VERSION ""

NS_ :

BS_:

BU_: Turbocharger OnBoardDataLogger OffBoardDiagnosticTool2 OffBoardDiagnosticTool1 FileServer ParkingBrakeController SeatController2 FanDriveController SteeringColumnUnit CommunicationUnitRadio CommunicationUnitSatellite CommunicationUnitCellular PropulsionBatteryCharger ChassisController2 ChassisController1 EngineValveControl AuxiliaryHeater2 AuxiliaryHeater1 ClutchUnit RampControl InformationSystem1 SuspensionSystemController2 OilSensor VehicleDynamicStability ExhaustEmissionController TransmissionDisplay2 TransmissionDisplay1 ClimateControl2 WaterPumpController RearAxleSteeringController LightingOperatorControl SeatController1 IgnitionController2 IgnitionController1 TirePressureController CabController2 CabController1 PneumaticSystemController SuspensionSystemController1 HydraulicPumpController EnduranceBrakingSystem RetarderExhaustEngine2 OnBoardDiagnosticUnit HeadwayController RetarderExhaustEngine1 CabDisplay1 ManagementComputer VirtualTerminal OffVehicleGateway PowerTakeOffFront HitchControl AuxiliaryValveControl BodyController TractorTrailerBridge1 StarterSystem ElectricalSystem VehicleSecurity VehicleNavigation AerodynamicControl ElectricalChargingSystem ClimateControl1 TripRecorder InstrumentCluster SuspensionDriveAxle2 SuspensionDriveAxle1 SuspensionSteerAxle SteeringController FuelSystem CruiseControl RetarderDriveline RetarderEngine BrakesDriveAxle2 BrakesDriveAxle1 BrakesSystemController BrakesSteerAxle AxleDrive2 AxleDrive1 AxleSteering PowerTakeOff ShiftConsoleSecondary ShiftConsolePrimary Transmission2 Transmission1 Engine2 Engine1

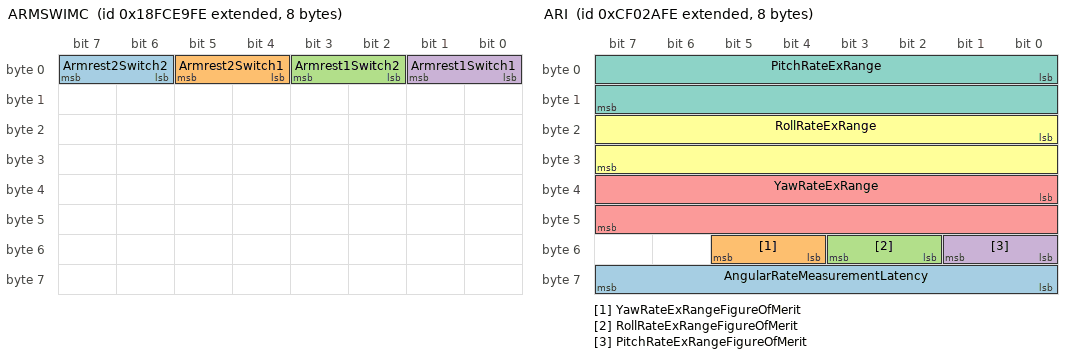
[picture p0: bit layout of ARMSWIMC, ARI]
BO_ 2566711806 ARMSWIMC: 8 Vector__XXX
 SG_ Armrest2Switch2 : 6|2@1+ (1,0) [0|3] "" Vector__XXX
 SG_ Armrest2Switch1 : 4|2@1+ (1,0) [0|3] "" Vector__XXX
 SG_ Armrest1Switch2 : 2|2@1+ (1,0) [0|3] "" Vector__XXX
 SG_ Armrest1Switch1 : 0|2@1+ (1,0) [0|3] "" Vector__XXX

BO_ 2364549886 ARI: 8 Vector__XXX
 SG_ AngularRateMeasurementLatency : 56|8@1+ (0.5,0) [0|125] "ms" Vector__XXX
 SG_ YawRateExRangeFigureOfMerit : 52|2@1+ (1,0) [0|3] "" Vector__XXX
 SG_ RollRateExRangeFigureOfMerit : 50|2@1+ (1,0) [0|3] "" Vector__XXX
 SG_ PitchRateExRangeFigureOfMerit : 48|2@1+ (1,0) [0|3] "" Vector__XXX
 SG_ YawRateExRange : 32|16@1+ (0.0078125,-250) [-250|250.992] "deg/sec" Vector__XXX
 SG_ RollRateExRange : 16|16@1+ (0.0078125,-250) [-250|250.992] "deg/sec" Vector__XXX
 SG_ PitchRateExRange : 0|16@1+ (0.0078125,-250) [-250|250.992] "deg/sec" Vector__XXX

BO_ 2566712318 AFT2NAI: 8 Vector__XXX
 SG_ Aftrtrtmnt2NOxAdsrbrDSOxRgnrtnSt : 2|2@1+ (1,0) [0|3] "" Vector__XXX
 SG_ Aftrtrtmnt2NOxAdsrbrDNOxRgnrtnSt : 0|2@1+ (1,0) [0|3] "" Vector__XXX

BO_ 2566712574 AFT1NAI: 8 Vector__XXX
 SG_ Aftrtrtmnt1NOxAdsrbrDSOxRgnrtnSt : 2|2@1+ (1,0) [0|3] "" Vector__XXX
 SG_ Aftrtrtmnt1NOxAdsrbrDNOxRgnrtnSt : 0|2@1+ (1,0) [0|3] "" Vector__XXX

BO_ 2164078590 A2SCRSI: 8 Vector__XXX
 SG_ Aftrtrtmnt2SCRCnvrsionEfficiency : 32|8@1+ (0.4,0) [0|100] "%" Vector__XXX
 SG_ Aftrtrtmnt2SCRCmmnddCtlystDslExh : 16|16@1+ (0.05,0) [0|3212.75] "L/h" Vector__XXX
 SG_ Aftrtrtmnt2DslExhstFldAvrgCnsmpt : 0|16@1+ (0.05,0) [0|3212.75] "L/h" Vector__XXX

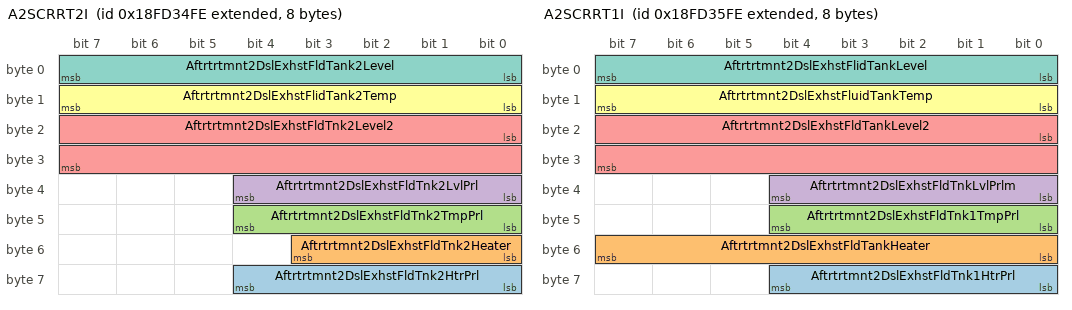
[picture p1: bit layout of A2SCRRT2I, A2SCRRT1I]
BO_ 2566731006 A2SCRRT2I: 8 Vector__XXX
 SG_ Aftrtrtmnt2DslExhstFldTnk2HtrPrl : 56|5@1+ (1,0) [0|31] "" Vector__XXX
 SG_ Aftrtrtmnt2DslExhstFldTnk2Heater : 48|4@1+ (1,0) [0|15] "" Vector__XXX
 SG_ Aftrtrtmnt2DslExhstFldTnk2TmpPrl : 40|5@1+ (1,0) [0|31] "" Vector__XXX
 SG_ Aftrtrtmnt2DslExhstFldTnk2LvlPrl : 32|5@1+ (1,0) [0|31] "" Vector__XXX
 SG_ Aftrtrtmnt2DslExhstFldTnk2Level2 : 16|16@1+ (0.1,0) [0|6425.5] "mm" Vector__XXX
 SG_ Aftrtrtmnt2DslExhstFlidTank2Temp : 8|8@1+ (1,-40) [-40|210] "deg C" Vector__XXX
 SG_ Aftrtrtmnt2DslExhstFldTank2Level : 0|8@1+ (0.4,0) [0|100] "%" Vector__XXX

BO_ 2566731262 A2SCRRT1I: 8 Vector__XXX
 SG_ Aftrtrtmnt2DslExhstFldTnk1HtrPrl : 56|5@1+ (1,0) [0|31] "" Vector__XXX
 SG_ Aftrtrtmnt2DslExhstFldTankHeater : 48|8@1+ (0.4,0) [0|100] "%" Vector__XXX
 SG_ Aftrtrtmnt2DslExhstFldTnk1TmpPrl : 40|5@1+ (1,0) [0|31] "" Vector__XXX
 SG_ Aftrtrtmnt2DslExhstFldTnkLvlPrlm : 32|5@1+ (1,0) [0|31] "" Vector__XXX
 SG_ Aftrtrtmnt2DslExhstFldTankLevel2 : 16|16@1+ (0.1,0) [0|6425.5] "mm" Vector__XXX
 SG_ Aftrtrtmnt2DslExhstFluidTankTemp : 8|8@1+ (1,-40) [-40|210] "deg C" Vector__XXX
 SG_ Aftrtrtmnt2DslExhstFlidTankLevel : 0|8@1+ (0.4,0) [0|100] "%" Vector__XXX

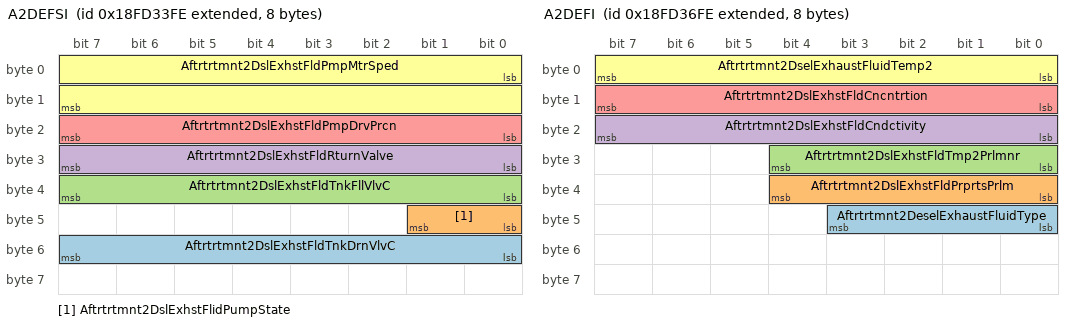
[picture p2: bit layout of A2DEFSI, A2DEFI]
BO_ 2566730750 A2DEFSI: 8 Vector__XXX
 SG_ Aftrtrtmnt2DslExhstFldTnkDrnVlvC : 48|8@1+ (0.4,0) [0|100] "%" Vector__XXX
 SG_ Aftrtrtmnt2DslExhstFlidPumpState : 40|2@1+ (1,0) [0|3] "" Vector__XXX
 SG_ Aftrtrtmnt2DslExhstFldTnkFllVlvC : 32|8@1+ (0.4,0) [0|100] "%" Vector__XXX
 SG_ Aftrtrtmnt2DslExhstFldRturnValve : 24|8@1+ (0.4,0) [0|100] "%" Vector__XXX
 SG_ Aftrtrtmnt2DslExhstFldPmpDrvPrcn : 16|8@1+ (0.4,0) [0|100] "%" Vector__XXX
 SG_ Aftrtrtmnt2DslExhstFldPmpMtrSped : 0|16@1+ (0.5,0) [0|32127.5] "rpm" Vector__XXX

BO_ 2566731518 A2DEFI: 8 Vector__XXX
 SG_ Aftrtrtmnt2DeselExhaustFluidType : 40|4@1+ (1,0) [0|15] "" Vector__XXX
 SG_ Aftrtrtmnt2DslExhstFldPrprtsPrlm : 32|5@1+ (1,0) [0|31] "" Vector__XXX
 SG_ Aftrtrtmnt2DslExhstFldTmp2Prlmnr : 24|5@1+ (1,0) [0|31] "" Vector__XXX
 SG_ Aftrtrtmnt2DslExhstFldCndctivity : 16|8@1+ (5,0) [0|1250] "microSiemens/mm" Vector__XXX
 SG_ Aftrtrtmnt2DslExhstFldCncntrtion : 8|8@1+ (0.25,0) [0|62.5] "%" Vector__XXX
 SG_ Aftrtrtmnt2DselExhaustFluidTemp2 : 0|8@1+ (1,-40) [-40|210] "deg C" Vector__XXX

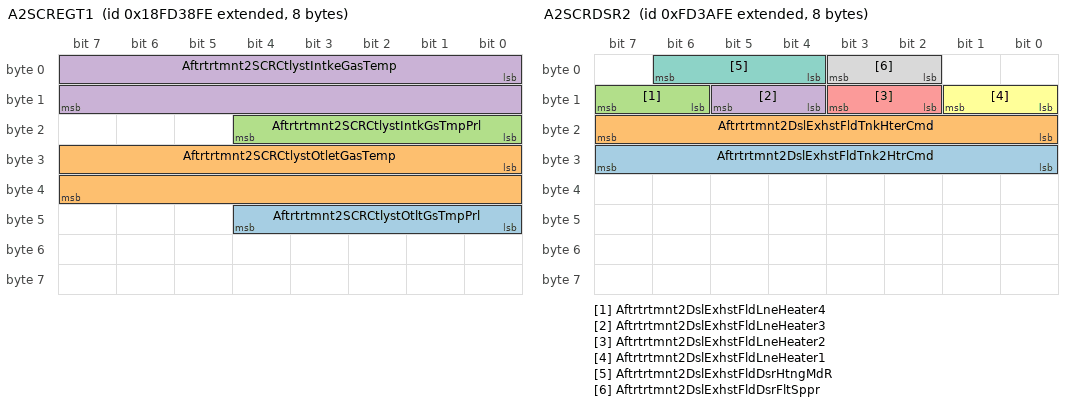
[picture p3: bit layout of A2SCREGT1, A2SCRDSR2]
BO_ 2566732030 A2SCREGT1: 8 Vector__XXX
 SG_ Aftrtrtmnt2SCRCtlystOtltGsTmpPrl : 40|5@1+ (1,0) [0|31] "" Vector__XXX
 SG_ Aftrtrtmnt2SCRCtlystOtletGasTemp : 24|16@1+ (0.03125,-273) [-273|1734.96875] "deg C" Vector__XXX
 SG_ Aftrtrtmnt2SCRCtlystIntkGsTmpPrl : 16|5@1+ (1,0) [0|31] "" Vector__XXX
 SG_ Aftrtrtmnt2SCRCtlystIntkeGasTemp : 0|16@1+ (0.03125,-273) [-273|1734.96875] "deg C" Vector__XXX

BO_ 2566732286 A2SCREGP: 8 Vector__XXX
 SG_ Aftrtrtmnt2SCRExhstGsDffPrssPrlm : 16|5@1+ (1,0) [0|31] "" Vector__XXX
 SG_ Aftrtrtmnt2SCRExhustGasDiffPress : 0|16@1+ (0.1,0) [0|6425.5] "kPa" Vector__XXX

BO_ 2164079358 A2SCRDSR2: 8 Vector__XXX
 SG_ Aftrtrtmnt2DslExhstFldTnk2HtrCmd : 24|8@1+ (0.4,0) [0|100] "%" Vector__XXX
 SG_ Aftrtrtmnt2DslExhstFldTnkHterCmd : 16|8@1+ (0.4,0) [0|100] "%" Vector__XXX
 SG_ Aftrtrtmnt2DslExhstFldLneHeater4 : 14|2@1+ (1,0) [0|3] "" Vector__XXX
 SG_ Aftrtrtmnt2DslExhstFldLneHeater3 : 12|2@1+ (1,0) [0|3] "" Vector__XXX
 SG_ Aftrtrtmnt2DslExhstFldLneHeater2 : 10|2@1+ (1,0) [0|3] "" Vector__XXX
 SG_ Aftrtrtmnt2DslExhstFldLneHeater1 : 8|2@1+ (1,0) [0|3] "" Vector__XXX
 SG_ Aftrtrtmnt2DslExhstFldDsrHtngMdR : 4|3@1+ (1,0) [0|7] "" Vector__XXX
 SG_ Aftrtrtmnt2DslExhstFldDsrFltSppr : 2|2@1+ (1,0) [0|3] "" Vector__XXX

BO_ 2364549118 A2SCRDSR1: 8 Vector__XXX
 SG_ Aftrtrtmnt2DslExhstFldRqstdQntty : 24|16@1+ (0.1,0) [0|6425.5] "g" Vector__XXX
 SG_ Aftrtrtmnt2SCRSystmRquestedState : 16|4@1+ (1,0) [0|15] "" Vector__XXX
 SG_ Aftrtrtmnt2DslExhstFldDsngRqstdQ : 0|16@1+ (0.3,0) [0|19276.5] "g/h" Vector__XXX

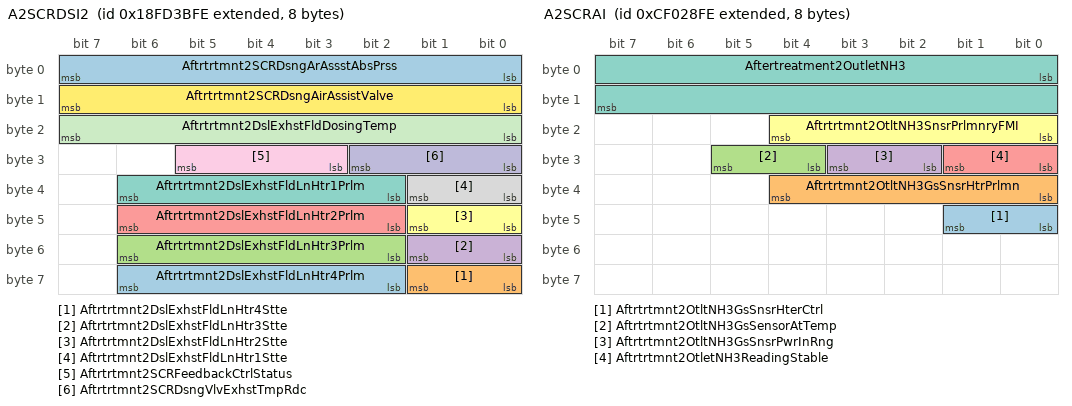
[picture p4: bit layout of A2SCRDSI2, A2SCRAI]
BO_ 2566732798 A2SCRDSI2: 8 Vector__XXX
 SG_ Aftrtrtmnt2DslExhstFldLnHtr4Prlm : 58|5@1+ (1,0) [0|31] "" Vector__XXX
 SG_ Aftrtrtmnt2DslExhstFldLnHtr4Stte : 56|2@1+ (1,0) [0|3] "" Vector__XXX
 SG_ Aftrtrtmnt2DslExhstFldLnHtr3Prlm : 50|5@1+ (1,0) [0|31] "" Vector__XXX
 SG_ Aftrtrtmnt2DslExhstFldLnHtr3Stte : 48|2@1+ (1,0) [0|3] "" Vector__XXX
 SG_ Aftrtrtmnt2DslExhstFldLnHtr2Prlm : 42|5@1+ (1,0) [0|31] "" Vector__XXX
 SG_ Aftrtrtmnt2DslExhstFldLnHtr2Stte : 40|2@1+ (1,0) [0|3] "" Vector__XXX
 SG_ Aftrtrtmnt2DslExhstFldLnHtr1Prlm : 34|5@1+ (1,0) [0|31] "" Vector__XXX
 SG_ Aftrtrtmnt2DslExhstFldLnHtr1Stte : 32|2@1+ (1,0) [0|3] "" Vector__XXX
 SG_ Aftrtrtmnt2SCRFeedbackCtrlStatus : 27|3@1+ (1,0) [0|7] "" Vector__XXX
 SG_ Aftrtrtmnt2SCRDsngVlvExhstTmpRdc : 24|3@1+ (1,0) [0|7] "" Vector__XXX
 SG_ Aftrtrtmnt2DslExhstFldDosingTemp : 16|8@1+ (1,-40) [-40|210] "deg C" Vector__XXX
 SG_ Aftrtrtmnt2SCRDsngAirAssistValve : 8|8@1+ (0.4,0) [0|100] "%" Vector__XXX
 SG_ Aftrtrtmnt2SCRDsngArAssstAbsPrss : 0|8@1+ (8,0) [0|2000] "kPa" Vector__XXX

BO_ 2364548862 A2SCRDSI1: 8 Vector__XXX
 SG_ Aftrtrtmnt2DslExhstFldDsngAbsPrs : 40|8@1+ (8,0) [0|2000] "kPa" Vector__XXX
 SG_ Aftrtrtmnt2DslExhstFldActlQnttyO : 24|16@1+ (0.1,0) [0|6425.5] "g" Vector__XXX
 SG_ Aftertreatment2SCRSystemState : 16|4@1+ (1,0) [0|15] "" Vector__XXX
 SG_ Aftrtrtmnt2DslExhstFldActlDsngQn : 0|16@1+ (0.3,0) [0|19276.5] "g/h" Vector__XXX

BO_ 2364549374 A2SCRAI: 8 Vector__XXX
 SG_ Aftrtrtmnt2OtltNH3GsSnsrHterCtrl : 40|2@1+ (1,0) [0|3] "" Vector__XXX
 SG_ Aftrtrtmnt2OtltNH3GsSnsrHtrPrlmn : 32|5@1+ (1,0) [0|31] "" Vector__XXX
 SG_ Aftrtrtmnt2OtltNH3GsSensorAtTemp : 28|2@1+ (1,0) [0|3] "" Vector__XXX
 SG_ Aftrtrtmnt2OtltNH3GsSnsrPwrInRng : 26|2@1+ (1,0) [0|3] "" Vector__XXX
 SG_ Aftrtrtmnt2OtletNH3ReadingStable : 24|2@1+ (1,0) [0|3] "" Vector__XXX
 SG_ Aftrtrtmnt2OtltNH3SnsrPrlmnryFMI : 16|5@1+ (1,0) [0|31] "" Vector__XXX
 SG_ Aftertreatment2OutletNH3 : 0|16@1+ (0.05,-200) [-200|3012.75] "ppm" Vector__XXX

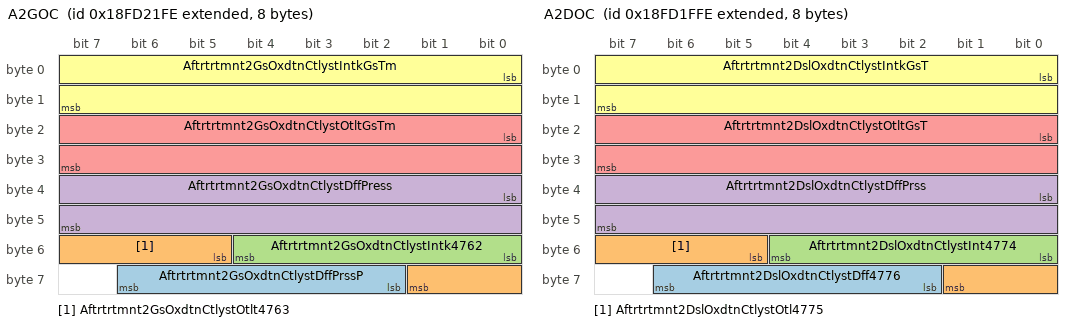
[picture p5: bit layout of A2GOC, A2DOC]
BO_ 2566726142 A2GOC: 8 Vector__XXX
 SG_ Aftrtrtmnt2GsOxdtnCtlystDffPrssP : 58|5@1+ (1,0) [0|31] "" Vector__XXX
 SG_ Aftrtrtmnt2GsOxdtnCtlystOtlt4763 : 53|5@1+ (1,0) [0|31] "" Vector__XXX
 SG_ Aftrtrtmnt2GsOxdtnCtlystIntk4762 : 48|5@1+ (1,0) [0|31] "" Vector__XXX
 SG_ Aftrtrtmnt2GsOxdtnCtlystDffPress : 32|16@1+ (0.1,0) [0|6425.5] "kPa" Vector__XXX
 SG_ Aftrtrtmnt2GsOxdtnCtlystOtltGsTm : 16|16@1+ (0.03125,-273) [-273|1734.96875] "deg C" Vector__XXX
 SG_ Aftrtrtmnt2GsOxdtnCtlystIntkGsTm : 0|16@1+ (0.03125,-273) [-273|1734.96875] "deg C" Vector__XXX

BO_ 2566725630 A2DOC: 8 Vector__XXX
 SG_ Aftrtrtmnt2DslOxdtnCtlystDff4776 : 58|5@1+ (1,0) [0|31] "" Vector__XXX
 SG_ Aftrtrtmnt2DslOxdtnCtlystOtl4775 : 53|5@1+ (1,0) [0|31] "" Vector__XXX
 SG_ Aftrtrtmnt2DslOxdtnCtlystInt4774 : 48|5@1+ (1,0) [0|31] "" Vector__XXX
 SG_ Aftrtrtmnt2DslOxdtnCtlystDffPrss : 32|16@1+ (0.5,0) [0|32127.5] "kPa" Vector__XXX
 SG_ Aftrtrtmnt2DslOxdtnCtlystOtltGsT : 16|16@1+ (0.03125,-273) [-273|1734.96875] "deg C" Vector__XXX
 SG_ Aftrtrtmnt2DslOxdtnCtlystIntkGsT : 0|16@1+ (0.03125,-273) [-273|1734.96875] "deg C" Vector__XXX

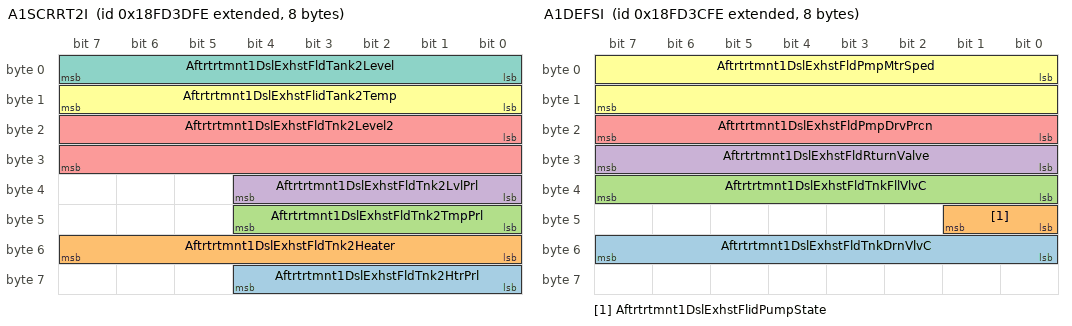
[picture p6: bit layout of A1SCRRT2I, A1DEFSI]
BO_ 2566733310 A1SCRRT2I: 8 Vector__XXX
 SG_ Aftrtrtmnt1DslExhstFldTnk2HtrPrl : 56|5@1+ (1,0) [0|31] "" Vector__XXX
 SG_ Aftrtrtmnt1DslExhstFldTnk2Heater : 48|8@1+ (0.4,0) [0|100] "%" Vector__XXX
 SG_ Aftrtrtmnt1DslExhstFldTnk2TmpPrl : 40|5@1+ (1,0) [0|31] "" Vector__XXX
 SG_ Aftrtrtmnt1DslExhstFldTnk2LvlPrl : 32|5@1+ (1,0) [0|31] "" Vector__XXX
 SG_ Aftrtrtmnt1DslExhstFldTnk2Level2 : 16|16@1+ (0.1,0) [0|6425.5] "mm" Vector__XXX
 SG_ Aftrtrtmnt1DslExhstFlidTank2Temp : 8|8@1+ (1,-40) [-40|210] "deg C" Vector__XXX
 SG_ Aftrtrtmnt1DslExhstFldTank2Level : 0|8@1+ (0.4,0) [0|100] "%" Vector__XXX

BO_ 2566733054 A1DEFSI: 8 Vector__XXX
 SG_ Aftrtrtmnt1DslExhstFldTnkDrnVlvC : 48|8@1+ (0.4,0) [0|100] "%" Vector__XXX
 SG_ Aftrtrtmnt1DslExhstFlidPumpState : 40|2@1+ (1,0) [0|3] "" Vector__XXX
 SG_ Aftrtrtmnt1DslExhstFldTnkFllVlvC : 32|8@1+ (0.4,0) [0|100] "%" Vector__XXX
 SG_ Aftrtrtmnt1DslExhstFldRturnValve : 24|8@1+ (0.4,0) [0|100] "%" Vector__XXX
 SG_ Aftrtrtmnt1DslExhstFldPmpDrvPrcn : 16|8@1+ (0.4,0) [0|100] "%" Vector__XXX
 SG_ Aftrtrtmnt1DslExhstFldPmpMtrSped : 0|16@1+ (0.5,0) [0|32127.5] "rpm" Vector__XXX

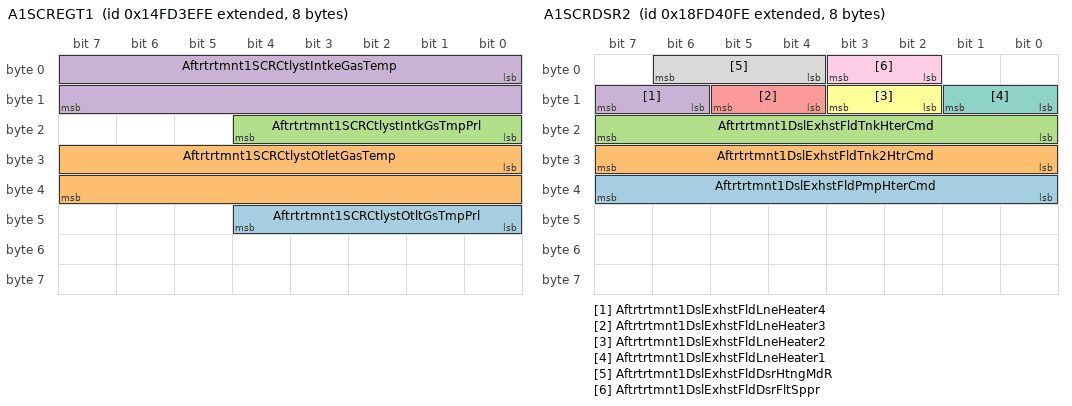
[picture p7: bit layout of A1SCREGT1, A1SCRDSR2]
BO_ 2499624702 A1SCREGT1: 8 Vector__XXX
 SG_ Aftrtrtmnt1SCRCtlystOtltGsTmpPrl : 40|5@1+ (1,0) [0|31] "" Vector__XXX
 SG_ Aftrtrtmnt1SCRCtlystOtletGasTemp : 24|16@1+ (0.03125,-273) [-273|1734.96875] "deg C" Vector__XXX
 SG_ Aftrtrtmnt1SCRCtlystIntkGsTmpPrl : 16|5@1+ (1,0) [0|31] "" Vector__XXX
 SG_ Aftrtrtmnt1SCRCtlystIntkeGasTemp : 0|16@1+ (0.03125,-273) [-273|1734.96875] "deg C" Vector__XXX

BO_ 2566733822 A1SCREGP: 8 Vector__XXX
 SG_ Aftrtrtmnt1SCRExhstGsDffPrssPrlm : 16|5@1+ (1,0) [0|31] "" Vector__XXX
 SG_ Aftrtrtmnt1SCRExhustGasDiffPress : 0|16@1+ (0.1,0) [0|6425.5] "kPa" Vector__XXX

BO_ 2566734078 A1SCRDSR2: 8 Vector__XXX
 SG_ Aftrtrtmnt1DslExhstFldPmpHterCmd : 32|8@1+ (0.4,0) [0|100] "%" Vector__XXX
 SG_ Aftrtrtmnt1DslExhstFldTnk2HtrCmd : 24|8@1+ (0.4,0) [0|100] "%" Vector__XXX
 SG_ Aftrtrtmnt1DslExhstFldTnkHterCmd : 16|8@1+ (0.4,0) [0|100] "%" Vector__XXX
 SG_ Aftrtrtmnt1DslExhstFldLneHeater4 : 14|2@1+ (1,0) [0|3] "" Vector__XXX
 SG_ Aftrtrtmnt1DslExhstFldLneHeater3 : 12|2@1+ (1,0) [0|3] "" Vector__XXX
 SG_ Aftrtrtmnt1DslExhstFldLneHeater2 : 10|2@1+ (1,0) [0|3] "" Vector__XXX
 SG_ Aftrtrtmnt1DslExhstFldLneHeater1 : 8|2@1+ (1,0) [0|3] "" Vector__XXX
 SG_ Aftrtrtmnt1DslExhstFldDsrHtngMdR : 4|3@1+ (1,0) [0|7] "" Vector__XXX
 SG_ Aftrtrtmnt1DslExhstFldDsrFltSppr : 2|2@1+ (1,0) [0|3] "" Vector__XXX

BO_ 2364548350 A1SCRDSR1: 8 Vector__XXX
 SG_ Aftrtrtmnt1DslExhstFldRqstdQntty : 24|16@1+ (0.1,0) [0|6425.5] "g" Vector__XXX
 SG_ Aftrtrtmnt1SCRSystmRquestedState : 16|4@1+ (1,0) [0|15] "" Vector__XXX
 SG_ Aftrtrtmnt1DslExhstFldDsngRqstdQ : 0|16@1+ (0.3,0) [0|19276.5] "g/h" Vector__XXX

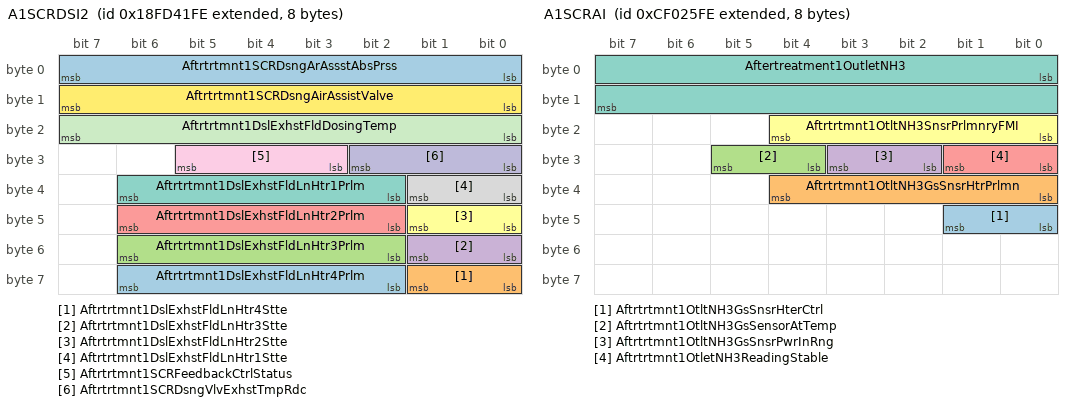
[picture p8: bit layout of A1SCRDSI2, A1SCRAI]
BO_ 2566734334 A1SCRDSI2: 8 Vector__XXX
 SG_ Aftrtrtmnt1DslExhstFldLnHtr4Prlm : 58|5@1+ (1,0) [0|31] "" Vector__XXX
 SG_ Aftrtrtmnt1DslExhstFldLnHtr4Stte : 56|2@1+ (1,0) [0|3] "" Vector__XXX
 SG_ Aftrtrtmnt1DslExhstFldLnHtr3Prlm : 50|5@1+ (1,0) [0|31] "" Vector__XXX
 SG_ Aftrtrtmnt1DslExhstFldLnHtr3Stte : 48|2@1+ (1,0) [0|3] "" Vector__XXX
 SG_ Aftrtrtmnt1DslExhstFldLnHtr2Prlm : 42|5@1+ (1,0) [0|31] "" Vector__XXX
 SG_ Aftrtrtmnt1DslExhstFldLnHtr2Stte : 40|2@1+ (1,0) [0|3] "" Vector__XXX
 SG_ Aftrtrtmnt1DslExhstFldLnHtr1Prlm : 34|5@1+ (1,0) [0|31] "" Vector__XXX
 SG_ Aftrtrtmnt1DslExhstFldLnHtr1Stte : 32|2@1+ (1,0) [0|3] "" Vector__XXX
 SG_ Aftrtrtmnt1SCRFeedbackCtrlStatus : 27|3@1+ (1,0) [0|7] "" Vector__XXX
 SG_ Aftrtrtmnt1SCRDsngVlvExhstTmpRdc : 24|3@1+ (1,0) [0|7] "" Vector__XXX
 SG_ Aftrtrtmnt1DslExhstFldDosingTemp : 16|8@1+ (1,-40) [-40|210] "deg C" Vector__XXX
 SG_ Aftrtrtmnt1SCRDsngAirAssistValve : 8|8@1+ (0.4,0) [0|100] "%" Vector__XXX
 SG_ Aftrtrtmnt1SCRDsngArAssstAbsPrss : 0|8@1+ (8,0) [0|2000] "kPa" Vector__XXX

BO_ 2364548094 A1SCRDSI1: 8 Vector__XXX
 SG_ Aftrtrtmnt1DslExhstFldDsrAbsPrss : 40|8@1+ (8,0) [0|2000] "kPa" Vector__XXX
 SG_ Aftrtrtmnt1DslExhstFldActlQnttyO : 24|16@1+ (0.1,0) [0|6425.5] "g" Vector__XXX
 SG_ Aftertreatment1SCRSystemState : 16|4@1+ (1,0) [0|15] "" Vector__XXX
 SG_ Aftrtrtmnt1DslExhstFldActlDsngQn : 0|16@1+ (0.3,0) [0|19276.5] "g/h" Vector__XXX

BO_ 2364548606 A1SCRAI: 8 Vector__XXX
 SG_ Aftrtrtmnt1OtltNH3GsSnsrHterCtrl : 40|2@1+ (1,0) [0|3] "" Vector__XXX
 SG_ Aftrtrtmnt1OtltNH3GsSnsrHtrPrlmn : 32|5@1+ (1,0) [0|31] "" Vector__XXX
 SG_ Aftrtrtmnt1OtltNH3GsSensorAtTemp : 28|2@1+ (1,0) [0|3] "" Vector__XXX
 SG_ Aftrtrtmnt1OtltNH3GsSnsrPwrInRng : 26|2@1+ (1,0) [0|3] "" Vector__XXX
 SG_ Aftrtrtmnt1OtletNH3ReadingStable : 24|2@1+ (1,0) [0|3] "" Vector__XXX
 SG_ Aftrtrtmnt1OtltNH3SnsrPrlmnryFMI : 16|5@1+ (1,0) [0|31] "" Vector__XXX
 SG_ Aftertreatment1OutletNH3 : 0|16@1+ (0.05,-200) [-200|3012.75] "ppm" Vector__XXX

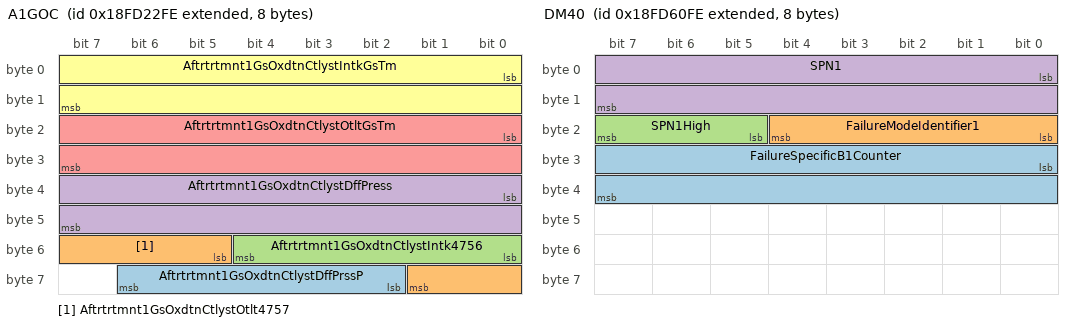
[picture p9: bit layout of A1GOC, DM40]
BO_ 2566726398 A1GOC: 8 Vector__XXX
 SG_ Aftrtrtmnt1GsOxdtnCtlystDffPrssP : 58|5@1+ (1,0) [0|31] "" Vector__XXX
 SG_ Aftrtrtmnt1GsOxdtnCtlystOtlt4757 : 53|5@1+ (1,0) [0|31] "" Vector__XXX
 SG_ Aftrtrtmnt1GsOxdtnCtlystIntk4756 : 48|5@1+ (1,0) [0|31] "" Vector__XXX
 SG_ Aftrtrtmnt1GsOxdtnCtlystDffPress : 32|16@1+ (0.1,0) [0|6425.5] "kPa" Vector__XXX
 SG_ Aftrtrtmnt1GsOxdtnCtlystOtltGsTm : 16|16@1+ (0.03125,-273) [-273|1734.96875] "deg C" Vector__XXX
 SG_ Aftrtrtmnt1GsOxdtnCtlystIntkGsTm : 0|16@1+ (0.03125,-273) [-273|1734.96875] "deg C" Vector__XXX

BO_ 2566742270 DM40: 8 Vector__XXX
 SG_ FailureSpecificB1Counter : 24|16@1+ (0.1,0) [0|6425.5] "hr" Vector__XXX
 SG_ FailureModeIdentifier1 : 16|5@1+ (1,0) [0|0] "" Vector__XXX
 SG_ SPN1High : 21|3@1+ (1,0) [0|7] "" Vector__XXX
 SG_ SPN1 : 0|16@1+ (1,0) [0|65536] "" Vector__XXX

BO_ 2566742526 DM39: 8 Vector__XXX
 SG_ SysGreatestB1Counter : 32|16@1+ (0.1,0) [0|6425.5] "hr" Vector__XXX
 SG_ SysCumulativeContinuousMITime : 0|32@1+ (0.05,0) [0|210554060.75] "hr" Vector__XXX

BO_ 2566742782 DM38: 8 Vector__XXX
 SG_ RegulationDescription : 0|8@1+ (1,0) [0|255] "" Vector__XXX

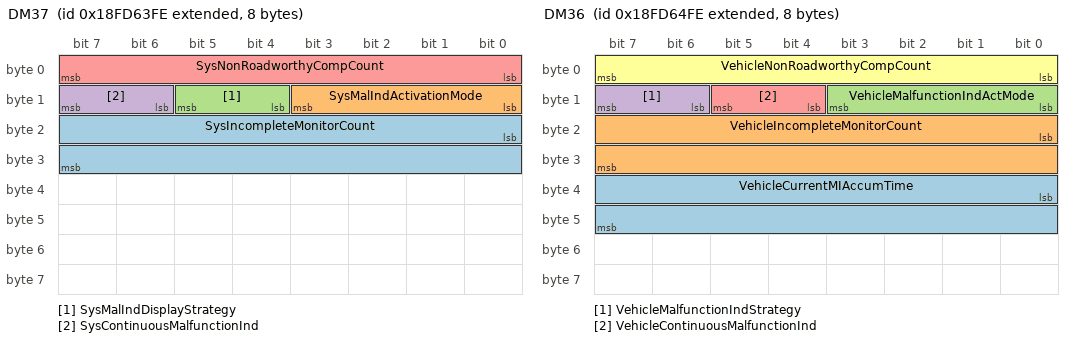
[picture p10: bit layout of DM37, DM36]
BO_ 2566743038 DM37: 8 Vector__XXX
 SG_ SysIncompleteMonitorCount : 16|16@1+ (1,0) [0|64512] "" Vector__XXX
 SG_ SysMalIndActivationMode : 8|4@1+ (1,0) [0|15] "" Vector__XXX
 SG_ SysMalIndDisplayStrategy : 12|2@1+ (1,0) [0|3] "" Vector__XXX
 SG_ SysContinuousMalfunctionInd : 14|2@1+ (1,0) [0|3] "" Vector__XXX
 SG_ SysNonRoadworthyCompCount : 0|8@1+ (1,0) [0|250] "" Vector__XXX

BO_ 2566743294 DM36: 8 Vector__XXX
 SG_ VehicleCurrentMIAccumTime : 32|16@1+ (1,0) [0|64255] "min" Vector__XXX
 SG_ VehicleIncompleteMonitorCount : 16|16@1+ (1,0) [0|64255] "" Vector__XXX
 SG_ VehicleMalfunctionIndActMode : 8|4@1+ (1,0) [0|15] "" Vector__XXX
 SG_ VehicleMalfunctionIndStrategy : 14|2@1+ (1,0) [0|3] "" Vector__XXX
 SG_ VehicleContinuousMalfunctionInd : 12|2@1+ (1,0) [0|3] "" Vector__XXX
 SG_ VehicleNonRoadworthyCompCount : 0|8@1+ (1,0) [0|250] "" Vector__XXX

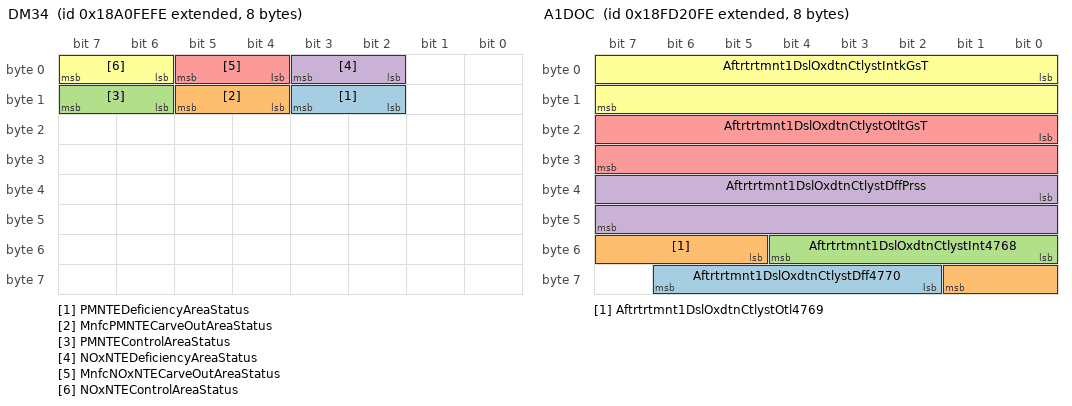
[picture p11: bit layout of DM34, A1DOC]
BO_ 2560687870 DM34: 8 Vector__XXX
 SG_ PMNTEDeficiencyAreaStatus : 10|2@1+ (1,0) [0|3] "" Vector__XXX
 SG_ MnfcPMNTECarveOutAreaStatus : 12|2@1+ (1,0) [0|3] "" Vector__XXX
 SG_ PMNTEControlAreaStatus : 14|2@1+ (1,0) [0|3] "" Vector__XXX
 SG_ NOxNTEDeficiencyAreaStatus : 2|2@1+ (1,0) [0|3] "" Vector__XXX
 SG_ MnfcNOxNTECarveOutAreaStatus : 4|2@1+ (1,0) [0|3] "" Vector__XXX
 SG_ NOxNTEControlAreaStatus : 6|2@1+ (1,0) [0|3] "" Vector__XXX

BO_ 2292317950 DM33: 9 Vector__XXX
 SG_ AECDEngineHours1Timer2 : 40|32@1+ (1,0) [0|4294967295] "min" Vector__XXX
 SG_ AECDEngineHours1Timer1 : 8|32@1+ (1,0) [0|4294967295] "min" Vector__XXX
 SG_ AECDNumber1 : 0|8@1+ (1,0) [0|250] "" Vector__XXX

BO_ 2566809342 BM: 8 Vector__XXX
 SG_ BatteryMainSwitchHoldState : 0|2@1+ (1,0) [0|3] "" Vector__XXX

BO_ 2365446910 BJM3: 8 Vector__XXX
 SG_ Joystick3XAxisDetentPosStatus : 38|2@1+ (1,0) [0|3] "" Vector__XXX
 SG_ Joystick3Button9PressedStatus : 62|2@1+ (1,0) [0|3] "" Vector__XXX
 SG_ Joystick3Button10PressedStatus : 60|2@1+ (1,0) [0|3] "" Vector__XXX
 SG_ Joystick3Button11PressedStatus : 58|2@1+ (1,0) [0|3] "" Vector__XXX
 SG_ Joystick3Button12PressedStatus : 56|2@1+ (1,0) [0|3] "" Vector__XXX
 SG_ Joystick3YAxisDetentPosStatus : 36|2@1+ (1,0) [0|3] "" Vector__XXX
 SG_ Joystick3YAxisPos : 22|10@1+ (0.1,0) [0|102] "%" Vector__XXX
 SG_ Jystck3YAxsLvrFrwrdPstvPosStatus : 20|2@1+ (1,0) [0|3] "" Vector__XXX
 SG_ Jystck3YAxsLvrBckNgtivePosStatus : 18|2@1+ (1,0) [0|3] "" Vector__XXX
 SG_ Joystick3YAxisNeutralPosStatus : 16|2@1+ (1,0) [0|3] "" Vector__XXX
 SG_ Joystick3XAxisPos : 6|10@1+ (0.1,0) [0|102] "%" Vector__XXX
 SG_ Jystck3XAxsLvrRghtPstvePosStatus : 4|2@1+ (1,0) [0|3] "" Vector__XXX
 SG_ Jystck3XAxsLvrLftNgtivePosStatus : 2|2@1+ (1,0) [0|3] "" Vector__XXX
 SG_ Joystick3XAxisNeutralPosStatus : 0|2@1+ (1,0) [0|3] "" Vector__XXX
 SG_ Joystick3Button5PressedStatus : 54|2@1+ (1,0) [0|3] "" Vector__XXX
 SG_ Joystick3Button6PressedStatus : 52|2@1+ (1,0) [0|3] "" Vector__XXX
 SG_ Joystick3Button7PressedStatus : 50|2@1+ (1,0) [0|3] "" Vector__XXX
 SG_ Joystick3Button8PressedStatus : 48|2@1+ (1,0) [0|3] "" Vector__XXX
 SG_ Joystick3Button1PressedStatus : 46|2@1+ (1,0) [0|3] "" Vector__XXX
 SG_ Joystick3Button2PressedStatus : 44|2@1+ (1,0) [0|3] "" Vector__XXX
 SG_ Joystick3Button3PressedStatus : 42|2@1+ (1,0) [0|3] "" Vector__XXX
 SG_ Joystick3Button4PressedStatus : 40|2@1+ (1,0) [0|3] "" Vector__XXX

BO_ 2365446398 BJM2: 8 Vector__XXX
 SG_ Joystick2XAxisDetentPosStatus : 38|2@1+ (1,0) [0|3] "" Vector__XXX
 SG_ Joystick2YAxisDetentPosStatus : 36|2@1+ (1,0) [0|3] "" Vector__XXX
 SG_ Joystick2YAxisPos : 22|10@1+ (0.1,0) [0|102] "%" Vector__XXX
 SG_ Jystck2YAxsLvrFrwrdPstvPosStatus : 20|2@1+ (1,0) [0|3] "" Vector__XXX
 SG_ Jystck2YAxsLvrBckNgtivePosStatus : 18|2@1+ (1,0) [0|3] "" Vector__XXX
 SG_ Joystick2YAxisNeutralPosStatus : 16|2@1+ (1,0) [0|3] "" Vector__XXX
 SG_ Joystick2XAxisPos : 6|10@1+ (0.1,0) [0|102] "%" Vector__XXX
 SG_ Jystck2XAxsLvrRghtPstvePosStatus : 4|2@1+ (1,0) [0|3] "" Vector__XXX
 SG_ Jystck2XAxsLvrLftNgtivePosStatus : 2|2@1+ (1,0) [0|3] "" Vector__XXX
 SG_ Joystick2XAxisNeutralPosStatus : 0|2@1+ (1,0) [0|3] "" Vector__XXX
 SG_ Joystick2Button9PressedStatus : 62|2@1+ (1,0) [0|3] "" Vector__XXX
 SG_ Joystick2Button10PressedStatus : 60|2@1+ (1,0) [0|3] "" Vector__XXX
 SG_ Joystick2Button11PressedStatus : 58|2@1+ (1,0) [0|3] "" Vector__XXX
 SG_ Joystick2Button12PressedStatus : 56|2@1+ (1,0) [0|3] "" Vector__XXX
 SG_ Joystick2Button5PressedStatus : 54|2@1+ (1,0) [0|3] "" Vector__XXX
 SG_ Joystick2Button6PressedStatus : 52|2@1+ (1,0) [0|3] "" Vector__XXX
 SG_ Joystick2Button7PressedStatus : 50|2@1+ (1,0) [0|3] "" Vector__XXX
 SG_ Joystick2Button8PressedStatus : 48|2@1+ (1,0) [0|3] "" Vector__XXX
 SG_ Joystick2Button1PressedStatus : 46|2@1+ (1,0) [0|3] "" Vector__XXX
 SG_ Joystick2Button2PressedStatus : 44|2@1+ (1,0) [0|3] "" Vector__XXX
 SG_ Joystick2Button3PressedStatus : 42|2@1+ (1,0) [0|3] "" Vector__XXX
 SG_ Joystick2Button4PressedStatus : 40|2@1+ (1,0) [0|3] "" Vector__XXX

BO_ 2365445886 BJM1: 8 Vector__XXX
 SG_ Joystick1XAxisDetentPosStatus : 38|2@1+ (1,0) [0|3] "" Vector__XXX
 SG_ Joystick1YAxisDetentPosStatus : 36|2@1+ (1,0) [0|3] "" Vector__XXX
 SG_ Joystick1YAxisPos : 22|10@1+ (0.1,0) [0|102] "%" Vector__XXX
 SG_ Jystck1YAxsLvrFrwrdPstvPosStatus : 20|2@1+ (1,0) [0|3] "" Vector__XXX
 SG_ Jystck1YAxsLvrBckNgtivePosStatus : 18|2@1+ (1,0) [0|3] "" Vector__XXX
 SG_ Joystick1YAxisNeutralPosStatus : 16|2@1+ (1,0) [0|3] "" Vector__XXX
 SG_ Joystick1XAxisPos : 6|10@1+ (0.1,0) [0|102] "%" Vector__XXX
 SG_ Joystick1Button9PressedStatus : 62|2@1+ (1,0) [0|3] "" Vector__XXX
 SG_ Joystick1Button10PressedStatus : 60|2@1+ (1,0) [0|3] "" Vector__XXX
 SG_ Joystick1Button11PressedStatus : 58|2@1+ (1,0) [0|3] "" Vector__XXX
 SG_ Joystick1Button12PressedStatus : 56|2@1+ (1,0) [0|3] "" Vector__XXX
 SG_ Joystick1Button5PressedStatus : 54|2@1+ (1,0) [0|3] "" Vector__XXX
 SG_ Joystick1Button6PressedStatus : 52|2@1+ (1,0) [0|3] "" Vector__XXX
 SG_ Joystick1Button7PressedStatus : 50|2@1+ (1,0) [0|3] "" Vector__XXX
 SG_ Joystick1Button8PressedStatus : 48|2@1+ (1,0) [0|3] "" Vector__XXX
 SG_ Joystick1Button1PressedStatus : 46|2@1+ (1,0) [0|3] "" Vector__XXX
 SG_ Joystick1Button2PressedStatus : 44|2@1+ (1,0) [0|3] "" Vector__XXX
 SG_ Joystick1Button3PressedStatus : 42|2@1+ (1,0) [0|3] "" Vector__XXX
 SG_ Joystick1Button4PressedStatus : 40|2@1+ (1,0) [0|3] "" Vector__XXX
 SG_ Jystck1XAxsLvrRghtPstvePosStatus : 4|2@1+ (1,0) [0|3] "" Vector__XXX
 SG_ Jystck1XAxsLvrLftNgtivePosStatus : 2|2@1+ (1,0) [0|3] "" Vector__XXX
 SG_ Joystick1XAxisNeutralPosStatus : 0|2@1+ (1,0) [0|3] "" Vector__XXX

BO_ 2566847230 B: 8 Vector__XXX
 SG_ ParkingBrakeRedWarningSignal : 26|2@1+ (1,0) [0|3] "" Vector__XXX
 SG_ ParkBrakeReleaseInhibitStatus : 28|2@1+ (1,0) [0|3] "" Vector__XXX
 SG_ ParkingBrakeActuator : 24|2@1+ (1,0) [0|3] "" Vector__XXX
 SG_ BrakeSecondPress : 16|8@1+ (4,0) [0|1000] "kPa" Vector__XXX
 SG_ BrakePrimaryPress : 8|8@1+ (4,0) [0|1000] "kPa" Vector__XXX
 SG_ BrakeAppPress : 0|8@1+ (4,0) [0|1000] "kPa" Vector__XXX

BO_ 2566848254 AWPP: 8 Vector__XXX
 SG_ AuxPumpPress : 0|8@1+ (16,0) [0|4000] "kPa" Vector__XXX

BO_ 2566725886 A1DOC: 8 Vector__XXX
 SG_ Aftrtrtmnt1DslOxdtnCtlystDff4770 : 58|5@1+ (1,0) [0|31] "" Vector__XXX
 SG_ Aftrtrtmnt1DslOxdtnCtlystOtl4769 : 53|5@1+ (1,0) [0|31] "" Vector__XXX
 SG_ Aftrtrtmnt1DslOxdtnCtlystInt4768 : 48|5@1+ (1,0) [0|31] "" Vector__XXX
 SG_ Aftrtrtmnt1DslOxdtnCtlystDffPrss : 32|16@1+ (0.1,0) [0|6425.5] "kPa" Vector__XXX
 SG_ Aftrtrtmnt1DslOxdtnCtlystOtltGsT : 16|16@1+ (0.03125,-273) [-273|1734.96875] "deg C" Vector__XXX
 SG_ Aftrtrtmnt1DslOxdtnCtlystIntkGsT : 0|16@1+ (0.03125,-273) [-273|1734.96875] "deg C" Vector__XXX

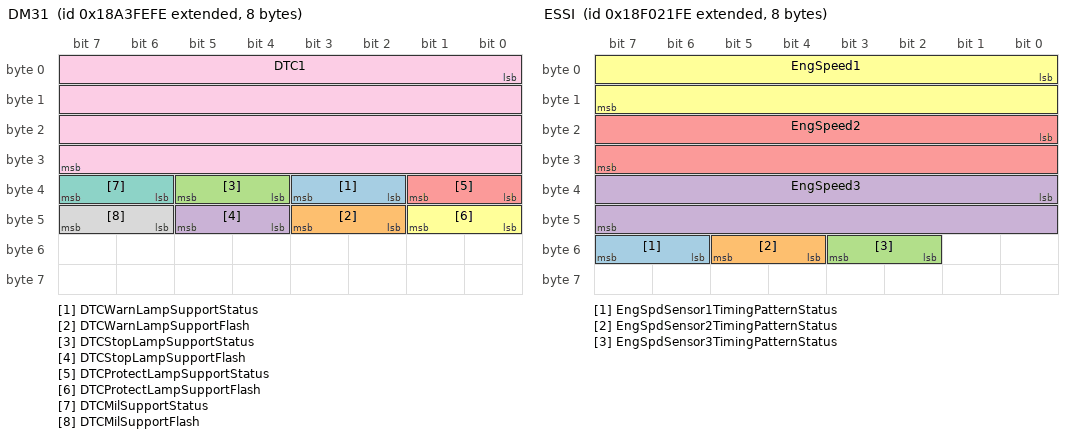
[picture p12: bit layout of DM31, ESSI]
BO_ 2560884478 DM31: 8 Vector__XXX
 SG_ DTCWarnLampSupportStatus : 34|2@1+ (1,0) [0|3] "" Vector__XXX
 SG_ DTCWarnLampSupportFlash : 42|2@1+ (1,0) [0|3] "" Vector__XXX
 SG_ DTCStopLampSupportStatus : 36|2@1+ (1,0) [0|3] "" Vector__XXX
 SG_ DTCStopLampSupportFlash : 44|2@1+ (1,0) [0|3] "" Vector__XXX
 SG_ DTCProtectLampSupportStatus : 32|2@1+ (1,0) [0|3] "" Vector__XXX
 SG_ DTCProtectLampSupportFlash : 40|2@1+ (1,0) [0|3] "" Vector__XXX
 SG_ DTCMilSupportStatus : 38|2@1+ (1,0) [0|3] "" Vector__XXX
 SG_ DTCMilSupportFlash : 46|2@1+ (1,0) [0|3] "" Vector__XXX
 SG_ DTC1 : 0|32@1+ (1,0) [0|4294967295] "" Vector__XXX

BO_ 2633844734 TML: 8 Vector__XXX

BO_ 2560360190 PMI: 8 Vector__XXX
 SG_ DataDictionaryMethod : 11|21@1+ (1,0) [0|2097151] "" Vector__XXX
 SG_ DataDictionaryManufacturerCode : 0|11@1+ (1,0) [0|2047] "" Vector__XXX

BO_ 2566736126 O2FT2: 8 Vector__XXX
 SG_ EngExhstGsOxygnSnsrClsdLpOprtnBn : 32|4@1+ (1,0) [0|15] "" Vector__XXX
 SG_ ShorttermFuelTrimBank2 : 16|16@1+ (0.1,-100) [-100|100] "%" Vector__XXX
 SG_ LongtermFuelTrimBank2 : 0|16@1+ (0.1,-100) [-100|100] "%" Vector__XXX

BO_ 2566736382 O2FT1: 8 Vector__XXX
 SG_ EngExhstGsOxygnSnsrClsdLpOprtnBn : 32|4@1+ (1,0) [0|15] "" Vector__XXX
 SG_ ShorttermFuelTrimBank1 : 16|16@1+ (0.1,-100) [-100|100] "%" Vector__XXX
 SG_ LongtermFuelTrimBank1 : 0|16@1+ (0.1,-100) [-100|100] "%" Vector__XXX

BO_ 2565874174 ESSI: 8 Vector__XXX
 SG_ EngSpdSensor1TimingPatternStatus : 54|2@1+ (1,0) [0|3] "" Vector__XXX
 SG_ EngSpdSensor2TimingPatternStatus : 52|2@1+ (1,0) [0|3] "" Vector__XXX
 SG_ EngSpdSensor3TimingPatternStatus : 50|2@1+ (1,0) [0|3] "" Vector__XXX
 SG_ EngSpeed3 : 32|16@1+ (0.5,0) [0|32127.5] "rpm" Vector__XXX
 SG_ EngSpeed2 : 16|16@1+ (0.5,0) [0|32127.5] "rpm" Vector__XXX
 SG_ EngSpeed1 : 0|16@1+ (0.5,0) [0|32127.5] "rpm" Vector__XXX

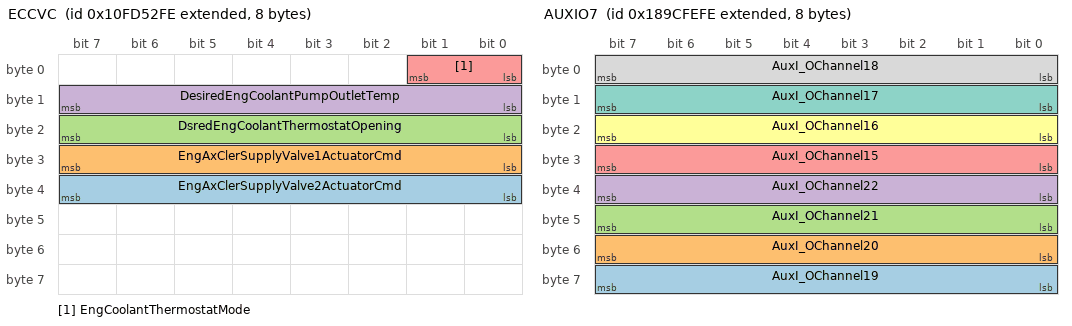
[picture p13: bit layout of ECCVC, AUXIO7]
BO_ 2432520958 ECCVC: 8 Vector__XXX
 SG_ EngAxClerSupplyValve2ActuatorCmd : 32|8@1+ (0.4,0) [0|100] "%" Vector__XXX
 SG_ EngAxClerSupplyValve1ActuatorCmd : 24|8@1+ (0.4,0) [0|100] "%" Vector__XXX
 SG_ DsredEngCoolantThermostatOpening : 16|8@1+ (0.4,0) [0|100] "%" Vector__XXX
 SG_ DesiredEngCoolantPumpOutletTemp : 8|8@1+ (1,-40) [-40|210] "deg C" Vector__XXX
 SG_ EngCoolantThermostatMode : 0|2@1+ (1,0) [0|3] "" Vector__XXX

BO_ 2560425726 AUXIO7: 8 Vector__XXX
 SG_ AuxI_OChannel19 : 56|8@1+ (1,0) [0|250] "" Vector__XXX
 SG_ AuxI_OChannel20 : 48|8@1+ (1,0) [0|250] "" Vector__XXX
 SG_ AuxI_OChannel21 : 40|8@1+ (1,0) [0|250] "" Vector__XXX
 SG_ AuxI_OChannel22 : 32|8@1+ (1,0) [0|250] "" Vector__XXX
 SG_ AuxI_OChannel15 : 24|8@1+ (1,0) [0|250] "" Vector__XXX
 SG_ AuxI_OChannel16 : 16|8@1+ (1,0) [0|250] "" Vector__XXX
 SG_ AuxI_OChannel17 : 8|8@1+ (1,0) [0|250] "" Vector__XXX
 SG_ AuxI_OChannel18 : 0|8@1+ (1,0) [0|250] "" Vector__XXX

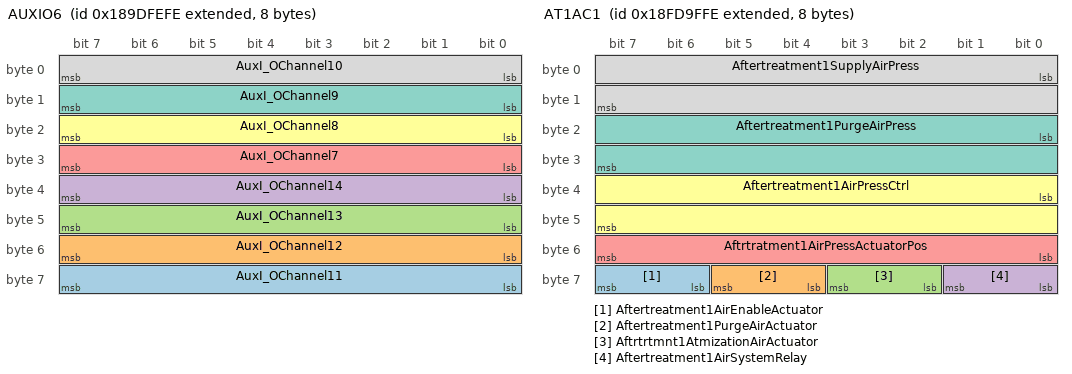
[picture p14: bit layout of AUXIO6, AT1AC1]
BO_ 2560491262 AUXIO6: 8 Vector__XXX
 SG_ AuxI_OChannel11 : 56|8@1+ (1,0) [0|250] "" Vector__XXX
 SG_ AuxI_OChannel12 : 48|8@1+ (1,0) [0|250] "" Vector__XXX
 SG_ AuxI_OChannel13 : 40|8@1+ (1,0) [0|250] "" Vector__XXX
 SG_ AuxI_OChannel14 : 32|8@1+ (1,0) [0|250] "" Vector__XXX
 SG_ AuxI_OChannel7 : 24|8@1+ (1,0) [0|250] "" Vector__XXX
 SG_ AuxI_OChannel8 : 16|8@1+ (1,0) [0|250] "" Vector__XXX
 SG_ AuxI_OChannel9 : 8|8@1+ (1,0) [0|250] "" Vector__XXX
 SG_ AuxI_OChannel10 : 0|8@1+ (1,0) [0|250] "" Vector__XXX

BO_ 2349399806 AUXIO5: 8 Vector__XXX
 SG_ AuxI_OChannel3 : 48|16@1+ (1,0) [0|64255] "" Vector__XXX
 SG_ AuxI_OChannel4 : 32|16@1+ (1,0) [0|64255] "" Vector__XXX
 SG_ AuxI_OChannel5 : 16|16@1+ (1,0) [0|64255] "" Vector__XXX
 SG_ AuxI_OChannel6 : 0|16@1+ (1,0) [0|64255] "" Vector__XXX

BO_ 2566758398 AT1AC1: 8 Vector__XXX
 SG_ Aftertreatment1AirEnableActuator : 62|2@1+ (1,0) [0|3] "" Vector__XXX
 SG_ Aftertreatment1PurgeAirActuator : 60|2@1+ (1,0) [0|3] "" Vector__XXX
 SG_ Aftrtrtmnt1AtmizationAirActuator : 58|2@1+ (1,0) [0|3] "" Vector__XXX
 SG_ Aftertreatment1AirSystemRelay : 56|2@1+ (1,0) [0|3] "" Vector__XXX
 SG_ Aftrtratment1AirPressActuatorPos : 48|8@1+ (0.4,0) [0|100] "%" Vector__XXX
 SG_ Aftertreatment1AirPressCtrl : 32|16@1+ (0.0025,0) [0|160.6375] "%" Vector__XXX
 SG_ Aftertreatment1PurgeAirPress : 16|16@1+ (0.1,0) [0|6425.5] "kPa" Vector__XXX
 SG_ Aftertreatment1SupplyAirPress : 0|16@1+ (0.1,0) [0|6425.5] "kPa" Vector__XXX

BO_ 2566745598 AT1AC2: 8 Vector__XXX
 SG_ Aftertreatment1SecondAirPress : 48|16@1+ (0.1,0) [0|6425.5] "kPa" Vector__XXX
 SG_ Aftertreatment1SecondAirMassFlow : 32|16@1+ (0.2,0) [0|12851] "kg/h per bit" Vector__XXX
 SG_ Aftertreatment1SecondAirTemp : 16|16@1+ (0.03125,-273) [-273|1734.96875] "deg C" Vector__XXX
 SG_ Aftrtreatment1SecondAirDiffPress : 0|16@1+ (0.0078125,-250) [-250|251.99] "kPa" Vector__XXX

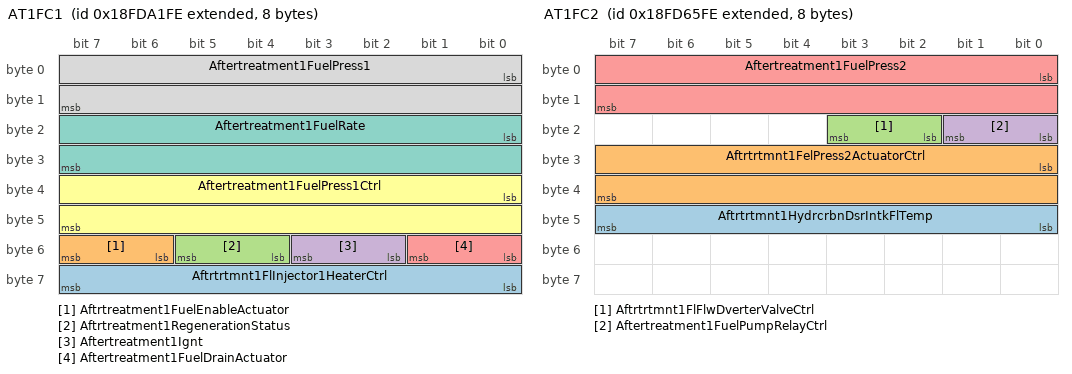
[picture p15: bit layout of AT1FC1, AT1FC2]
BO_ 2566758910 AT1FC1: 8 Vector__XXX
 SG_ Aftrtrtmnt1FlInjector1HeaterCtrl : 56|8@1+ (0.4,0) [0|100] "%" Vector__XXX
 SG_ Aftrtreatment1FuelEnableActuator : 54|2@1+ (1,0) [0|3] "" Vector__XXX
 SG_ Aftrtreatment1RegenerationStatus : 52|2@1+ (1,0) [0|3] "" Vector__XXX
 SG_ Aftertreatment1Ignt : 50|2@1+ (1,0) [0|3] "" Vector__XXX
 SG_ Aftertreatment1FuelDrainActuator : 48|2@1+ (1,0) [0|3] "" Vector__XXX
 SG_ Aftertreatment1FuelPress1Ctrl : 32|16@1+ (0.0025,0) [0|160.6375] "%" Vector__XXX
 SG_ Aftertreatment1FuelRate : 16|16@1+ (0.05,0) [0|3212.75] "L/h" Vector__XXX
 SG_ Aftertreatment1FuelPress1 : 0|16@1+ (0.1,0) [0|6425.5] "kPa" Vector__XXX

BO_ 2566743550 AT1FC2: 8 Vector__XXX
 SG_ Aftrtrtmnt1HydrcrbnDsrIntkFlTemp : 40|8@1+ (1,-40) [-40|210] "deg C" Vector__XXX
 SG_ Aftrtrtmnt1FelPress2ActuatorCtrl : 24|16@1+ (0.0025,0) [0|160.6375] "%" Vector__XXX
 SG_ Aftrtrtmnt1FlFlwDverterValveCtrl : 18|2@1+ (1,0) [0|3] "" Vector__XXX
 SG_ Aftertreatment1FuelPumpRelayCtrl : 16|2@1+ (1,0) [0|3] "" Vector__XXX
 SG_ Aftertreatment1FuelPress2 : 0|16@1+ (0.1,0) [0|6425.5] "kPa" Vector__XXX

BO_ 2566753534 AT1GP: 8 Vector__XXX
 SG_ DslParticulateFilterOutletPress1 : 16|16@1+ (0.1,0) [0|6425.5] "kPa" Vector__XXX
 SG_ DslParticulateFilterIntakePress1 : 0|16@1+ (0.1,0) [0|6425.5] "kPa" Vector__XXX

BO_ 2566756606 AT1HI: 8 Vector__XXX
 SG_ Aftrtrtmnt1AvrgDstncBtwnActvDPFR : 288|32@1+ (0.125,0) [0|526385151.9] "km" Vector__XXX
 SG_ Aftrtrtmnt1AvrgTmBtwnActvRgnrtns : 256|32@1+ (1,0) [0|4211081215] "s" Vector__XXX
 SG_ Aftrtrtmnt1DslPrtcltFltrTtlN3728 : 224|32@1+ (1,0) [0|4211081215] "" Vector__XXX
 SG_ Aftrtrtmnt1DslPrtcltFltrTtlN3727 : 192|32@1+ (1,0) [0|4211081215] "" Vector__XXX
 SG_ Aftrtrtmnt1DslPrtcltFltrTtlNmbrO : 160|32@1+ (1,0) [0|4211081215] "" Vector__XXX
 SG_ Aftrtrtmnt1DslPrtcltFltrTtlPssvR : 128|32@1+ (1,0) [0|4211081215] "s" Vector__XXX
 SG_ Aftrtrtmnt1TtlNmbrOfActvRgnrtons : 96|32@1+ (1,0) [0|4211081215] "" Vector__XXX
 SG_ Aftertreatment1TotalDisabledTime : 64|32@1+ (1,0) [0|4211081215] "s" Vector__XXX
 SG_ Aftrtrtmnt1TotalRegenerationTime : 32|32@1+ (1,0) [0|4211081215] "s" Vector__XXX
 SG_ Aftertreatment1TotalFuelUsed : 0|32@1+ (0.5,0) [0|2105540607.5] "L" Vector__XXX

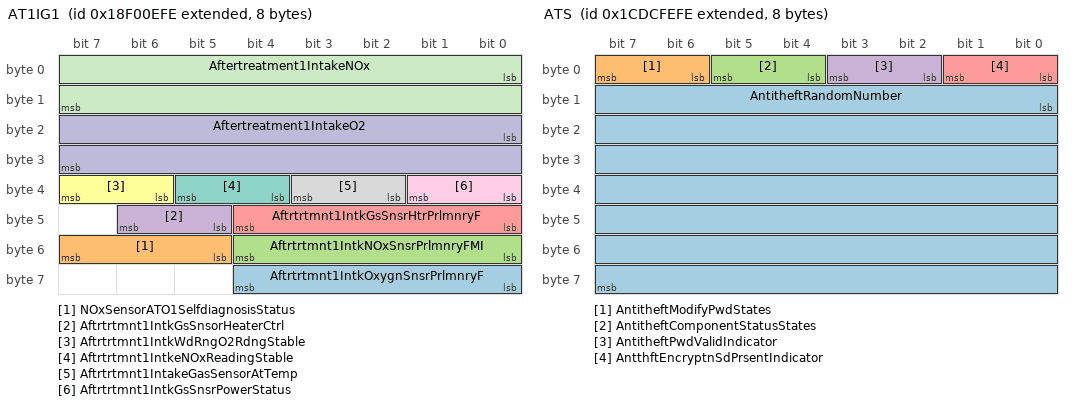
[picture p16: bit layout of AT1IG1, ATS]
BO_ 2565869310 AT1IG1: 8 Vector__XXX
 SG_ Aftrtrtmnt1IntkOxygnSnsrPrlmnryF : 56|5@1+ (1,0) [0|31] "" Vector__XXX
 SG_ NOxSensorATO1SelfdiagnosisStatus : 53|3@1+ (1,0) [0|7] "" Vector__XXX
 SG_ Aftrtrtmnt1IntkNOxSnsrPrlmnryFMI : 48|5@1+ (1,0) [0|31] "" Vector__XXX
 SG_ Aftrtrtmnt1IntkGsSnsorHeaterCtrl : 45|2@1+ (1,0) [0|3] "" Vector__XXX
 SG_ Aftrtrtmnt1IntkGsSnsrHtrPrlmnryF : 40|5@1+ (1,0) [0|31] "" Vector__XXX
 SG_ Aftrtrtmnt1IntkWdRngO2RdngStable : 38|2@1+ (1,0) [0|3] "" Vector__XXX
 SG_ Aftrtrtmnt1IntkeNOxReadingStable : 36|2@1+ (1,0) [0|3] "" Vector__XXX
 SG_ Aftrtrtmnt1IntakeGasSensorAtTemp : 34|2@1+ (1,0) [0|3] "" Vector__XXX
 SG_ Aftrtrtmnt1IntkGsSnsrPowerStatus : 32|2@1+ (1,0) [0|3] "" Vector__XXX
 SG_ Aftertreatment1IntakeO2 : 16|16@1+ (0.000514,-12) [-12|21] "%" Vector__XXX
 SG_ Aftertreatment1IntakeNOx : 0|16@1+ (0.05,-200) [-200|3012.75] "ppm" Vector__XXX

BO_ 2566763774 AT1IG2: 8 Vector__XXX
 SG_ Aftrtrtmnt1DslPrtcltFltrIntk3244 : 40|5@1+ (1,0) [0|31] "" Vector__XXX
 SG_ Aftrtrtmnt1ExhstGsTmp1PrlmnryFMI : 32|5@1+ (1,0) [0|31] "" Vector__XXX
 SG_ Aftrtrtmnt1DslPrtcltFltrIntkGsTm : 16|16@1+ (0.03125,-273) [-273|1734.96875] "deg C" Vector__XXX
 SG_ Aftertreatment1ExhaustGasTemp1 : 0|16@1+ (0.03125,-273) [-273|1734.96875] "deg C" Vector__XXX

BO_ 2631728894 ATS: 8 Vector__XXX
 SG_ AntitheftRandomNumber : 8|56@1+ (1,0) [0|255] "per byte" Vector__XXX
 SG_ AntitheftModifyPwdStates : 6|2@1+ (1,0) [0|3] "" Vector__XXX
 SG_ AntitheftComponentStatusStates : 4|2@1+ (1,0) [0|3] "" Vector__XXX
 SG_ AntitheftPwdValidIndicator : 2|2@1+ (1,0) [0|3] "" Vector__XXX
 SG_ AntthftEncryptnSdPrsentIndicator : 0|2@1+ (1,0) [0|3] "" Vector__XXX

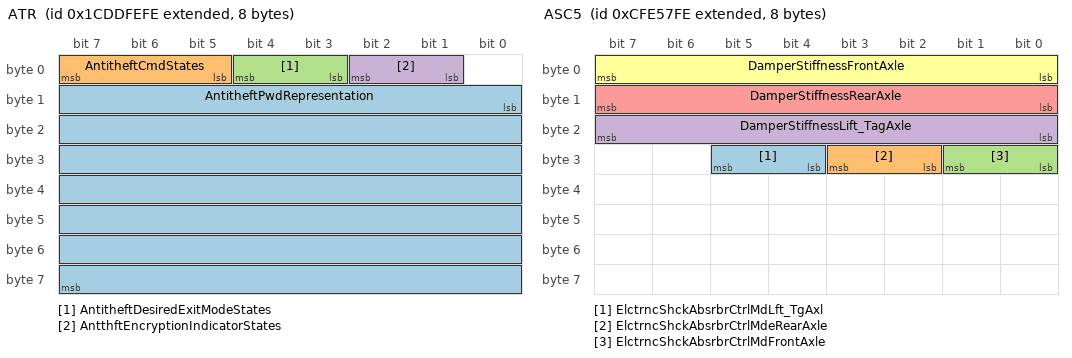
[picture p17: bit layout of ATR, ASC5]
BO_ 2631794430 ATR: 8 Vector__XXX
 SG_ AntitheftPwdRepresentation : 8|56@1+ (1,0) [0|255] "per byte" Vector__XXX
 SG_ AntitheftCmdStates : 5|3@1+ (1,0) [0|7] "" Vector__XXX
 SG_ AntitheftDesiredExitModeStates : 3|2@1+ (1,0) [0|3] "" Vector__XXX
 SG_ AntthftEncryptionIndicatorStates : 1|2@1+ (1,0) [0|3] "" Vector__XXX

BO_ 2633934846 AT: 8 Vector__XXX
 SG_ EngAltWinding3Temp : 32|8@1+ (1,-40) [-40|210] "deg C" Vector__XXX
 SG_ EngAltWinding2Temp : 24|8@1+ (1,-40) [-40|210] "deg C" Vector__XXX
 SG_ EngAltWinding1Temp : 16|8@1+ (1,-40) [-40|210] "deg C" Vector__XXX
 SG_ EngAltBearing2Temp : 8|8@1+ (1,-40) [-40|210] "deg C" Vector__XXX
 SG_ EngAltBearing1Temp : 0|8@1+ (1,-40) [-40|210] "deg C" Vector__XXX

BO_ 2362572542 ASC6: 8 Vector__XXX
 SG_ LevelPresetRearAxleRight : 48|16@1+ (0.1,-3200) [-3200|3225.5] "mm" Vector__XXX
 SG_ LevelPresetRearAxleLeft : 32|16@1+ (0.1,-3200) [-3200|3225.5] "mm" Vector__XXX
 SG_ LevelPresetFrontAxleRight : 16|16@1+ (0.1,-3200) [-3200|3225.5] "mm" Vector__XXX
 SG_ LevelPresetFrontAxleLeft : 0|16@1+ (0.1,-3200) [-3200|3225.5] "mm" Vector__XXX

BO_ 2365478910 ASC5: 8 Vector__XXX
 SG_ ElctrncShckAbsrbrCtrlMdLft_TgAxl : 28|2@1+ (1,0) [0|3] "" Vector__XXX
 SG_ ElctrncShckAbsrbrCtrlMdeRearAxle : 26|2@1+ (1,0) [0|3] "" Vector__XXX
 SG_ ElctrncShckAbsrbrCtrlMdFrontAxle : 24|2@1+ (1,0) [0|3] "" Vector__XXX
 SG_ DamperStiffnessLift_TagAxle : 16|8@1+ (0.4,0) [0|100] "%" Vector__XXX
 SG_ DamperStiffnessRearAxle : 8|8@1+ (0.4,0) [0|100] "%" Vector__XXX
 SG_ DamperStiffnessFrontAxle : 0|8@1+ (0.4,0) [0|100] "%" Vector__XXX

BO_ 2560950014 DM30: 12 Vector__XXX
 SG_ TestLimitMinimum : 80|16@1+ (1,0) [0|64255] "" Vector__XXX
 SG_ TestLimitMaximum : 64|16@1+ (1,0) [0|64255] "" Vector__XXX
 SG_ TestValue : 48|16@1+ (1,0) [0|64255] "" Vector__XXX
 SG_ SlotId : 32|16@1+ (1,0) [0|64255] "" Vector__XXX
 SG_ TestIdentifier : 0|8@1+ (1,0) [0|255] "" Vector__XXX
 SG_ FailureModeIdentifier1 : 24|5@1+ (1,0) [0|0] "" Vector__XXX
 SG_ SPN1High : 29|3@1+ (1,0) [0|7] "" Vector__XXX
 SG_ SPN1 : 8|16@1+ (1,0) [0|65536] "" Vector__XXX

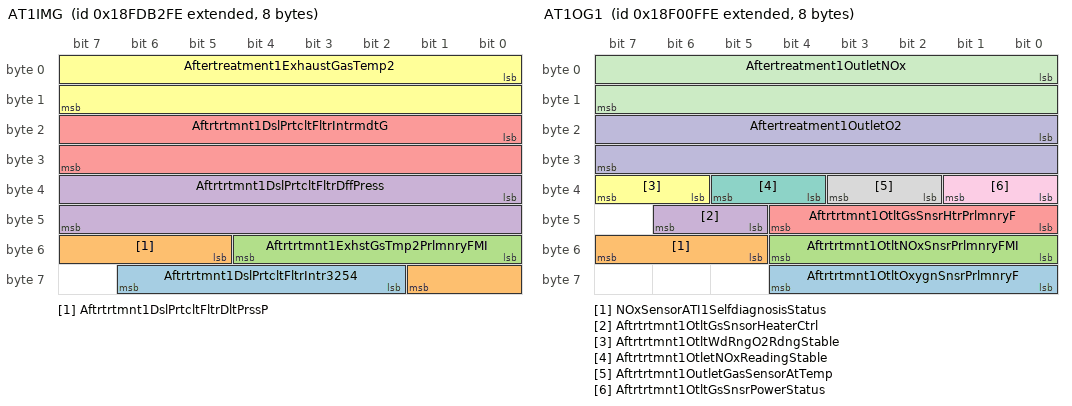
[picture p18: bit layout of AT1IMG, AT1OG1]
BO_ 2566763262 AT1IMG: 8 Vector__XXX
 SG_ Aftrtrtmnt1DslPrtcltFltrIntr3254 : 58|5@1+ (1,0) [0|31] "" Vector__XXX
 SG_ Aftrtrtmnt1DslPrtcltFltrDltPrssP : 53|5@1+ (1,0) [0|31] "" Vector__XXX
 SG_ Aftrtrtmnt1ExhstGsTmp2PrlmnryFMI : 48|5@1+ (1,0) [0|31] "" Vector__XXX
 SG_ Aftrtrtmnt1DslPrtcltFltrDffPress : 32|16@1+ (0.1,0) [0|6425.5] "kPa" Vector__XXX
 SG_ Aftrtrtmnt1DslPrtcltFltrIntrmdtG : 16|16@1+ (0.03125,-273) [-273|1734.96875] "deg C" Vector__XXX
 SG_ Aftertreatment1ExhaustGasTemp2 : 0|16@1+ (0.03125,-273) [-273|1734.96875] "deg C" Vector__XXX

BO_ 2565869566 AT1OG1: 8 Vector__XXX
 SG_ Aftrtrtmnt1OtltOxygnSnsrPrlmnryF : 56|5@1+ (1,0) [0|31] "" Vector__XXX
 SG_ NOxSensorATI1SelfdiagnosisStatus : 53|3@1+ (1,0) [0|7] "" Vector__XXX
 SG_ Aftrtrtmnt1OtltNOxSnsrPrlmnryFMI : 48|5@1+ (1,0) [0|31] "" Vector__XXX
 SG_ Aftrtrtmnt1OtltGsSnsorHeaterCtrl : 45|2@1+ (1,0) [0|3] "" Vector__XXX
 SG_ Aftrtrtmnt1OtltGsSnsrHtrPrlmnryF : 40|5@1+ (1,0) [0|31] "" Vector__XXX
 SG_ Aftrtrtmnt1OtltWdRngO2RdngStable : 38|2@1+ (1,0) [0|3] "" Vector__XXX
 SG_ Aftrtrtmnt1OtletNOxReadingStable : 36|2@1+ (1,0) [0|3] "" Vector__XXX
 SG_ Aftrtrtmnt1OutletGasSensorAtTemp : 34|2@1+ (1,0) [0|3] "" Vector__XXX
 SG_ Aftrtrtmnt1OtltGsSnsrPowerStatus : 32|2@1+ (1,0) [0|3] "" Vector__XXX
 SG_ Aftertreatment1OutletO2 : 16|16@1+ (0.000514,-12) [-12|21] "%" Vector__XXX
 SG_ Aftertreatment1OutletNOx : 0|16@1+ (0.05,-200) [-200|3012.75] "ppm" Vector__XXX

BO_ 2566763518 AT1OG2: 8 Vector__XXX
 SG_ Aftrtrtmnt1DslPrtcltFltrOtltExhs : 40|5@1+ (1,0) [0|31] "" Vector__XXX
 SG_ Aftrtrtmnt1ExhstGsTmp3PrlmnryFMI : 32|5@1+ (1,0) [0|31] "" Vector__XXX
 SG_ Aftrtrtmnt1DslPrtcltFltrOtltGsTm : 16|16@1+ (0.03125,-273) [-273|1734.96875] "deg C" Vector__XXX
 SG_ Aftertreatment1ExhaustGasTemp3 : 0|16@1+ (0.03125,-273) [-273|1734.96875] "deg C" Vector__XXX

BO_ 2566749182 AT1S: 8 Vector__XXX
 SG_ Aftrtrtmnt1DslPrtcltFltrStLdRgnr : 48|16@1+ (0.0025,0) [0|160.6375] "%" Vector__XXX
 SG_ DslPrtcltFltr1TmSncLstActvRgnrtn : 16|32@1+ (1,0) [0|4211081215] "s" Vector__XXX
 SG_ DslPrtclateFilter1AshLoadPercent : 8|8@1+ (1,0) [0|250] "%" Vector__XXX
 SG_ DslPrtclteFilter1SootLoadPercent : 0|8@1+ (1,0) [0|250] "%" Vector__XXX

BO_ 2566748670 AT1TI: 32 Vector__XXX
 SG_ Aftrtrtmnt1DslPrtcltFltrTrpN3740 : 224|32@1+ (1,0) [0|4211081215] "" Vector__XXX
 SG_ Aftrtrtmnt1DslPrtcltFltrTrpN3739 : 192|32@1+ (1,0) [0|4211081215] "" Vector__XXX
 SG_ Aftrtrtmnt1DslPrtcltFltrTrpN3738 : 160|32@1+ (1,0) [0|4211081215] "" Vector__XXX
 SG_ Aftrtrtmnt1DslPrtcltFltrTrpPssvR : 128|32@1+ (1,0) [0|4211081215] "s" Vector__XXX
 SG_ Aftrtrtmnt1DslPrtcltFltrTrpNmbrO : 96|32@1+ (1,0) [0|4211081215] "" Vector__XXX
 SG_ Aftrtrtmnt1DslPrtcltFltrTrpDsbld : 64|32@1+ (1,0) [0|4211081215] "s" Vector__XXX
 SG_ Aftrtrtmnt1DslPrtcltFltrTrpActvR : 32|32@1+ (1,0) [0|4211081215] "s" Vector__XXX
 SG_ Aftrtrtmnt1DslPrtcltFltrTrpFlUsd : 0|32@1+ (0.5,0) [0|2105540607.5] "L" Vector__XXX

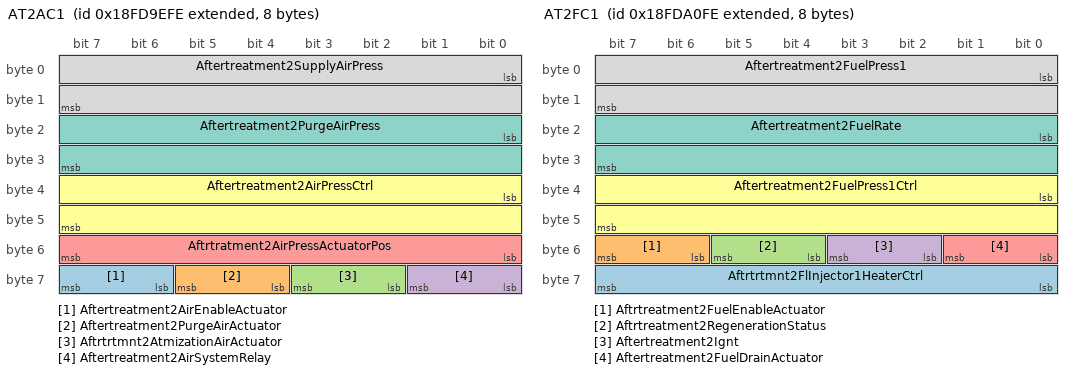
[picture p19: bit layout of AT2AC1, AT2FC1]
BO_ 2566758142 AT2AC1: 8 Vector__XXX
 SG_ Aftertreatment2AirEnableActuator : 62|2@1+ (1,0) [0|3] "" Vector__XXX
 SG_ Aftertreatment2PurgeAirActuator : 60|2@1+ (1,0) [0|3] "" Vector__XXX
 SG_ Aftrtrtmnt2AtmizationAirActuator : 58|2@1+ (1,0) [0|3] "" Vector__XXX
 SG_ Aftertreatment2AirSystemRelay : 56|2@1+ (1,0) [0|3] "" Vector__XXX
 SG_ Aftrtratment2AirPressActuatorPos : 48|8@1+ (0.4,0) [0|100] "%" Vector__XXX
 SG_ Aftertreatment2AirPressCtrl : 32|16@1+ (0.0025,0) [0|160.6375] "%" Vector__XXX
 SG_ Aftertreatment2PurgeAirPress : 16|16@1+ (0.1,0) [0|6425.5] "kPa" Vector__XXX
 SG_ Aftertreatment2SupplyAirPress : 0|16@1+ (0.1,0) [0|6425.5] "kPa" Vector__XXX

BO_ 2566745342 AT2AC2: 8 Vector__XXX
 SG_ Aftertreatment2SecondAirPress : 48|16@1+ (0.1,0) [0|6425.5] "kPa" Vector__XXX
 SG_ Aftertreatment2SecondAirMassFlow : 32|16@1+ (0.2,0) [0|12851] "kg/h per bit" Vector__XXX
 SG_ Aftertreatment2SecondAirTemp : 16|16@1+ (0.03125,-273) [-273|1734.96875] "deg C" Vector__XXX
 SG_ Aftrtreatment2SecondAirDiffPress : 0|16@1+ (0.0078125,-250) [-250|251.99] "kPa" Vector__XXX

BO_ 2566758654 AT2FC1: 8 Vector__XXX
 SG_ Aftrtrtmnt2FlInjector1HeaterCtrl : 56|8@1+ (0.4,0) [0|100] "%" Vector__XXX
 SG_ Aftrtreatment2FuelEnableActuator : 54|2@1+ (1,0) [0|3] "" Vector__XXX
 SG_ Aftrtreatment2RegenerationStatus : 52|2@1+ (1,0) [0|3] "" Vector__XXX
 SG_ Aftertreatment2Ignt : 50|2@1+ (1,0) [0|3] "" Vector__XXX
 SG_ Aftertreatment2FuelDrainActuator : 48|2@1+ (1,0) [0|3] "" Vector__XXX
 SG_ Aftertreatment2FuelPress1Ctrl : 32|16@1+ (0.0025,0) [0|160.6375] "%" Vector__XXX
 SG_ Aftertreatment2FuelRate : 16|16@1+ (0.05,0) [0|3212.75] "L/h" Vector__XXX
 SG_ Aftertreatment2FuelPress1 : 0|16@1+ (0.1,0) [0|6425.5] "kPa" Vector__XXX

BO_ 2566753278 AT2GP: 8 Vector__XXX
 SG_ DslParticulateFilterOutletPress2 : 16|16@1+ (0.1,0) [0|6425.5] "kPa" Vector__XXX
 SG_ DslParticulateFilterIntakePress2 : 0|16@1+ (0.1,0) [0|6425.5] "kPa" Vector__XXX

BO_ 2566756862 AT2HI: 8 Vector__XXX
 SG_ Aftrtrtmnt2AvrgDstncBtwnActvDPFR : 288|32@1+ (0.125,0) [0|526385151.9] "km" Vector__XXX
 SG_ Aftrtrtmnt2AvrgTmBtwnActvRgnrtns : 256|32@1+ (1,0) [0|4211081215] "s" Vector__XXX
 SG_ Aftrtrtmnt2DslPrtcltFltrTtlN3732 : 224|32@1+ (1,0) [0|4211081215] "" Vector__XXX
 SG_ Aftrtrtmnt2DslPrtcltFltrTtlN3731 : 192|32@1+ (1,0) [0|4211081215] "" Vector__XXX
 SG_ Aftrtrtmnt2DslPrtcltFltrTtlNmbrO : 160|32@1+ (1,0) [0|4211081215] "" Vector__XXX
 SG_ Aftrtrtmnt2DslPrtcltFltrTtlPssvR : 128|32@1+ (1,0) [0|4211081215] "s" Vector__XXX
 SG_ Aftrtrtmnt2TtlNmbrOfActvRgnrtons : 96|32@1+ (1,0) [0|4211081215] "" Vector__XXX
 SG_ Aftertreatment2TotalDisabledTime : 64|32@1+ (1,0) [0|4211081215] "s" Vector__XXX
 SG_ Aftrtrtmnt2TotalRegenerationTime : 32|32@1+ (1,0) [0|4211081215] "s" Vector__XXX
 SG_ Aftertreatment2TotalFuelUsed : 0|32@1+ (0.5,0) [0|2105540607.5] "L" Vector__XXX

CM_ BO_ 2566711806 "Operator commands sent via the Armrest Switch Matrices.";
CM_ SG_ 2566711806 Armrest2Switch2 "Status of the second switch located in armrest 2.";
CM_ SG_ 2566711806 Armrest2Switch1 "Status of the first switch located in armrest 2.";
CM_ SG_ 2566711806 Armrest1Switch2 "Status of the second switch located in armrest 1.";
CM_ SG_ 2566711806 Armrest1Switch1 "Status of the first switch located in armrest 1.";
CM_ BO_ 2364549886 "The Angular Rate Information message shall provide a measurement of the vehicle's pitch rate, roll rate, and yaw rate ...";
CM_ SG_ 2364549886 AngularRateMeasurementLatency "The estimated measurement latency of the measurement.";
CM_ SG_ 2364549886 YawRateExRangeFigureOfMerit "Figure of merit for yaw angle measurement.";
CM_ SG_ 2364549886 RollRateExRangeFigureOfMerit "Figure of merit for roll rate measurement.";
CM_ SG_ 2364549886 PitchRateExRangeFigureOfMerit "Figure of merit for pitch rate measurement.";
CM_ SG_ 2364549886 YawRateExRange "Yaw rate is the rate-of-change of the yaw angle over time.  A positive yaw rate signal results when the object turns ...";
CM_ SG_ 2364549886 RollRateExRange "Roll rate is the rate-of-change of the roll angle over time.  The roll rate for increasing roll to the right is reported with a ...";
CM_ SG_ 2364549886 PitchRateExRange "Pitch rate is the rate-of-change of the pitch angle over time, where the pitch angle vector is in the direction of travel of the ...";
CM_ BO_ 2566712318 "This message contains NOx adsorber information for aftertreatment system 2 (or bank 2).";
CM_ SG_ 2566712318 Aftrtrtmnt2NOxAdsrbrDSOxRgnrtnSt "Indicates whether the NOx adsorber deSOx regeneration in the second aftertreatment system is active or inactive ...";
CM_ SG_ 2566712318 Aftrtrtmnt2NOxAdsrbrDNOxRgnrtnSt "Indicates whether the NOx adsorber deNOx regeneration in the second aftertreatment system is active or inactive ...";
CM_ BO_ 2566712574 "This message contains NOx adsorber information for aftertreatment system 1 (or bank 1).";
CM_ SG_ 2566712574 Aftrtrtmnt1NOxAdsrbrDSOxRgnrtnSt "Indicates whether the NOx adsorber deSOx regeneration in the first aftertreatment system is active or inactive ...";
CM_ SG_ 2566712574 Aftrtrtmnt1NOxAdsrbrDNOxRgnrtnSt "Indicates whether the NOx adsorber deNOx regeneration in the first aftertreatment system is active or inactive ...";
CM_ BO_ 2164078590 "This message contains SCR service information for aftertreatment system 2 (or bank 2).";
CM_ SG_ 2164078590 Aftrtrtmnt2SCRCnvrsionEfficiency "The SCR conversion efficiency percentage.  Calculated as 100 times the catalyst intake NOx minus the catalyst outlet ...";
CM_ SG_ 2164078590 Aftrtrtmnt2SCRCmmnddCtlystDslExh "This parameter transmits the amount of diesel exhaust fluid that the emissions control system has requested to be used, ...";
CM_ SG_ 2164078590 Aftrtrtmnt2DslExhstFldAvrgCnsmpt "Measured use of diesel exhaust fluid by a Selective Catalytic Reduction system for exhaust emission control, averaged ...";
CM_ BO_ 2566731006 "This message contains SCR reagent tank 2 information for aftertreatment system 2 (or bank 2).  The second tank for the ...";
CM_ SG_ 2566731006 Aftrtrtmnt2DslExhstFldTnk2HtrPrl "Used to identify the applicable J1939-73 FMI detected in the diesel exhaust fluid tank 2 heater by the manufacturer’s ...";
CM_ SG_ 2566731006 Aftrtrtmnt2DslExhstFldTnk2Heater "The diesel exhaust fluid tank 2 heater percentage for aftertreatment system 1 (exhaust bank 1). 0% is off.  See SPN 5415 ...";
CM_ SG_ 2566731006 Aftrtrtmnt2DslExhstFldTnk2TmpPrl "Used to identify the applicable J1939-73 FMI detected in the diesel exhaust fluid tank 2 temperature, by the ...";
CM_ SG_ 2566731006 Aftrtrtmnt2DslExhstFldTnk2LvlPrl "Used to identify the applicable J1939-73 FMI detected in the diesel exhaust fluid tank 2 level, by the manufacturer’s ...";
CM_ SG_ 2566731006 Aftrtrtmnt2DslExhstFldTnk2Level2 "The diesel exhaust fluid tank 2 level height in mm for aftertreatment system 2 (exhaust bank 2).  Tank 2 is used as a quick ...";
CM_ SG_ 2566731006 Aftrtrtmnt2DslExhstFlidTank2Temp "The diesel exhaust fluid tank 2 temperature for aftertreatment system 2 (exhaust bank 2).  Tank 2 is used as a quick thaw ...";
CM_ SG_ 2566731006 Aftrtrtmnt2DslExhstFldTank2Level "The diesel exhaust fluid tank 2 level percentage for aftertreatment system 2 (exhaust bank 2).  0% is empty and 100% is ...";
CM_ BO_ 2566731262 "This message contains SCR reagent tank 1 information for aftertreatment system 2 (or bank 2).  The first tank for the ...";
CM_ SG_ 2566731262 Aftrtrtmnt2DslExhstFldTnk1HtrPrl "Used to identify the applicable J1939-73 FMI detected in the diesel exhaust fluid tank 1 heater, by the manufacturer’s ...";
CM_ SG_ 2566731262 Aftrtrtmnt2DslExhstFldTankHeater "Percentage of heating applied to the aftertreatment 2 diesel exhaust fluid tank heater.  A value of 0% means no heating ...";
CM_ SG_ 2566731262 Aftrtrtmnt2DslExhstFldTnk1TmpPrl "Used to identify the applicable J1939-73 FMI detected in the diesel exhaust fluid tank 1 temperature by the ...";
CM_ SG_ 2566731262 Aftrtrtmnt2DslExhstFldTnkLvlPrlm "Used to identify the applicable J1939-73 FMI detected in the diesel exhaust fluid tank level sensor by the manufacturer's ...";
CM_ SG_ 2566731262 Aftrtrtmnt2DslExhstFldTankLevel2 "The measure of the diesel exhaust fluid level in the diesel exhaust fluid tank.";
CM_ SG_ 2566731262 Aftrtrtmnt2DslExhstFluidTankTemp "Temperature of the diesel exhaust fluid in the storage tank.";
CM_ SG_ 2566731262 Aftrtrtmnt2DslExhstFlidTankLevel "Ratio of volume of diesel exhaust fluid to the total volume of diesel exhaust fluid storage container.";
CM_ BO_ 2566730750 "This message contains diesel exhaust fluid supply information for aftertreatment system 2 (or bank 2).";
CM_ SG_ 2566730750 Aftrtrtmnt2DslExhstFldTnkDrnVlvC "Commanded percentage of maximum Aftertreatment 2 Diesel Exhaust Fluid Tank Drain Valve opening. 100% means the ...";
CM_ SG_ 2566730750 Aftrtrtmnt2DslExhstFlidPumpState "State of Aftertreatment 2 Diesel Exhaust Fluid dosing pump.";
CM_ SG_ 2566730750 Aftrtrtmnt2DslExhstFldTnkFllVlvC "Commanded percentage of maximum Aftertreatment 2 Diesel Exhaust Fluid Tank Fill Valve opening. 100% means the fill ...";
CM_ SG_ 2566730750 Aftrtrtmnt2DslExhstFldRturnValve "Command to the valve which determines whether the diesel exhaust fluid is delivered to the injector or is routed back to ...";
CM_ SG_ 2566730750 Aftrtrtmnt2DslExhstFldPmpDrvPrcn "The percent (command) sent to the motor to control the speed of  the diesel exhaust fluid pump.";
CM_ SG_ 2566730750 Aftrtrtmnt2DslExhstFldPmpMtrSped "Rotational speed of the motor driving a pump for diesel exhaust fluid used in an aftertreatment system.";
CM_ BO_ 2566731518 "Sensor Information which measures temperature, concentration, and conductivity of the diesel exhaust fluid of the ...";
CM_ SG_ 2566731518 Aftrtrtmnt2DeselExhaustFluidType "This parameter indicates the property of the fluid compound in the tank.  A value of 0011 indicates uncontaminated Diesel ...";
CM_ SG_ 2566731518 Aftrtrtmnt2DslExhstFldPrprtsPrlm "Used to identify the applicable J1939-73 FMI that applies to the most significant failure of the diesel exhaust fluid ...";
CM_ SG_ 2566731518 Aftrtrtmnt2DslExhstFldTmp2Prlmnr "Used to identify the applicable J1939-73 FMI that applies to the most significant failure of the diesel exhaust fluid ...";
CM_ SG_ 2566731518 Aftrtrtmnt2DslExhstFldCndctivity "A measure of the conductivity of the diesel exhaust fluid at the sensor.  The conductivity is an indication of the diesel ...";
CM_ SG_ 2566731518 Aftrtrtmnt2DslExhstFldCncntrtion "A measure of the concentration of urea in water.  Zero percent means that the tank contains no urea.  A 32.5% value ...";
CM_ SG_ 2566731518 Aftrtrtmnt2DselExhaustFluidTemp2 "Temperature of the diesel exhaust fluid at the device measuring diesel exhaust fluid quality ...";
CM_ BO_ 2566732030 "This message contains SCR catalyst intake and outlet exhaust gas temperature information for aftertreatment system 2 ...";
CM_ SG_ 2566732030 Aftrtrtmnt2SCRCtlystOtltGsTmpPrl "Used to identify the applicable J1939-73 FMI detected in the SCR catalyst outlet gas temperature sensor by the ...";
CM_ SG_ 2566732030 Aftrtrtmnt2SCRCtlystOtletGasTemp "Temperature of engine combustion byproducts leaving the SCR catalyst exhaust in exhaust bank 2.";
CM_ SG_ 2566732030 Aftrtrtmnt2SCRCtlystIntkGsTmpPrl "Used to identify the applicable J1939-73 FMI detected in the SCR catalyst intake gas temperature sensor by the ...";
CM_ SG_ 2566732030 Aftrtrtmnt2SCRCtlystIntkeGasTemp "Temperature of engine combustion byproducts entering the SCR catalyst in exhaust bank 2.";
CM_ BO_ 2566732286 "This message contains SCR catalyst exhaust gas pressure information for aftertreatment system 2 (or bank 2).";
CM_ SG_ 2566732286 Aftrtrtmnt2SCRExhstGsDffPrssPrlm "Used to identify the applicable J1939-73 FMI detected in the SCR differential pressure sensor by the manufacturer’s ...";
CM_ SG_ 2566732286 Aftrtrtmnt2SCRExhustGasDiffPress "Exhaust differential pressure measured between the intake and exhaust of an SCR component in exhaust bank 2.";
CM_ BO_ 2164079358 "This message contains SCR dosing system request information for aftertreatment system 2 (or bank 2).";
CM_ SG_ 2164079358 Aftrtrtmnt2DslExhstFldTnk2HtrCmd "This is the command for the Aftertreatment 2 Diesel Exhaust Fluid Tank 2 Heater.  See SPN 4438 for the measured value ...";
CM_ SG_ 2164079358 Aftrtrtmnt2DslExhstFldTnkHterCmd "Command for the Aftertreatment 2 Diesel Exhaust Fluid Tank Heater.  A value of 0% means no heating applied, a value ...";
CM_ SG_ 2164079358 Aftrtrtmnt2DslExhstFldLneHeater4 "The diesel exhaust fluid line heater 4 request for aftertreatment system 2 (exhaust bank 2).";
CM_ SG_ 2164079358 Aftrtrtmnt2DslExhstFldLneHeater3 "The diesel exhaust fluid line heater 3 request for aftertreatment system 2 (exhaust bank 2).";
CM_ SG_ 2164079358 Aftrtrtmnt2DslExhstFldLneHeater2 "The diesel exhaust fluid line heater 2 request for aftertreatment system 2 (exhaust bank 2).";
CM_ SG_ 2164079358 Aftrtrtmnt2DslExhstFldLneHeater1 "The diesel exhaust fluid line heater 1 request for aftertreatment system 2 (exhaust bank 2).";
CM_ SG_ 2164079358 Aftrtrtmnt2DslExhstFldDsrHtngMdR "Used if multiple heater modes are available in the Doser.";
CM_ SG_ 2164079358 Aftrtrtmnt2DslExhstFldDsrFltSppr "Used if external devices can warn of conditions that require suppression of potential faults in the doser due to ...";
CM_ BO_ 2364549118 "This message contains SCR dosing system request information for aftertreatment system 2 (or bank 2).";
CM_ SG_ 2364549118 Aftrtrtmnt2DslExhstFldRqstdQntty "Represents the command for the diesel exhaust fluid quantity integrator in the dosing control unit ...";
CM_ SG_ 2364549118 Aftrtrtmnt2SCRSystmRquestedState "Requested state of SCR system for aftertreatment system 2 (exhaust bank 2).";
CM_ SG_ 2364549118 Aftrtrtmnt2DslExhstFldDsngRqstdQ "Actual requested dosing quantity of diesel exhaust fluid.";
CM_ BO_ 2566732798 "This message contains SCR dosing system information for aftertreatment system 2 (or bank 2).  See PGN 61478 for ...";
CM_ SG_ 2566732798 Aftrtrtmnt2DslExhstFldLnHtr4Prlm "Used to identify the applicable J1939-73 FMI detected in the diesel exhaust fluid line heater 4, by the manufacturer’s ...";
CM_ SG_ 2566732798 Aftrtrtmnt2DslExhstFldLnHtr4Stte "The diesel exhaust fluid line heater 4 state for aftertreatment system 2 (exhaust bank 2).";
CM_ SG_ 2566732798 Aftrtrtmnt2DslExhstFldLnHtr3Prlm "Used to identify the applicable J1939-73 FMI detected in the diesel exhaust fluid line heater 3, by the manufacturer’s ...";
CM_ SG_ 2566732798 Aftrtrtmnt2DslExhstFldLnHtr3Stte "The diesel exhaust fluid line heater 3 state for aftertreatment system 2 (exhaust bank 2).";
CM_ SG_ 2566732798 Aftrtrtmnt2DslExhstFldLnHtr2Prlm "Used to identify the applicable J1939-73 FMI detected in the diesel exhaust fluid line heater 2, by the manufacturer’s ...";
CM_ SG_ 2566732798 Aftrtrtmnt2DslExhstFldLnHtr2Stte "The diesel exhaust fluid line heater 2 state for aftertreatment system 2 (exhaust bank 2).";
CM_ SG_ 2566732798 Aftrtrtmnt2DslExhstFldLnHtr1Prlm "Used to identify the applicable J1939-73 FMI detected in the diesel exhaust fluid line heater 1, by the manufacturer’s ...";
CM_ SG_ 2566732798 Aftrtrtmnt2DslExhstFldLnHtr1Stte "The diesel exhaust fluid line heater 1 state for aftertreatment system 2 (exhaust bank 2).";
CM_ SG_ 2566732798 Aftrtrtmnt2SCRFeedbackCtrlStatus "The SCR feedback control status (open/closed loop) for aftertreatment system 2 (exhaust bank 2).";
CM_ SG_ 2566732798 Aftrtrtmnt2SCRDsngVlvExhstTmpRdc "Protection request for the dosing valve of the SCR-system to prevent overheating ...";
CM_ SG_ 2566732798 Aftrtrtmnt2DslExhstFldDosingTemp "The diesel exhaust fluid dosing temperature (measured closest to dosing valve) for aftertreatment system 2 (exhaust ...";
CM_ SG_ 2566732798 Aftrtrtmnt2SCRDsngAirAssistValve "The position of the valve used to regulate the air supply of an air assist SCR dosing system for an engine. 0% represents ...";
CM_ SG_ 2566732798 Aftrtrtmnt2SCRDsngArAssstAbsPrss "The SCR dosing system air assist absolute pressure for aftertreatment system 2 (exhaust bank 2).  The air assist system ...";
CM_ BO_ 2364548862 "This message contains SCR dosing system information for aftertreatment system 2 (or bank 2).  See PGN 64827 for ...";
CM_ SG_ 2364548862 Aftrtrtmnt2DslExhstFldDsngAbsPrs "The SCR dosing diesel exhaust fluid absolute pressure (measured closest to dosing valve) for aftertreatment system 2 ...";
CM_ SG_ 2364548862 Aftrtrtmnt2DslExhstFldActlQnttyO "The SCR requested diesel exhaust fluid integrator total quantity for aftertreatment system 2 (exhaust bank 2).";
CM_ SG_ 2364548862 Aftertreatment2SCRSystemState "Actual state of SCR system ...";
CM_ SG_ 2364548862 Aftrtrtmnt2DslExhstFldActlDsngQn "Actual reducing agent quantity of SCR system.";
CM_ BO_ 2364549374 "This message contains outlet ammonia information for aftertreatment system 2 (or bank 2).";
CM_ SG_ 2364549374 Aftrtrtmnt2OtltNH3GsSnsrHterCtrl "Indicates the heater status in the warm-up process. Upon receiving a power-up command, the NH3 gas sensor ramps up ...";
CM_ SG_ 2364549374 Aftrtrtmnt2OtltNH3GsSnsrHtrPrlmn "Used to identify the applicable J1939-73 FMI detected in the heater of the outlet NH3 exhaust gas sensor by the ...";
CM_ SG_ 2364549374 Aftrtrtmnt2OtltNH3GsSensorAtTemp "Indicates that the heater element of the aftertreatment outlet NH3 gas sensor is within the manufacturer’s specified range ...";
CM_ SG_ 2364549374 Aftrtrtmnt2OtltNH3GsSnsrPwrInRng "Indicates that the power supplied to the aftertreatment outlet NH3 gas sensor is within the manufacturer’s specification in ...";
CM_ SG_ 2364549374 Aftrtrtmnt2OtletNH3ReadingStable "Indicates that the NH3 reading of the aftertreatment outlet NH3 sensor is stable as determined by the manufacturer’s ...";
CM_ SG_ 2364549374 Aftrtrtmnt2OtltNH3SnsrPrlmnryFMI "Used to identify the applicable J1939-73 FMI detected in the aftertreatment outlet NH3 sensor by the manufacturer’s ...";
CM_ SG_ 2364549374 Aftertreatment2OutletNH3 "The amount of NH3 in the exhaust exiting the aftertreatment system measured by a NH3 sensor at the aftertreatment ...";
CM_ BO_ 2566726142 "The purpose of this PGN is to group the aftertreatment gas oxidation catalyst data for bank 2. These values include the ...";
CM_ SG_ 2566726142 Aftrtrtmnt2GsOxdtnCtlystDffPrssP "Used to identify the applicable J1939-73 FMI detected in the gas oxidation catalyst differential pressure sensor by the ...";
CM_ SG_ 2566726142 Aftrtrtmnt2GsOxdtnCtlystOtlt4763 "Used to identify the applicable J1939-73 FMI detected in the gas oxidation catalyst outlet gas temperature sensor by the ...";
CM_ SG_ 2566726142 Aftrtrtmnt2GsOxdtnCtlystIntk4762 "Used to identify the applicable J1939-73 FMI detected in the gas oxidation catalyst intake gas temperature sensor by the ...";
CM_ SG_ 2566726142 Aftrtrtmnt2GsOxdtnCtlystDffPress "Exhaust differential pressure measured between the intake and exhaust of the gas oxidation catalyst in exhaust bank 2.";
CM_ SG_ 2566726142 Aftrtrtmnt2GsOxdtnCtlystOtltGsTm "Temperature of engine combustion byproducts leaving the gas oxidation catalyst in exhaust bank 2.  This gas parameter ...";
CM_ SG_ 2566726142 Aftrtrtmnt2GsOxdtnCtlystIntkGsTm "Temperature of engine combustion byproducts entering the gas oxidation catalyst in exhaust bank 2.  This gas parameter ...";
CM_ BO_ 2566725630 "The purpose of this PGN is to group the aftertreatment diesel oxidation catalyst data for bank 2. These values include the ...";
CM_ SG_ 2566725630 Aftrtrtmnt2DslOxdtnCtlystDff4776 "Used to identify the applicable J1939-73 FMI detected in the diesel oxidation catalyst differential pressure sensor by the ...";
CM_ SG_ 2566725630 Aftrtrtmnt2DslOxdtnCtlystOtl4775 "Used to identify the applicable J1939-73 FMI detected in the diesel oxidation catalyst outlet gas temperature sensor by ...";
CM_ SG_ 2566725630 Aftrtrtmnt2DslOxdtnCtlystInt4774 "Used to identify the applicable J1939-73 FMI detected in the diesel oxidation catalyst intake gas temperature sensor by ...";
CM_ SG_ 2566725630 Aftrtrtmnt2DslOxdtnCtlystDffPrss "Exhaust differential pressure measured between the intake and exhaust of a diesel oxidation catalyst in exhaust bank 2.";
CM_ SG_ 2566725630 Aftrtrtmnt2DslOxdtnCtlystOtltGsT "Temperature of engine combustion byproducts leaving the diesel oxidation catalyst exhaust in exhaust bank 2.  This ...";
CM_ SG_ 2566725630 Aftrtrtmnt2DslOxdtnCtlystIntkGsT "Temperature of engine combustion byproducts entering the diesel oxidation catalyst in exhaust bank 2.  This diesel ...";
CM_ BO_ 2566733310 "This message contains SCR reagent tank 2 information for aftertreatment system 1 (or bank 1).  The second tank for the ...";
CM_ SG_ 2566733310 Aftrtrtmnt1DslExhstFldTnk2HtrPrl "Used to identify the applicable J1939-73 FMI detected in the diesel exhaust fluid tank 2 heater, by the manufacturer’s ...";
CM_ SG_ 2566733310 Aftrtrtmnt1DslExhstFldTnk2Heater "The diesel exhaust fluid tank 2 heater percentage for aftertreatment system 1 (exhaust bank 1).  0% is off.  See SPN ...";
CM_ SG_ 2566733310 Aftrtrtmnt1DslExhstFldTnk2TmpPrl "Used to identify the applicable J1939-73 FMI detected in the diesel exhaust fluid tank 2 temperature, by the ...";
CM_ SG_ 2566733310 Aftrtrtmnt1DslExhstFldTnk2LvlPrl "Used to identify the applicable J1939-73 FMI detected in the diesel exhaust fluid tank 2 level, by the manufacturer’s ...";
CM_ SG_ 2566733310 Aftrtrtmnt1DslExhstFldTnk2Level2 "The diesel exhaust fluid tank 2 level height in mm for aftertreatment system 1 (exhaust bank 1).  Tank 2 is used as a quick ...";
CM_ SG_ 2566733310 Aftrtrtmnt1DslExhstFlidTank2Temp "The diesel exhaust fluid tank 2 temperature for aftertreatment system 1 (exhaust bank 1).  Tank 2 is used as a quick thaw ...";
CM_ SG_ 2566733310 Aftrtrtmnt1DslExhstFldTank2Level "The diesel exhaust fluid tank 2 level percentage for aftertreatment system 1 (exhaust bank 1).  0% is empty and 100% is ...";
CM_ BO_ 2566733054 "This message contains diesel exhaust fluid supply information for aftertreatment system 1 (or bank 1).";
CM_ SG_ 2566733054 Aftrtrtmnt1DslExhstFldTnkDrnVlvC "Commanded percentage of maximum Aftertreatment 1 Diesel Exhaust Fluid Tank Drain Valve opening. 100% means the ...";
CM_ SG_ 2566733054 Aftrtrtmnt1DslExhstFlidPumpState "State of Aftertreatment 1 Diesel Exhaust Fluid dosing pump.";
CM_ SG_ 2566733054 Aftrtrtmnt1DslExhstFldTnkFllVlvC "Commanded percentage of maximum Aftertreatment 1 Diesel Exhaust Fluid Tank Fill Valve opening. 100% means the fill ...";
CM_ SG_ 2566733054 Aftrtrtmnt1DslExhstFldRturnValve "Command to the valve which determines whether the diesel exhaust fluid is delivered to the injector or is routed back to ...";
CM_ SG_ 2566733054 Aftrtrtmnt1DslExhstFldPmpDrvPrcn "The percent (command) sent to the motor to control the speed of the diesel exhaust fluid pump.";
CM_ SG_ 2566733054 Aftrtrtmnt1DslExhstFldPmpMtrSped "Rotational speed of the motor driving a pump for diesel exhaust fluid used in an aftertreatment system.";
CM_ BO_ 2499624702 "This message contains SCR catalyst intake and outlet exhaust gas temperature information for aftertreatment system 1 ...";
CM_ SG_ 2499624702 Aftrtrtmnt1SCRCtlystOtltGsTmpPrl "Used to identify the applicable J1939-73 FMI detected in the SCR catalyst outlet gas temperature sensor by the ...";
CM_ SG_ 2499624702 Aftrtrtmnt1SCRCtlystOtletGasTemp "Temperature of engine combustion byproducts leaving the SCR catalyst exhaust in exhaust bank 1.";
CM_ SG_ 2499624702 Aftrtrtmnt1SCRCtlystIntkGsTmpPrl "Used to identify the applicable J1939-73 FMI detected in the SCR catalyst intake gas temperature sensor by the ...";
CM_ SG_ 2499624702 Aftrtrtmnt1SCRCtlystIntkeGasTemp "Temperature of engine combustion byproducts entering the SCR catalyst in exhaust bank 1.";
CM_ BO_ 2566733822 "This message contains SCR catalyst exhaust gas pressure information for aftertreatment system 1 (or bank 1).";
CM_ SG_ 2566733822 Aftrtrtmnt1SCRExhstGsDffPrssPrlm "Used to identify the applicable J1939-73 FMI detected in the SCR differential pressure sensor by the manufacturer’s ...";
CM_ SG_ 2566733822 Aftrtrtmnt1SCRExhustGasDiffPress "Exhaust differential pressure measured between the intake and exhaust of an SCR component in exhaust bank 1.";
CM_ BO_ 2566734078 "This message contains SCR dosing system request information for aftertreatment system 1 (or bank 1).  See PGN 61476 ...";
CM_ SG_ 2566734078 Aftrtrtmnt1DslExhstFldPmpHterCmd "Command for the Aftertreatment 1 Diesel Exhaust Fluid Pump Heater. A value of 0% means no heating commanded, a ...";
CM_ SG_ 2566734078 Aftrtrtmnt1DslExhstFldTnk2HtrCmd "This is the command for the Aftertreatment 1 Diesel Exhaust Fluid Tank 2 Heater.  See SPN 4372 for the measured value ...";
CM_ SG_ 2566734078 Aftrtrtmnt1DslExhstFldTnkHterCmd "Command for the Aftertreatment 1 Diesel Exhaust Fluid Tank Heater.  A value of 0% means no heating applied, a value ...";
CM_ SG_ 2566734078 Aftrtrtmnt1DslExhstFldLneHeater4 "The diesel exhaust fluid line heater 4 request for aftertreatment system 1 (exhaust bank 1).";
CM_ SG_ 2566734078 Aftrtrtmnt1DslExhstFldLneHeater3 "The diesel exhaust fluid line heater 3 request for aftertreatment system 1 (exhaust bank 1).";
CM_ SG_ 2566734078 Aftrtrtmnt1DslExhstFldLneHeater2 "The diesel exhaust fluid line heater 2 request for aftertreatment system 1 (exhaust bank 1).";
CM_ SG_ 2566734078 Aftrtrtmnt1DslExhstFldLneHeater1 "The diesel exhaust fluid line heater 1 request for aftertreatment system 1 (exhaust bank 1).";
CM_ SG_ 2566734078 Aftrtrtmnt1DslExhstFldDsrHtngMdR "Used if multiple heater modes are available in the Doser.";
CM_ SG_ 2566734078 Aftrtrtmnt1DslExhstFldDsrFltSppr "Used if external devices can warn of conditions that require suppression of potential faults in the doser due to ...";
CM_ BO_ 2364548350 "This message contains SCR dosing system request information for aftertreatment system 1 (or bank 1).  See PGN 64832 ...";
CM_ SG_ 2364548350 Aftrtrtmnt1DslExhstFldRqstdQntty "Represents the command for the diesel exhaust fluid quantity integrator in the dosing control unit ...";
CM_ SG_ 2364548350 Aftrtrtmnt1SCRSystmRquestedState "Requested state of SCR system for aftertreatment system 1 (exhaust bank 1).";
CM_ SG_ 2364548350 Aftrtrtmnt1DslExhstFldDsngRqstdQ "Actual requested dosing quantity of diesel exhaust fluid.";
CM_ BO_ 2566734334 "This message contains SCR dosing system information for aftertreatment system 1 (or bank 1).  See PGN 61475 for ...";
CM_ SG_ 2566734334 Aftrtrtmnt1DslExhstFldLnHtr4Prlm "Used to identify the applicable J1939-73 FMI detected in the diesel exhaust fluid line heater 4, by the manufacturer’s ...";
CM_ SG_ 2566734334 Aftrtrtmnt1DslExhstFldLnHtr4Stte "The diesel exhaust fluid line heater 4 state for aftertreatment system 1 (exhaust bank 1).";
CM_ SG_ 2566734334 Aftrtrtmnt1DslExhstFldLnHtr3Prlm "Used to identify the applicable J1939-73 FMI detected in the diesel exhaust fluid line heater 3, by the manufacturer’s ...";
CM_ SG_ 2566734334 Aftrtrtmnt1DslExhstFldLnHtr3Stte "The diesel exhaust fluid line heater 3 state for aftertreatment system 1 (exhaust bank 1).";
CM_ SG_ 2566734334 Aftrtrtmnt1DslExhstFldLnHtr2Prlm "Used to identify the applicable J1939-73 FMI detected in the diesel exhaust fluid line heater 2, by the manufacturer’s ...";
CM_ SG_ 2566734334 Aftrtrtmnt1DslExhstFldLnHtr2Stte "The diesel exhaust fluid line heater 2 state for aftertreatment system 1 (exhaust bank 1).";
CM_ SG_ 2566734334 Aftrtrtmnt1DslExhstFldLnHtr1Prlm "Used to identify the applicable J1939-73 FMI detected in the diesel exhaust fluid line heater 1, by the manufacturer’s ...";
CM_ SG_ 2566734334 Aftrtrtmnt1DslExhstFldLnHtr1Stte "The diesel exhaust fluid line heater 1 state for aftertreatment system 1 (exhaust bank 1).";
CM_ SG_ 2566734334 Aftrtrtmnt1SCRFeedbackCtrlStatus "The SCR feedback control status (open/closed loop) for aftertreatment system 1 (exhaust bank 1).";
CM_ SG_ 2566734334 Aftrtrtmnt1SCRDsngVlvExhstTmpRdc "Protection request for the dosing valve of the SCR-system to prevent overheating ...";
CM_ SG_ 2566734334 Aftrtrtmnt1DslExhstFldDosingTemp "The diesel exhaust fluid dosing temperature (measured closest to dosing valve) for aftertreatment system 1 (exhaust ...";
CM_ SG_ 2566734334 Aftrtrtmnt1SCRDsngAirAssistValve "The position of the valve used to regulate the air supply of an air assist SCR dosing system for an engine. 0% represents ...";
CM_ SG_ 2566734334 Aftrtrtmnt1SCRDsngArAssstAbsPrss "The SCR dosing system air assist absolute pressure for aftertreatment system 1 (exhaust bank 1).  The air assist system ...";
CM_ BO_ 2364548094 "This message contains SCR dosing system information for aftertreatment system 1 (or bank 1).  See PGN 64833 for ...";
CM_ SG_ 2364548094 Aftrtrtmnt1DslExhstFldDsrAbsPrss "The SCR dosing diesel exhaust fluid absolute pressure (measured closest to dosing valve) for aftertreatment system 1 ...";
CM_ SG_ 2364548094 Aftrtrtmnt1DslExhstFldActlQnttyO "The SCR requested diesel exhaust fluid integrator total quantity for aftertreatment system 1 (exhaust bank 1).";
CM_ SG_ 2364548094 Aftertreatment1SCRSystemState "Actual state of SCR system ...";
CM_ SG_ 2364548094 Aftrtrtmnt1DslExhstFldActlDsngQn "Actual reducing agent quantity of SCR-system ...";
CM_ BO_ 2364548606 "This message contains aftertreatment outlet ammonia information for aftertreatment system 1 (or bank 1).";
CM_ SG_ 2364548606 Aftrtrtmnt1OtltNH3GsSnsrHterCtrl "Indicates the heater status in the warm-up process. Upon receiving a power-up command, the NH3 gas sensor ramps up ...";
CM_ SG_ 2364548606 Aftrtrtmnt1OtltNH3GsSnsrHtrPrlmn "Used to identify the applicable J1939-73 FMI detected in the heater of the outlet NH3 exhaust gas sensor by the ...";
CM_ SG_ 2364548606 Aftrtrtmnt1OtltNH3GsSensorAtTemp "Indicates that the heater element of the aftertreatment outlet NH3 gas sensor is within the manufacturer’s specified range ...";
CM_ SG_ 2364548606 Aftrtrtmnt1OtltNH3GsSnsrPwrInRng "Indicates that the power supplied to the aftertreatment outlet NH3 gas sensor is within the manufacturer’s specification in ...";
CM_ SG_ 2364548606 Aftrtrtmnt1OtletNH3ReadingStable "Indicates that the NH3 reading of the aftertreatment outlet NH3 sensor is stable as determined by the manufacturer’s ...";
CM_ SG_ 2364548606 Aftrtrtmnt1OtltNH3SnsrPrlmnryFMI "Used to identify the applicable J1939-73 FMI detected in the aftertreatment outlet NH3 sensor by the manufacturer’s ...";
CM_ SG_ 2364548606 Aftertreatment1OutletNH3 "The amount of NH3 in the exhaust exiting the aftertreatment system measured by a NH3 sensor at the aftertreatment ...";
CM_ BO_ 2566726398 "The purpose of this PGN is to group the aftertreatment gas oxidation catalyst data for bank 1. These values include the ...";
CM_ SG_ 2566726398 Aftrtrtmnt1GsOxdtnCtlystDffPrssP "Used to identify the applicable J1939-73 FMI detected in the gas oxidation catalyst differential pressure sensor by the ...";
CM_ SG_ 2566726398 Aftrtrtmnt1GsOxdtnCtlystOtlt4757 "Used to identify the applicable J1939-73 FMI detected in the gas oxidation catalyst outlet gas temperature sensor by the ...";
CM_ SG_ 2566726398 Aftrtrtmnt1GsOxdtnCtlystIntk4756 "Used to identify the applicable J1939-73 FMI detected in the gas oxidation catalyst intake gas temperature sensor by the ...";
CM_ SG_ 2566726398 Aftrtrtmnt1GsOxdtnCtlystDffPress "Exhaust differential pressure measured between the intake and exhaust of the gas oxidation catalyst in exhaust bank 1.";
CM_ SG_ 2566726398 Aftrtrtmnt1GsOxdtnCtlystOtltGsTm "Temperature of engine combustion byproducts leaving the gas oxidation catalyst in exhaust bank 1.  This gas parameter ...";
CM_ SG_ 2566726398 Aftrtrtmnt1GsOxdtnCtlystIntkGsTm "Temperature of engine combustion byproducts entering the gas oxidation catalyst in exhaust bank 1.  This gas parameter ...";
CM_ BO_ 2566742270 "HB1C provides the system specific individual B1 failure counters";
CM_ SG_ 2566742270 FailureSpecificB1Counter "The Failure Specific B1 Counter provides an individual B1 counter";
CM_ SG_ 2566742270 FailureModeIdentifier1 "The FMI defines the type of failure detected in the subsystem identified by an SPN.";
CM_ SG_ 2566742270 SPN1High "SPN #1 (Conversion Version 4)";
CM_ SG_ 2566742270 SPN1 "SPN #1 (Conversion Version 4)";
CM_ BO_ 2566742526 "Cumulative Continuous MI-System";
CM_ SG_ 2566742526 SysGreatestB1Counter "System Greatest B1 Counter";
CM_ SG_ 2566742526 SysCumulativeContinuousMITime "System Cumulative Continuous MI Time";
CM_ BO_ 2566742782 "Harmonized Global Regulation Description";
CM_ SG_ 2566742782 RegulationDescription "Global Technical Regulation Description";
CM_ BO_ 2566743038 "Harmonized Roadworthiness";
CM_ SG_ 2566743038 SysIncompleteMonitorCount "System Incomplete Monitor Count";
CM_ SG_ 2566743038 SysMalIndActivationMode "System Malfunction Indicator Status";
CM_ SG_ 2566743038 SysMalIndDisplayStrategy "System Malfunction Indicator Display";
CM_ SG_ 2566743038 SysContinuousMalfunctionInd "System Continuous Malfunction Indicator";
CM_ SG_ 2566743038 SysNonRoadworthyCompCount "System Non-Roadworthy Component Count";
CM_ BO_ 2566743294 "Harmonized Roadworthiness ";
CM_ SG_ 2566743294 VehicleCurrentMIAccumTime "Vehicle Current MI Accumulated Time";
CM_ SG_ 2566743294 VehicleIncompleteMonitorCount "Vehicle Incomplete Monitor Count";
CM_ SG_ 2566743294 VehicleMalfunctionIndActMode "Vehicle Malfunction Indicator Status ";
CM_ SG_ 2566743294 VehicleMalfunctionIndStrategy "Vehicle Malfunction Indicator Display Strategy ";
CM_ SG_ 2566743294 VehicleContinuousMalfunctionInd "Vehicle Continuous Malfunction Indicator";
CM_ SG_ 2566743294 VehicleNonRoadworthyCompCount "Vehicle Non-Roadworthy Component Count";
CM_ BO_ 2560687870 "The status of engine operating in the NTE control areas for given pollutants, such as NOx and PM";
CM_ SG_ 2560687870 PMNTEDeficiencyAreaStatus "Status of engine operation within the PM NTE Deficiency Area";
CM_ SG_ 2560687870 MnfcPMNTECarveOutAreaStatus "Status of engine operation within the manufacturer specific PM NTE carve out area";
CM_ SG_ 2560687870 PMNTEControlAreaStatus "Status of engine operation within the bounded region of the engine's torque and speed map.";
CM_ SG_ 2560687870 NOxNTEDeficiencyAreaStatus "Status of engine operation within the NOx NTE Deficiency Area";
CM_ SG_ 2560687870 MnfcNOxNTECarveOutAreaStatus "Status of engine operation within the bounded region of the engine's torque and speed map.";
CM_ SG_ 2560687870 NOxNTEControlAreaStatus "Status of engine operation within the bounded region of the engine's torque and speed map.";
CM_ BO_ 2292317950 "The total engine run time while each of the Emission Increasing Auxiliary Emission Control Devices is active";
CM_ SG_ 2292317950 AECDEngineHours1Timer2 "The total engine running hours recorded in the second timer for the EI-AECD";
CM_ SG_ 2292317950 AECDEngineHours1Timer1 "The total engine running hours recorded in the first timer for the EI-AECD";
CM_ SG_ 2292317950 AECDNumber1 "The manufacturer assigned number for the specific EI-AECD";
CM_ SG_ 2566809342 BatteryMainSwitchHoldState "Parameter indicating whether the battery main switch is held due to an external request or not. The state battery main ...";
CM_ BO_ 2365446910 "Used to transfer information about the measured status of the 1st 2 axes and up to 12 buttons of a joystick.  Additional ...";
CM_ SG_ 2365446910 Joystick3XAxisDetentPosStatus "Reports when the current joystick position is in the detent position for that axis of travel.";
CM_ SG_ 2365446910 Joystick3Button9PressedStatus "Reports when the joystick button has been pressed.";
CM_ SG_ 2365446910 Joystick3Button10PressedStatus "Reports when the joystick button has been pressed.";
CM_ SG_ 2365446910 Joystick3Button11PressedStatus "Reports when the joystick button has been pressed.";
CM_ SG_ 2365446910 Joystick3Button12PressedStatus "Reports when the joystick button has been pressed.";
CM_ SG_ 2365446910 Joystick3YAxisDetentPosStatus "Reports when the current joystick position is in the detent position for that axis of travel.";
CM_ SG_ 2365446910 Joystick3YAxisPos "The position of the joystick in the relative motion of travel from the neutral position.  Position value of 0 is Neutral and ...";
CM_ SG_ 2365446910 Jystck3YAxsLvrFrwrdPstvPosStatus "Reports when the current joystick position is on the positive travel side (forward, right, clockwise, up) relative to the ...";
CM_ SG_ 2365446910 Jystck3YAxsLvrBckNgtivePosStatus "Reports when the current joystick position is on the negative travel side (back, left, counterclockwise, down) relative to the ...";
CM_ SG_ 2365446910 Joystick3YAxisNeutralPosStatus "Reports when the current joystick position is in the neutral position for that axis of travel.  The neutral position ...";
CM_ SG_ 2365446910 Joystick3XAxisPos "The position of the joystick in the relative motion of travel from the neutral position.  Position value of 0 is Neutral and ...";
CM_ SG_ 2365446910 Jystck3XAxsLvrRghtPstvePosStatus "Reports when the current joystick position is on the positive travel side (forward, right, clockwise, up) relative to the ...";
CM_ SG_ 2365446910 Jystck3XAxsLvrLftNgtivePosStatus "Reports when the current joystick position is on the negative travel side (back, left, counterclockwise, down) relative to the ...";
CM_ SG_ 2365446910 Joystick3XAxisNeutralPosStatus "Reports when the current joystick position is in the neutral position for that axis of travel.  The neutral position ...";
CM_ SG_ 2365446910 Joystick3Button5PressedStatus "Reports when the joystick button has been pressed.";
CM_ SG_ 2365446910 Joystick3Button6PressedStatus "Reports when the joystick button has been pressed.";
CM_ SG_ 2365446910 Joystick3Button7PressedStatus "Reports when the joystick button has been pressed.";
CM_ SG_ 2365446910 Joystick3Button8PressedStatus "Reports when the joystick button has been pressed.";
CM_ SG_ 2365446910 Joystick3Button1PressedStatus "Reports when the joystick button has been pressed.";
CM_ SG_ 2365446910 Joystick3Button2PressedStatus "Reports when the joystick button has been pressed.";
CM_ SG_ 2365446910 Joystick3Button3PressedStatus "Reports when the joystick button has been pressed.";
CM_ SG_ 2365446910 Joystick3Button4PressedStatus "Reports when the joystick button has been pressed.";
CM_ BO_ 2365446398 "Used to transfer information about the measured status of the 1st 2 axes and up to 12 buttons of a joystick.  Additional ...";
CM_ SG_ 2365446398 Joystick2XAxisDetentPosStatus "Reports when the current joystick position is in the detent position for that axis of travel.";
CM_ SG_ 2365446398 Joystick2YAxisDetentPosStatus "Reports when the current joystick position is in the detent position for that axis of travel.";
CM_ SG_ 2365446398 Joystick2YAxisPos "The position of the joystick in the relative motion of travel from the neutral position.  Position value of 0 is Neutral and ...";
CM_ SG_ 2365446398 Jystck2YAxsLvrFrwrdPstvPosStatus "Reports when the current joystick position is on the positive travel side (forward, right, clockwise, up) relative to the ...";
CM_ SG_ 2365446398 Jystck2YAxsLvrBckNgtivePosStatus "Reports when the current joystick position is on the negative travel side (back, left, counterclockwise, down) relative to the ...";
CM_ SG_ 2365446398 Joystick2YAxisNeutralPosStatus "Reports when the current joystick position is in the neutral position for that axis of travel.  The neutral position ...";
CM_ SG_ 2365446398 Joystick2XAxisPos "The position of the joystick in the relative motion of travel from the neutral position.  Position value of 0 is Neutral and ...";
CM_ SG_ 2365446398 Jystck2XAxsLvrRghtPstvePosStatus "Reports when the current joystick position is on the positive travel side (forward, right, clockwise, up) relative to the ...";
CM_ SG_ 2365446398 Jystck2XAxsLvrLftNgtivePosStatus "Reports when the current joystick position is on the negative travel side (back, left, counterclockwise, down) relative to the ...";
CM_ SG_ 2365446398 Joystick2XAxisNeutralPosStatus "Reports when the current joystick position is in the neutral position for that axis of travel.  The neutral position ...";
CM_ SG_ 2365446398 Joystick2Button9PressedStatus "Reports when the joystick button has been pressed.";
CM_ SG_ 2365446398 Joystick2Button10PressedStatus "Reports when the joystick button has been pressed.";
CM_ SG_ 2365446398 Joystick2Button11PressedStatus "Reports when the joystick button has been pressed.";
CM_ SG_ 2365446398 Joystick2Button12PressedStatus "Reports when the joystick button has been pressed.";
CM_ SG_ 2365446398 Joystick2Button5PressedStatus "Reports when the joystick button has been pressed.";
CM_ SG_ 2365446398 Joystick2Button6PressedStatus "Reports when the joystick button has been pressed.";
CM_ SG_ 2365446398 Joystick2Button7PressedStatus "Reports when the joystick button has been pressed.";
CM_ SG_ 2365446398 Joystick2Button8PressedStatus "Reports when the joystick button has been pressed.";
CM_ SG_ 2365446398 Joystick2Button1PressedStatus "Reports when the joystick button has been pressed.";
CM_ SG_ 2365446398 Joystick2Button2PressedStatus "Reports when the joystick button has been pressed.";
CM_ SG_ 2365446398 Joystick2Button3PressedStatus "Reports when the joystick button has been pressed.";
CM_ SG_ 2365446398 Joystick2Button4PressedStatus "Reports when the joystick button has been pressed.";
CM_ BO_ 2365445886 "Used to transfer information about the measured status of the 1st 2 axes and up to 12 buttons of a joystick.  Additional ...";
CM_ SG_ 2365445886 Joystick1XAxisDetentPosStatus "Reports when the current joystick position is in the detent position for that axis of travel.";
CM_ SG_ 2365445886 Joystick1YAxisDetentPosStatus "Reports when the current joystick position is in the detent position for that axis of travel.";
CM_ SG_ 2365445886 Joystick1YAxisPos "The position of the joystick in the relative motion of travel from the neutral position.  Position value of 0 is Neutral and ...";
CM_ SG_ 2365445886 Jystck1YAxsLvrFrwrdPstvPosStatus "Reports when the current joystick position is on the positive travel side (forward, right, clockwise, up) relative to the ...";
CM_ SG_ 2365445886 Jystck1YAxsLvrBckNgtivePosStatus "Reports when the current joystick position is on the negative travel side (back, left, counterclockwise, down) relative to the ...";
CM_ SG_ 2365445886 Joystick1YAxisNeutralPosStatus "Reports when the current joystick position is in the neutral position for that axis of travel.  The neutral position ...";
CM_ SG_ 2365445886 Joystick1XAxisPos "The position of the joystick in the relative motion of travel from the neutral position.  Position value of 0 is Neutral and ...";
CM_ SG_ 2365445886 Joystick1Button9PressedStatus "Reports when the joystick button has been pressed.";
CM_ SG_ 2365445886 Joystick1Button10PressedStatus "Reports when the joystick button has been pressed.";
CM_ SG_ 2365445886 Joystick1Button11PressedStatus "Reports when the joystick button has been pressed.";
CM_ SG_ 2365445886 Joystick1Button12PressedStatus "Reports when the joystick button has been pressed.";
CM_ SG_ 2365445886 Joystick1Button5PressedStatus "Reports when the joystick button has been pressed.";
CM_ SG_ 2365445886 Joystick1Button6PressedStatus "Reports when the joystick button has been pressed.";
CM_ SG_ 2365445886 Joystick1Button7PressedStatus "Reports when the joystick button has been pressed.";
CM_ SG_ 2365445886 Joystick1Button8PressedStatus "Reports when the joystick button has been pressed.";
CM_ SG_ 2365445886 Joystick1Button1PressedStatus "Reports when the joystick button has been pressed.";
CM_ SG_ 2365445886 Joystick1Button2PressedStatus "Reports when the joystick button has been pressed.";
CM_ SG_ 2365445886 Joystick1Button3PressedStatus "Reports when the joystick button has been pressed.";
CM_ SG_ 2365445886 Joystick1Button4PressedStatus "Reports when the joystick button has been pressed.";
CM_ SG_ 2365445886 Jystck1XAxsLvrRghtPstvePosStatus "Reports when the current joystick position is on the positive travel side (forward, right, clockwise, up) relative to the ...";
CM_ SG_ 2365445886 Jystck1XAxsLvrLftNgtivePosStatus "Reports when the current joystick position is on the negative travel side (back, left, counterclockwise, down) relative to the ...";
CM_ SG_ 2365445886 Joystick1XAxisNeutralPosStatus "Reports when the current joystick position is in the neutral position for that axis of travel.  The neutral position ...";
CM_ BO_ 2566847230 "Brakes";
CM_ SG_ 2566847230 ParkingBrakeRedWarningSignal "This parameter commands the Parking Brake red optical warning signal.";
CM_ SG_ 2566847230 ParkBrakeReleaseInhibitStatus "This parameter provides reports on the status of the Park Brake Release Inhibit function.";
CM_ SG_ 2566847230 ParkingBrakeActuator "Signal which indicates the current state of the actuator(s) that control the parking brake (see also SPN 70 and 5275).";
CM_ SG_ 2566847230 BrakeSecondPress "Gage pressure of air in the secondary, or service side, of the air brake system.";
CM_ SG_ 2566847230 BrakePrimaryPress "Gage pressure of air in the primary, or supply side, of the air brake system.";
CM_ SG_ 2566847230 BrakeAppPress "Gage pressure of compressed air or fluid in vehicle braking system measured at the brake chamber when brake shoe (or ...";
CM_ SG_ 2566848254 AuxPumpPress "Gage pressure of auxiliary water pump driven as a PTO device.";
CM_ BO_ 2566725886 "The purpose of this PGN is to group the aftertreatment diesel oxidation catalyst data for bank 1. These values include the ...";
CM_ SG_ 2566725886 Aftrtrtmnt1DslOxdtnCtlystDff4770 "Used to identify the applicable J1939-73 FMI detected in the diesel oxidation catalyst differential pressure sensor by the ...";
CM_ SG_ 2566725886 Aftrtrtmnt1DslOxdtnCtlystOtl4769 "Used to identify the applicable J1939-73 FMI detected in the diesel oxidation catalyst outlet gas temperature sensor by ...";
CM_ SG_ 2566725886 Aftrtrtmnt1DslOxdtnCtlystInt4768 "Used to identify the applicable J1939-73 FMI detected in the diesel oxidation catalyst intake gas temperature sensor by ...";
CM_ SG_ 2566725886 Aftrtrtmnt1DslOxdtnCtlystDffPrss "Exhaust differential pressure measured between the intake and exhaust of a diesel oxidation catalyst in exhaust bank 1.";
CM_ SG_ 2566725886 Aftrtrtmnt1DslOxdtnCtlystOtltGsT "Temperature of engine combustion byproducts leaving the diesel oxidation catalyst exhaust in exhaust bank 1.  This ...";
CM_ SG_ 2566725886 Aftrtrtmnt1DslOxdtnCtlystIntkGsT "Temperature of engine combustion byproducts entering the diesel oxidation catalyst in exhaust bank 1.  This diesel ...";
CM_ BO_ 2560884478 "This message shall provide the applicable lamp for each individual DTC";
CM_ SG_ 2560884478 DTCWarnLampSupportStatus "Lamp support status";
CM_ SG_ 2560884478 DTCWarnLampSupportFlash "Lamp support status";
CM_ SG_ 2560884478 DTCStopLampSupportStatus "Lamp support status";
CM_ SG_ 2560884478 DTCStopLampSupportFlash "Lamp support status";
CM_ SG_ 2560884478 DTCProtectLampSupportStatus "Lamp support status";
CM_ SG_ 2560884478 DTCProtectLampSupportFlash "Lamp support status";
CM_ SG_ 2560884478 DTCMilSupportStatus "Lamp support status";
CM_ SG_ 2560884478 DTCMilSupportFlash "Lamp support status";
CM_ SG_ 2560884478 DTC1 "Diagnostic Trouble Code";
CM_ BO_ 2633844734 "ASCII text string describing a manufacturer-specific Transmission Mode.  This PGN may contain up to 8 instances of the ...";
CM_ BO_ 2560360190 "This is a standardized mechanism for an ECU to report a listing of the manufacturer specific (i.e. proprietary) methods ...";
CM_ SG_ 2560360190 DataDictionaryMethod "A manufacturer defined code to define the proprietary communications method.  The structure and interpretation of the ...";
CM_ SG_ 2560360190 DataDictionaryManufacturerCode "The J1939 Manufacturer Code (see J1939 Table B10) associated with the manufacturer who defined the proprietary ...";
CM_ BO_ 2566736126 "Provides bank 2 short-term and long-term fuel trim values ...";
CM_ SG_ 2566736126 EngExhstGsOxygnSnsrClsdLpOprtnBn "This parameter indicates the status of the bank 2 O2 sensor feedback closed loop operation ...";
CM_ SG_ 2566736126 ShorttermFuelTrimBank2 "This parameter is the short-term percent change in fueling based on the O2 sensor feedback for cylinder bank 2, based ...";
CM_ SG_ 2566736126 LongtermFuelTrimBank2 "This parameter is the long-term percent change in fueling based on the O2 sensor feedback for cylinder bank 2, based on ...";
CM_ BO_ 2566736382 "Provides bank 1 short-term and long-term fuel trim values ...";
CM_ SG_ 2566736382 EngExhstGsOxygnSnsrClsdLpOprtnBn "This parameter indicates the status of the bank 1 O2 sensor feedback closed loop operation ...";
CM_ SG_ 2566736382 ShorttermFuelTrimBank1 "This parameter is the short-term percent change in fueling based on the O2 sensor feedback for cylinder bank 1, based ...";
CM_ SG_ 2566736382 LongtermFuelTrimBank1 "This parameter is the long-term percent change in fueling based on the O2 sensor feedback for cylinder bank 1, based on ...";
CM_ BO_ 2565874174 "This PGN contains the speed information and status signal of each engine speed sensor. This message is used for ...";
CM_ SG_ 2565874174 EngSpdSensor1TimingPatternStatus "This is the timing pattern status of the engine speed sensor signal for sensor 1.   The sensor may be sending a speed ...";
CM_ SG_ 2565874174 EngSpdSensor2TimingPatternStatus "This is the timing pattern status of the engine speed sensor signal for sensor 2.  The sensor may be sending a speed ...";
CM_ SG_ 2565874174 EngSpdSensor3TimingPatternStatus "This is the timing pattern status of the engine speed sensor signal for sensor 3.  The sensor may be sending a speed ...";
CM_ SG_ 2565874174 EngSpeed3 "The engine speed as measured by speed sensor 3.";
CM_ SG_ 2565874174 EngSpeed2 "The engine speed as measured by speed sensor 2 ...";
CM_ SG_ 2565874174 EngSpeed1 "The engine speed as measured by speed sensor 1.";
CM_ BO_ 2432520958 "Transmit status information from the Master ECU to an electronic thermostat ...";
CM_ SG_ 2432520958 EngAxClerSupplyValve2ActuatorCmd "The control command applied to the engine auxiliary cooler supply valve 2 actuator, where 0% represents closed and ...";
CM_ SG_ 2432520958 EngAxClerSupplyValve1ActuatorCmd "The control command applied to the engine auxiliary cooler supply valve 1 actuator, where 0% represents closed and ...";
CM_ SG_ 2432520958 DsredEngCoolantThermostatOpening "Indicates the desired position of the engine coolant control valve.   0% represents the thermostat allows flow to ...";
CM_ SG_ 2432520958 DesiredEngCoolantPumpOutletTemp "Desired engine coolant temperature of the engine to an electronic thermostat.  If the electronic thermostat valve is ...";
CM_ SG_ 2432520958 EngCoolantThermostatMode "Specifies if the engine coolant thermostat valve will operate in temperature control mode or position control mode.";
CM_ BO_ 2560425726 "Notes: Implementers are encouraged to use specific functional SPNs whenever possible.";
CM_ SG_ 2560425726 AuxI_OChannel19 "Identifies the current value of auxiliary input/output channels that are configured uniquely per application.";
CM_ SG_ 2560425726 AuxI_OChannel20 "Identifies the current value of auxiliary input/output channels that are configured uniquely per application.";
CM_ SG_ 2560425726 AuxI_OChannel21 "Identifies the current value of auxiliary input/output channels that are configured uniquely per application.";
CM_ SG_ 2560425726 AuxI_OChannel22 "Identifies the current value of auxiliary input/output channels that are configured uniquely per application.";
CM_ SG_ 2560425726 AuxI_OChannel15 "Identifies the current value of auxiliary input/output channels that are configured uniquely per application.";
CM_ SG_ 2560425726 AuxI_OChannel16 "Identifies the current value of auxiliary input/output channels that are configured uniquely per application.";
CM_ SG_ 2560425726 AuxI_OChannel17 "Identifies the current value of auxiliary input/output channels that are configured uniquely per application.";
CM_ SG_ 2560425726 AuxI_OChannel18 "Identifies the current value of auxiliary input/output channels that are configured uniquely per application.";
CM_ BO_ 2560491262 "Notes: Implementers are encouraged to use specific functional SPNs whenever possible.";
CM_ SG_ 2560491262 AuxI_OChannel11 "Identifies the current value of auxiliary input/output channels that are configured uniquely per application.";
CM_ SG_ 2560491262 AuxI_OChannel12 "Identifies the current value of auxiliary input/output channels that are configured uniquely per application.";
CM_ SG_ 2560491262 AuxI_OChannel13 "Identifies the current value of auxiliary input/output channels that are configured uniquely per application.";
CM_ SG_ 2560491262 AuxI_OChannel14 "Identifies the current value of auxiliary input/output channels that are configured uniquely per application.";
CM_ SG_ 2560491262 AuxI_OChannel7 "Identifies the current value of auxiliary input/output channels that are configured uniquely per application.";
CM_ SG_ 2560491262 AuxI_OChannel8 "Identifies the current value of auxiliary input/output channels that are configured uniquely per application.";
CM_ SG_ 2560491262 AuxI_OChannel9 "Identifies the current value of auxiliary input/output channels that are configured uniquely per application.";
CM_ SG_ 2560491262 AuxI_OChannel10 "Identifies the current value of auxiliary input/output channels that are configured uniquely per application.";
CM_ BO_ 2349399806 "Notes: Implementers are encouraged to use specific functional SPNs whenever possible.";
CM_ SG_ 2349399806 AuxI_OChannel3 "Identifies the current value of auxiliary input/output channels that are configured uniquely per application.";
CM_ SG_ 2349399806 AuxI_OChannel4 "Identifies the current value of auxiliary input/output channels that are configured uniquely per application.";
CM_ SG_ 2349399806 AuxI_OChannel5 "Identifies the current value of auxiliary input/output channels that are configured uniquely per application.";
CM_ SG_ 2349399806 AuxI_OChannel6 "Identifies the current value of auxiliary input/output channels that are configured uniquely per application.";
CM_ BO_ 2566758398 "Contains information about the aftertreatment 1 air system ...";
CM_ SG_ 2566758398 Aftertreatment1AirEnableActuator "Indicates whether aftertreatment 1 air enable actuator is on or off ...";
CM_ SG_ 2566758398 Aftertreatment1PurgeAirActuator "Indicates whether aftertreatment 1 purge air actuator is on or off ...";
CM_ SG_ 2566758398 Aftrtrtmnt1AtmizationAirActuator "Indicates whether aftertreatment 1 atomization air actuator is on or off ...";
CM_ SG_ 2566758398 Aftertreatment1AirSystemRelay "Indicates whether aftertreatment 1 air system relay is on or off ...";
CM_ SG_ 2566758398 Aftrtratment1AirPressActuatorPos "Position of the aftertreatment 1 air pressure actuator as measured by a position feedback sensor.";
CM_ SG_ 2566758398 Aftertreatment1AirPressCtrl "Position that the controller is commanding the aftertreatment 1 air pressure control to maintain.  0% = fully closed, 100% = ...";
CM_ SG_ 2566758398 Aftertreatment1PurgeAirPress "Pressure of the purge air supply for aftertreatment 1 ...";
CM_ SG_ 2566758398 Aftertreatment1SupplyAirPress "Pressure of the supply air for aftertreatment 1.  Supply air is the air supplied from a pneumatic line for an air-assisted or ...";
CM_ BO_ 2566745598 "This PGN contains information about the Aftertreatment 1 Air Control.";
CM_ SG_ 2566745598 Aftertreatment1SecondAirPress "Pressure of the secondary air for aftertreatment 1.  Secondary air is air provided to the exhaust system (per SAE J2403).";
CM_ SG_ 2566745598 Aftertreatment1SecondAirMassFlow "Indicates the secondary air mass flow for aftertreatment 1.  Secondary air is the air provided to the exhaust system (per ...";
CM_ SG_ 2566745598 Aftertreatment1SecondAirTemp "Indicates the secondary air temperature for aftertreatment 1.  Secondary air is air provided to the exhaust system (per ...";
CM_ SG_ 2566745598 Aftrtreatment1SecondAirDiffPress "Indicates the secondary air differential pressure for aftertreatment 1.  Secondary air is air provided to the exhaust system ...";
CM_ BO_ 2566758910 "Contains information about the aftertreatment 1 fuel system ...";
CM_ SG_ 2566758910 Aftrtrtmnt1FlInjector1HeaterCtrl "Heating level that the controller is commanding the aftertreatment 1 fuel injector 1 heater control to maintain. 0% = off, ...";
CM_ SG_ 2566758910 Aftrtreatment1FuelEnableActuator "Indicates whether aftertreatment 1 fuel enable actuator is on or off ...";
CM_ SG_ 2566758910 Aftrtreatment1RegenerationStatus "Indicates whether regeneration is active or inactive in aftertreatment 1.";
CM_ SG_ 2566758910 Aftertreatment1Ignt "Indicates whether aftertreatment 1 ignition circuit is energized by the ECM.";
CM_ SG_ 2566758910 Aftertreatment1FuelDrainActuator "Indicates whether aftertreatment 1 fuel drain actuator is on or off ...";
CM_ SG_ 2566758910 Aftertreatment1FuelPress1Ctrl "Position that the controller is commanding the aftertreatment 1 fuel pressure control to maintain.  0% = fully closed, 100% ...";
CM_ SG_ 2566758910 Aftertreatment1FuelRate "Rate of fuel being delivered to aftertreatment 1 for regeneration ...";
CM_ SG_ 2566758910 Aftertreatment1FuelPress1 "First fuel pressure measurement for the aftertreatment 1 system ...";
CM_ BO_ 2566743550 "Contains information about the aftertreatment 1 fuel system.  See also PGN 64929.";
CM_ SG_ 2566743550 Aftrtrtmnt1HydrcrbnDsrIntkFlTemp "Measured temperature of the intake fuel to the hydrocarbon dosing device ...";
CM_ SG_ 2566743550 Aftrtrtmnt1FelPress2ActuatorCtrl "Indicates how the device is controlling the aftertreatment 1 fuel pressure 2 regulating control valve.   0% = fully closed, ...";
CM_ SG_ 2566743550 Aftrtrtmnt1FlFlwDverterValveCtrl "Indicates how the device is controlling the aftertreatment 1 fuel flow diverter valve. When this valve is on it diverts fuel flow ...";
CM_ SG_ 2566743550 Aftertreatment1FuelPumpRelayCtrl "Indicates how the device is controlling the aftertreatment 1 fuel pump relay.";
CM_ SG_ 2566743550 Aftertreatment1FuelPress2 "Second fuel pressure measurement for the aftertreatment 1 system ...";
CM_ BO_ 2566753534 "Diesel particulate filter gas parameters for system or bank 1 ...";
CM_ SG_ 2566753534 DslParticulateFilterOutletPress1 "This parameter indicates the diesel particulate filter outlet gage pressure 1 (bank 1).";
CM_ SG_ 2566753534 DslParticulateFilterIntakePress1 "This parameter indicates the diesel particulate filter intake gage pressure 1 (bank 1).";
CM_ BO_ 2566756606 "Contains information about the history of the aftertreatment 1 system ...";
CM_ SG_ 2566756606 Aftrtrtmnt1AvrgDstncBtwnActvDPFR "Indicates the average distance since last reset between active regenerations, that have not been forced to occur by ...";
CM_ SG_ 2566756606 Aftrtrtmnt1AvrgTmBtwnActvRgnrtns "Indicates the average time since last reset between active regenerations, that have not been forced to occur by manual ...";
CM_ SG_ 2566756606 Aftrtrtmnt1DslPrtcltFltrTtlN3728 "Total number of aftertreatment device 1 active regeneration manual requests by the operator over the lifetime of the ...";
CM_ SG_ 2566756606 Aftrtrtmnt1DslPrtcltFltrTtlN3727 "Total number of aftertreatment device 1 active regeneration inhibit requests by the operator over the lifetime of the device.";
CM_ SG_ 2566756606 Aftrtrtmnt1DslPrtcltFltrTtlNmbrO "Total number of passive regenerations by aftertreatment device 1 over the lifetime of the device.";
CM_ SG_ 2566756606 Aftrtrtmnt1DslPrtcltFltrTtlPssvR "Total amount of time that aftertreatment 1 diesel particulate filter has been in passive regeneration over the lifetime of the ...";
CM_ SG_ 2566756606 Aftrtrtmnt1TtlNmbrOfActvRgnrtons "Total number of active regenerations by aftertreatment device 1 over the lifetime of the device.";
CM_ SG_ 2566756606 Aftertreatment1TotalDisabledTime "Total amount of time that aftertreatment 1 regeneration has been manually disabled.";
CM_ SG_ 2566756606 Aftrtrtmnt1TotalRegenerationTime "Total amount of time that aftertreatment device 1 has been regenerating over the lifetime of the device.";
CM_ SG_ 2566756606 Aftertreatment1TotalFuelUsed "Total amount of fuel used by aftertreatment device 1 over the lifetime of the device.";
CM_ BO_ 2565869310 "The purpose of this PGN is to group the aftertreatment intake sensor data for bank 1.  These values include the NOx, ...";
CM_ SG_ 2565869310 Aftrtrtmnt1IntkOxygnSnsrPrlmnryF "Used to identify the applicable J1939-73 FMI detected in the aftertreatment intake oxygen sensor by the manufacturer’s ...";
CM_ SG_ 2565869310 NOxSensorATO1SelfdiagnosisStatus "Self-diagnosis result status for NOx sensor ATO1 (Aftertreatment Outlet Bank 1) ...";
CM_ SG_ 2565869310 Aftrtrtmnt1IntkNOxSnsrPrlmnryFMI "Used to identify the applicable J1939-73 FMI detected in the aftertreatment intake NOx sensor by the manufacturer’s ...";
CM_ SG_ 2565869310 Aftrtrtmnt1IntkGsSnsorHeaterCtrl "Indicates the heater status in the warm-up process.  Upon receiving a power-up command, the gas sensor ramps up ...";
CM_ SG_ 2565869310 Aftrtrtmnt1IntkGsSnsrHtrPrlmnryF "Used to identify the applicable J1939-73 FMI detected in the heater of the intake exhaust gas sensor, either NOx or O2, ...";
CM_ SG_ 2565869310 Aftrtrtmnt1IntkWdRngO2RdngStable "Indicates that the %O2 reading of the aftertreatment intake gas sensor, either NOx or O2, is stable as determined by the ...";
CM_ SG_ 2565869310 Aftrtrtmnt1IntkeNOxReadingStable "Indicates that the NOx reading of the aftertreatment intake NOx sensor is stable as determined by the manufacturer’s ...";
CM_ SG_ 2565869310 Aftrtrtmnt1IntakeGasSensorAtTemp "Indicates that the heater element of the aftertreatment intake gas sensor, either NOx or O2, is within the manufacturer’s ...";
CM_ SG_ 2565869310 Aftrtrtmnt1IntkGsSnsrPowerStatus "Indicates that the power supplied to the aftertreatment intake gas sensor, either NOx or O2, is within the manufacturer’s ...";
CM_ SG_ 2565869310 Aftertreatment1IntakeO2 "The actual oxidation factor (%O2) of the gas within the exhaust stream.  For positive values, the parameter represents the ...";
CM_ SG_ 2565869310 Aftertreatment1IntakeNOx "The amount of combined NO and NO2 in the exhaust entering the aftertreatment system measured by a NOx sensor at ...";
CM_ BO_ 2566763774 "The purpose of this PGN is to group the aftertreatment intake gas temperature messages for bank 1.";
CM_ SG_ 2566763774 Aftrtrtmnt1DslPrtcltFltrIntk3244 "Used to identify the applicable J1939-73 FMI detected in the diesel particulate filter intake gas temperature sensor by the ...";
CM_ SG_ 2566763774 Aftrtrtmnt1ExhstGsTmp1PrlmnryFMI "Used to identify the applicable J1939-73 FMI detected in the exhaust gas temperature 1 sensor by the manufacturer’s ...";
CM_ SG_ 2566763774 Aftrtrtmnt1DslPrtcltFltrIntkGsTm "Temperature of engine combustion byproducts entering the diesel particulate filter in exhaust bank 1.";
CM_ SG_ 2566763774 Aftertreatment1ExhaustGasTemp1 "The reading from the exhaust gas temperature sensor located farthest upstream in the aftertreatment system in exhaust ...";
CM_ BO_ 2631728894 "NOTE–See Figures PGN56320_A to PGN56320_F for examples of Anti-theft message transfers.  Bit 1 is the right most ...";
CM_ SG_ 2631728894 AntitheftRandomNumber "A seven byte random numeric code provided by the component in response to an anti-theft request.  This parameter is ...";
CM_ SG_ 2631728894 AntitheftModifyPwdStates "This parameter is used to indicate whether a password request was successfully performed, or if the request could not be ...";
CM_ SG_ 2631728894 AntitheftComponentStatusStates "Indicates whether or not the component can be started.";
CM_ SG_ 2631728894 AntitheftPwdValidIndicator "Indicates the presence of a validated password.";
CM_ SG_ 2631728894 AntthftEncryptnSdPrsentIndicator "Indicates the presence of the encryption seed random number.";
CM_ BO_ 2631794430 "NOTE–See Figures PGN56320_A thru PGN56320_F for examples of Anti-theft message transfers.  Bit 1 is the right most ...";
CM_ SG_ 2631794430 AntitheftPwdRepresentation "This parameter is the seven byte numeric code (i.e., ‘encrypted password’ or ‘key’) that is generated based on the ...";
CM_ SG_ 2631794430 AntitheftCmdStates "This parameter is used to identify the specific requests being sent to the component.";
CM_ SG_ 2631794430 AntitheftDesiredExitModeStates "This parameter is used to specify the desired triggers that are to be used by the component in deciding when to transition ...";
CM_ SG_ 2631794430 AntthftEncryptionIndicatorStates "This parameter is used to indicate if a random number seed is being requested, or if an encrypted password is being ...";
CM_ SG_ 2633934846 EngAltWinding3Temp "Temperature of the windings inside the alternator.";
CM_ SG_ 2633934846 EngAltWinding2Temp "Temperature of the windings inside the alternator.";
CM_ SG_ 2633934846 EngAltWinding1Temp "Temperature of the windings inside the alternator.";
CM_ SG_ 2633934846 EngAltBearing2Temp "Temperature of the bearing inside the alternator.  Bearing 2 is the right or front bearing.";
CM_ SG_ 2633934846 EngAltBearing1Temp "Temperature of the bearing inside the alternator.  Bearing 1 is the left or rear bearing.";
CM_ BO_ 2362572542 "Used for suspension control ...";
CM_ SG_ 2362572542 LevelPresetRearAxleRight "Set value for nominal level 'preset level' at the right side of the rear axle. This value is referred to 'Normal level 1'.  For ...";
CM_ SG_ 2362572542 LevelPresetRearAxleLeft "Set value for nominal level 'preset level' at the left side of the rear axle. This value is referred to 'Normal level 1'.  For ...";
CM_ SG_ 2362572542 LevelPresetFrontAxleRight "Set value for nominal level 'preset level' at the right side of the front axle. This value is referred to 'Normal level 1'.  For ...";
CM_ SG_ 2362572542 LevelPresetFrontAxleLeft "Set value for nominal level 'preset level' at the left side of the front axle. This value is referred to 'Normal level 1'.  For ...";
CM_ BO_ 2365478910 "Used for damper stiffness information ...";
CM_ SG_ 2365478910 ElctrncShckAbsrbrCtrlMdLft_TgAxl "Signal which indicates the current mode of operation of the electronic shock absorber control at the lift/tag axle.";
CM_ SG_ 2365478910 ElctrncShckAbsrbrCtrlMdeRearAxle "Signal which indicates the current mode of operation of the electronic shock absorber control at the rear axle.";
CM_ SG_ 2365478910 ElctrncShckAbsrbrCtrlMdFrontAxle "Signal which indicates the current mode of operation of the electronic shock absorber control at the front axle.";
CM_ SG_ 2365478910 DamperStiffnessLift_TagAxle "Damper stiffness information of the shock absorber control at the lift of tag axle ...";
CM_ SG_ 2365478910 DamperStiffnessRearAxle "Damper stiffness information of the shock absorber control at the rear axle ...";
CM_ SG_ 2365478910 DamperStiffnessFrontAxle "Damper stiffness information of the shock absorber control at the front axle ...";
CM_ BO_ 2560950014 "This message conveys the scaled test results for the applicable test requested in DM7.";
CM_ SG_ 2560950014 TestLimitMinimum "The test value must be greater than or equal to Test Limit Minimum in order for the test to pass";
CM_ SG_ 2560950014 TestLimitMaximum "The test value must be less than or equal to Test Limit Maximum in order for the test to pass.";
CM_ SG_ 2560950014 TestValue "The test value collected during the test.";
CM_ SG_ 2560950014 SlotId "The SLOT Identifer is used to determine the multiplier and offset to be used to scale the test value.";
CM_ SG_ 2560950014 TestIdentifier "Test Identifier";
CM_ SG_ 2560950014 FailureModeIdentifier1 "The FMI defines the type of failure detected in the subsystem identified by an SPN.";
CM_ SG_ 2560950014 SPN1High "SPN #1 (Conversion Version 4)";
CM_ SG_ 2560950014 SPN1 "SPN #1 (Conversion Version 4)";
CM_ BO_ 2566763262 "The purpose of this PGN is to group the aftertreatment intermediate gas temperature and pressure messages.";
CM_ SG_ 2566763262 Aftrtrtmnt1DslPrtcltFltrIntr3254 "Used to identify the applicable J1939-73 FMI detected in the diesel particulate filter intermediate gas temperature sensor ...";
CM_ SG_ 2566763262 Aftrtrtmnt1DslPrtcltFltrDltPrssP "Used to identify the applicable J1939-73 FMI detected in the diesel particulate filter differential pressure sensor by the ...";
CM_ SG_ 2566763262 Aftrtrtmnt1ExhstGsTmp2PrlmnryFMI "Used to identify the applicable J1939-73 FMI detected in the exhaust gas temperature 2 sensor by the manufacturer’s ...";
CM_ SG_ 2566763262 Aftrtrtmnt1DslPrtcltFltrDffPress "Exhaust differential pressure measured between the intake and exhaust of a diesel particulate filter in exhaust bank 1.";
CM_ SG_ 2566763262 Aftrtrtmnt1DslPrtcltFltrIntrmdtG "Temperature of engine combustion byproducts at a mid-point in the diesel particulate filter in exhaust bank 1.";
CM_ SG_ 2566763262 Aftertreatment1ExhaustGasTemp2 "The reading from the exhaust gas temperature sensor located midstream of the other two temperature sensors in the ...";
CM_ BO_ 2565869566 "The purpose of this PGN is to group the aftertreatment outlet sensor data for bank 1.  These values include the NOx, ...";
CM_ SG_ 2565869566 Aftrtrtmnt1OtltOxygnSnsrPrlmnryF "Used to identify the applicable J1939-73 FMI detected in the aftertreatment outlet oxygen sensor by the manufacturer’s ...";
CM_ SG_ 2565869566 NOxSensorATI1SelfdiagnosisStatus "Self-diagnosis result status for NOx sensor ATI1 (Aftertreatment Intake Bank 1) ...";
CM_ SG_ 2565869566 Aftrtrtmnt1OtltNOxSnsrPrlmnryFMI "Used to identify the applicable J1939-73 FMI detected in the aftertreatment outlet NOx sensor by the manufacturer’s ...";
CM_ SG_ 2565869566 Aftrtrtmnt1OtltGsSnsorHeaterCtrl "Indicates the heater status in the warm-up process.  Upon receiving a power-up command, the gas sensor ramps up ...";
CM_ SG_ 2565869566 Aftrtrtmnt1OtltGsSnsrHtrPrlmnryF "Used to identify the applicable J1939-73 FMI detected in the heater of the outlet exhaust gas sensor, either NOx or O2, by ...";
CM_ SG_ 2565869566 Aftrtrtmnt1OtltWdRngO2RdngStable "Indicates that the %O2 reading of the aftertreatment outlet gas sensor, either NOx or O2, is stable as determined by the ...";
CM_ SG_ 2565869566 Aftrtrtmnt1OtletNOxReadingStable "Indicates that the NOx reading of the aftertreatment outlet NOx sensor is stable as determined by the manufacturer’s ...";
CM_ SG_ 2565869566 Aftrtrtmnt1OutletGasSensorAtTemp "Indicates that the heater element of the aftertreatment outlet gas sensor, either NOx or O2, is within the manufacturer’s ...";
CM_ SG_ 2565869566 Aftrtrtmnt1OtltGsSnsrPowerStatus "Indicates that the power supplied to the aftertreatment outlet gas sensor, either NOx or O2, is within the manufacturer’s ...";
CM_ SG_ 2565869566 Aftertreatment1OutletO2 "The actual oxidation factor (%O2) of the gas within the exhaust stream.  For positive values, the parameter represents the ...";
CM_ SG_ 2565869566 Aftertreatment1OutletNOx "The amount of combined NO and NO2 in the exhaust exiting the aftertreatment system measured by a NOx sensor at the ...";
CM_ BO_ 2566763518 "The purpose of this PGN is to group the aftertreatment outlet gas temperature messages.";
CM_ SG_ 2566763518 Aftrtrtmnt1DslPrtcltFltrOtltExhs "Used to identify the applicable J1939-73 FMI detected in the diesel particulate filter outlet gas temperature sensor by the ...";
CM_ SG_ 2566763518 Aftrtrtmnt1ExhstGsTmp3PrlmnryFMI "Used to identify the applicable J1939-73 FMI detected in the exhaust gas temperature 3 sensor by the manufacturer’s ...";
CM_ SG_ 2566763518 Aftrtrtmnt1DslPrtcltFltrOtltGsTm "Temperature of engine combustion byproducts leaving the diesel particulate filter exhaust in exhaust bank 1.";
CM_ SG_ 2566763518 Aftertreatment1ExhaustGasTemp3 "The reading from the exhaust gas temperature sensor located farthest downstream in the aftertreatment system in ...";
CM_ BO_ 2566749182 "This PGN contains information about the aftertreatment 1 (diesel particulate filter 1 soot and ash load).";
CM_ SG_ 2566749182 Aftrtrtmnt1DslPrtcltFltrStLdRgnr "This parameter indicates the value that will first cause DPF regeneration in aftertreatment 1. There may be multiple ...";
CM_ SG_ 2566749182 DslPrtcltFltr1TmSncLstActvRgnrtn "Indicates the time since the last active regeneration event of diesel particulate filter 1.";
CM_ SG_ 2566749182 DslPrtclateFilter1AshLoadPercent "Indicates the ash load percent of diesel particulate filter 1.  100% is the level at which diesel particulate filter ash service ...";
CM_ SG_ 2566749182 DslPrtclteFilter1SootLoadPercent "Indicates the soot load percent of diesel particulate filter 1.  100% is the level at which active diesel particulate filter ...";
CM_ BO_ 2566748670 "This PGN contains trip total information about the aftertreatment 1.";
CM_ SG_ 2566748670 Aftrtrtmnt1DslPrtcltFltrTrpN3740 "Total number of aftertreatment 1 diesel particulate filter active regeneration manual requests by the operator during the ...";
CM_ SG_ 2566748670 Aftrtrtmnt1DslPrtcltFltrTrpN3739 "Total number of aftertreatment 1 diesel particulate filter active regeneration inhibit requests by the operator during the ...";
CM_ SG_ 2566748670 Aftrtrtmnt1DslPrtcltFltrTrpN3738 "Total number of passive regenerations of the aftertreatment 1 diesel particulate filter during the current trip period.";
CM_ SG_ 2566748670 Aftrtrtmnt1DslPrtcltFltrTrpPssvR "Total amount of time that the aftertreatment 1 diesel particulate filter has been in passive regeneration during the current ...";
CM_ SG_ 2566748670 Aftrtrtmnt1DslPrtcltFltrTrpNmbrO "Total number of active regenerations of the aftertreatment 1 diesel particulate filter during the current trip period.";
CM_ SG_ 2566748670 Aftrtrtmnt1DslPrtcltFltrTrpDsbld "Total amount of time that aftertreatment 1 diesel particulate filter regeneration has been manually disabled during the ...";
CM_ SG_ 2566748670 Aftrtrtmnt1DslPrtcltFltrTrpActvR "Total amount of time that the aftertreatment 1 diesel particulate filter has been in active regeneration during the current ...";
CM_ SG_ 2566748670 Aftrtrtmnt1DslPrtcltFltrTrpFlUsd "Total amount of fuel used by the aftertreatment 1 diesel particulate filter during the current trip period.";
CM_ BO_ 2566758142 "Contains information about the aftertreatment 2 air system ...";
CM_ SG_ 2566758142 Aftertreatment2AirEnableActuator "Indicates whether aftertreatment 2 air enable actuator is on or off ...";
CM_ SG_ 2566758142 Aftertreatment2PurgeAirActuator "Indicates whether aftertreatment 2 purge air actuator is on or off ...";
CM_ SG_ 2566758142 Aftrtrtmnt2AtmizationAirActuator "Indicates whether aftertreatment 2 atomization air actuator is on or off ...";
CM_ SG_ 2566758142 Aftertreatment2AirSystemRelay "Indicates whether aftertreatment 2 air system relay is on or off ...";
CM_ SG_ 2566758142 Aftrtratment2AirPressActuatorPos "Position of the aftertreatment 2 air pressure actuator as measured by a position feedback sensor.";
CM_ SG_ 2566758142 Aftertreatment2AirPressCtrl "Position that the controller is commanding the aftertreatment 2 air pressure control to maintain.  0% = fully closed, 100% = ...";
CM_ SG_ 2566758142 Aftertreatment2PurgeAirPress "Pressure of the purge air supply for aftertreatment 2 ...";
CM_ SG_ 2566758142 Aftertreatment2SupplyAirPress "Pressure of the supply air for aftertreatment 2.  Supply air is the air supplied from a pneumatic line for an air-assisted or ...";
CM_ BO_ 2566745342 "This PGN contains information about the Aftertreatment 2 Air Control.";
CM_ SG_ 2566745342 Aftertreatment2SecondAirPress "Pressure of the secondary air for aftertreatment 2.  Secondary air is air provided to the exhaust system (per SAE J2403).";
CM_ SG_ 2566745342 Aftertreatment2SecondAirMassFlow "Indicates the secondary air mass flow for aftertreatment 2.  Secondary air is the air provided to the exhaust system (per ...";
CM_ SG_ 2566745342 Aftertreatment2SecondAirTemp "Indicates the secondary air temperature for aftertreatment 2.  Secondary air is air provided to the exhaust system (per ...";
CM_ SG_ 2566745342 Aftrtreatment2SecondAirDiffPress "Indicates the secondary air differential pressure for aftertreatment 2.  Secondary air is air provided to the exhaust system ...";
CM_ BO_ 2566758654 "Contains information about the aftertreatment 2 fuel system ...";
CM_ SG_ 2566758654 Aftrtrtmnt2FlInjector1HeaterCtrl "Heating level that the controller is commanding the aftertreatment 2 fuel injector 1 heater control to maintain. 0% = off, ...";
CM_ SG_ 2566758654 Aftrtreatment2FuelEnableActuator "Indicates whether aftertreatment 2 fuel enable actuator is on or off ...";
CM_ SG_ 2566758654 Aftrtreatment2RegenerationStatus "Indicates whether regeneration is active or inactive in aftertreatment 2.";
CM_ SG_ 2566758654 Aftertreatment2Ignt "Indicates whether aftertreatment 2 ignition circuit is energized by the ECM.";
CM_ SG_ 2566758654 Aftertreatment2FuelDrainActuator "Indicates whether aftertreatment 2 fuel drain actuator is on or off ...";
CM_ SG_ 2566758654 Aftertreatment2FuelPress1Ctrl "Position that the controller is commanding the aftertreatment 2 fuel pressure control to maintain.  0% = fully closed, 100% ...";
CM_ SG_ 2566758654 Aftertreatment2FuelRate "Rate of fuel being delivered to aftertreatment 2 for regeneration ...";
CM_ SG_ 2566758654 Aftertreatment2FuelPress1 "Pressure of the fuel for Aftertreatment 2.";
CM_ BO_ 2566753278 "Diesel particulate filter gas parameters for system or bank 2 ...";
CM_ SG_ 2566753278 DslParticulateFilterOutletPress2 "This parameter indicates the diesel particulate filter outlet gage pressure 2 (bank 2).";
CM_ SG_ 2566753278 DslParticulateFilterIntakePress2 "This parameter indicates the diesel particulate filter intake gage pressure 2 (bank 2).";
CM_ BO_ 2566756862 "Contains information about the history of the aftertreatment 2 system ...";
CM_ SG_ 2566756862 Aftrtrtmnt2AvrgDstncBtwnActvDPFR "Indicates the average distance since last reset between active regenerations, that have not been forced to occur by ...";
CM_ SG_ 2566756862 Aftrtrtmnt2AvrgTmBtwnActvRgnrtns "Indicates the average time since last reset between active regenerations, that have not been forced to occur by manual ...";
CM_ SG_ 2566756862 Aftrtrtmnt2DslPrtcltFltrTtlN3732 "Total number of Aftertreatment device 2 active regeneration manual requests by the operator over the lifetime of the ...";
CM_ SG_ 2566756862 Aftrtrtmnt2DslPrtcltFltrTtlN3731 "Total number of Aftertreatment device 2 active regeneration inhibit requests by the operator over the lifetime of the ...";
CM_ SG_ 2566756862 Aftrtrtmnt2DslPrtcltFltrTtlNmbrO "Total number of passive regenerations by Aftertreatment device 2 over the lifetime of the device.";
CM_ SG_ 2566756862 Aftrtrtmnt2DslPrtcltFltrTtlPssvR "Total amount of time that Aftertreatment device 2 has been in passive regeneration over the lifetime of the device.";
CM_ SG_ 2566756862 Aftrtrtmnt2TtlNmbrOfActvRgnrtons "Total number of active regenerations by aftertreatment device 2 over the lifetime of the device.";
CM_ SG_ 2566756862 Aftertreatment2TotalDisabledTime "Total amount of time that aftertreatment 2 regeneration has been manually disabled.";
CM_ SG_ 2566756862 Aftrtrtmnt2TotalRegenerationTime "Total amount of time that aftertreatment device 2 has been regenerating over the lifetime of the device.";
CM_ SG_ 2566756862 Aftertreatment2TotalFuelUsed "Total amount of fuel used by aftertreatment device 2 over the lifetime of the device.";
BA_DEF_ SG_  "SigType" ENUM  "Default","Range","RangeSigned","ASCII","Discrete","Control","ReferencePGN","DTC","StringDelimiter","StringLength","StringLengthControl";
BA_DEF_ SG_  "GenSigStartValue" INT 0 10000;
BA_DEF_ SG_  "GenSigSendType" ENUM  "Cyclic","OnWrite","OnWriteWithRepetition","OnChange","OnChangeWithRepetition","IfActive","IfActiveWithRepetition","NoSigSendType";
BA_DEF_ SG_  "GenSigILSupport" ENUM  "No","Yes";
BA_DEF_ SG_  "GenSigEVName" STRING ;
BA_DEF_ SG_  "SPN" INT 0 524287;
BA_DEF_ BO_  "GenMsgStartDelayTime" INT 0 100000;
BA_DEF_ BO_  "GenMsgILSupport" ENUM  "No","Yes";
BA_DEF_ BO_  "GenMsgRequestable" INT 0 1;
BA_DEF_ BO_  "GenMsgSendType" ENUM  "cyclic","NotUsed","NotUsed","NotUsed","NotUsed","NotUsed","NotUsed","IfActive","noMsgSendType";
BA_DEF_ BO_  "VFrameFormat" ENUM  "StandardCAN","ExtendedCAN","reserved","J1939PG";
BA_DEF_ BO_  "GenMsgCycleTime" INT 0 3600000;
BA_DEF_ SG_  "SystemSignalLongSymbol" STRING ;
BA_DEF_DEF_  "SigType" "Default";
BA_DEF_DEF_  "GenSigStartValue" 0;
BA_DEF_DEF_  "GenSigSendType" "NoSigSendType";
BA_DEF_DEF_  "GenSigILSupport" "Yes";
BA_DEF_DEF_  "GenSigEVName" "Env@Nodename_@Signame";
BA_DEF_DEF_  "SPN" 0;
BA_DEF_DEF_  "GenMsgStartDelayTime" 0;
BA_DEF_DEF_  "GenMsgILSupport" "Yes";
BA_DEF_DEF_  "GenMsgRequestable" 1;
BA_DEF_DEF_  "GenMsgSendType" "noMsgSendType";
BA_DEF_DEF_  "VFrameFormat" "J1939PG";
BA_DEF_DEF_  "GenMsgCycleTime" 0;
BA_DEF_DEF_  "SystemSignalLongSymbol" "";
BA_ "GenMsgSendType" BO_ 2566711806 0;
BA_ "GenMsgCycleTime" BO_ 2566711806 100;
BA_ "GenMsgSendType" BO_ 2364549886 0;
BA_ "GenMsgCycleTime" BO_ 2364549886 10;
BA_ "GenMsgSendType" BO_ 2566712318 0;
BA_ "GenMsgCycleTime" BO_ 2566712318 1000;
BA_ "GenMsgSendType" BO_ 2566712574 0;
BA_ "GenMsgCycleTime" BO_ 2566712574 1000;
BA_ "GenMsgSendType" BO_ 2566731006 0;
BA_ "GenMsgCycleTime" BO_ 2566731006 1000;
BA_ "GenMsgSendType" BO_ 2566731262 0;
BA_ "GenMsgCycleTime" BO_ 2566731262 1000;
BA_ "GenMsgSendType" BO_ 2566730750 0;
BA_ "GenMsgCycleTime" BO_ 2566730750 1000;
BA_ "GenMsgSendType" BO_ 2566731518 0;
BA_ "GenMsgCycleTime" BO_ 2566731518 1000;
BA_ "GenMsgSendType" BO_ 2566732030 0;
BA_ "GenMsgCycleTime" BO_ 2566732030 500;
BA_ "GenMsgSendType" BO_ 2566732286 0;
BA_ "GenMsgCycleTime" BO_ 2566732286 500;
BA_ "GenMsgSendType" BO_ 2164079358 0;
BA_ "GenMsgCycleTime" BO_ 2164079358 500;
BA_ "GenMsgSendType" BO_ 2364549118 0;
BA_ "GenMsgCycleTime" BO_ 2364549118 50;
BA_ "GenMsgSendType" BO_ 2566732798 0;
BA_ "GenMsgCycleTime" BO_ 2566732798 500;
BA_ "GenMsgSendType" BO_ 2364548862 0;
BA_ "GenMsgCycleTime" BO_ 2364548862 50;
BA_ "GenMsgSendType" BO_ 2364549374 0;
BA_ "GenMsgCycleTime" BO_ 2364549374 50;
BA_ "GenMsgSendType" BO_ 2566726142 0;
BA_ "GenMsgCycleTime" BO_ 2566726142 500;
BA_ "GenMsgSendType" BO_ 2566725630 0;
BA_ "GenMsgCycleTime" BO_ 2566725630 500;
BA_ "GenMsgSendType" BO_ 2566733310 0;
BA_ "GenMsgCycleTime" BO_ 2566733310 1000;
BA_ "GenMsgSendType" BO_ 2566733054 0;
BA_ "GenMsgCycleTime" BO_ 2566733054 1000;
BA_ "GenMsgSendType" BO_ 2499624702 0;
BA_ "GenMsgCycleTime" BO_ 2499624702 500;
BA_ "GenMsgSendType" BO_ 2566733822 0;
BA_ "GenMsgCycleTime" BO_ 2566733822 500;
BA_ "GenMsgSendType" BO_ 2566734078 0;
BA_ "GenMsgCycleTime" BO_ 2566734078 500;
BA_ "GenMsgSendType" BO_ 2364548350 0;
BA_ "GenMsgCycleTime" BO_ 2364548350 50;
BA_ "GenMsgSendType" BO_ 2566734334 0;
BA_ "GenMsgCycleTime" BO_ 2566734334 500;
BA_ "GenMsgSendType" BO_ 2364548094 0;
BA_ "GenMsgCycleTime" BO_ 2364548094 50;
BA_ "GenMsgSendType" BO_ 2364548606 0;
BA_ "GenMsgCycleTime" BO_ 2364548606 50;
BA_ "GenMsgSendType" BO_ 2566726398 0;
BA_ "GenMsgCycleTime" BO_ 2566726398 500;
BA_ "GenMsgSendType" BO_ 2566809342 0;
BA_ "GenMsgCycleTime" BO_ 2566809342 1000;
BA_ "GenMsgSendType" BO_ 2365446910 0;
BA_ "GenMsgCycleTime" BO_ 2365446910 100;
BA_ "GenMsgSendType" BO_ 2365446398 0;
BA_ "GenMsgCycleTime" BO_ 2365446398 100;
BA_ "GenMsgSendType" BO_ 2365445886 0;
BA_ "GenMsgCycleTime" BO_ 2365445886 100;
BA_ "GenMsgSendType" BO_ 2566847230 0;
BA_ "GenMsgCycleTime" BO_ 2566847230 1000;
BA_ "GenMsgSendType" BO_ 2566848254 0;
BA_ "GenMsgCycleTime" BO_ 2566848254 1000;
BA_ "GenMsgSendType" BO_ 2566725886 0;
BA_ "GenMsgCycleTime" BO_ 2566725886 500;
BA_ "GenMsgSendType" BO_ 2432520958 0;
BA_ "GenMsgCycleTime" BO_ 2432520958 1000;
BA_ "GenMsgSendType" BO_ 2560425726 0;
BA_ "GenMsgCycleTime" BO_ 2560425726 100;
BA_ "GenMsgSendType" BO_ 2560491262 0;
BA_ "GenMsgCycleTime" BO_ 2560491262 100;
BA_ "GenMsgSendType" BO_ 2349399806 0;
BA_ "GenMsgCycleTime" BO_ 2349399806 20;
BA_ "GenMsgSendType" BO_ 2566758398 0;
BA_ "GenMsgCycleTime" BO_ 2566758398 500;
BA_ "GenMsgSendType" BO_ 2566745598 0;
BA_ "GenMsgCycleTime" BO_ 2566745598 500;
BA_ "GenMsgSendType" BO_ 2566758910 0;
BA_ "GenMsgCycleTime" BO_ 2566758910 500;
BA_ "GenMsgSendType" BO_ 2566743550 0;
BA_ "GenMsgCycleTime" BO_ 2566743550 500;
BA_ "GenMsgSendType" BO_ 2566753534 0;
BA_ "GenMsgCycleTime" BO_ 2566753534 500;
BA_ "GenMsgSendType" BO_ 2565869310 0;
BA_ "GenMsgCycleTime" BO_ 2565869310 50;
BA_ "GenMsgSendType" BO_ 2566763774 0;
BA_ "GenMsgCycleTime" BO_ 2566763774 500;
BA_ "GenMsgSendType" BO_ 2633934846 0;
BA_ "GenMsgCycleTime" BO_ 2633934846 1000;
BA_ "GenMsgSendType" BO_ 2362572542 2;
BA_ "GenMsgCycleTime" BO_ 2362572542 100;
BA_ "GenMsgSendType" BO_ 2365478910 0;
BA_ "GenMsgCycleTime" BO_ 2365478910 100;
BA_ "GenMsgSendType" BO_ 2566763262 0;
BA_ "GenMsgCycleTime" BO_ 2566763262 500;
BA_ "GenMsgSendType" BO_ 2565869566 0;
BA_ "GenMsgCycleTime" BO_ 2565869566 50;
BA_ "GenMsgSendType" BO_ 2566763518 0;
BA_ "GenMsgCycleTime" BO_ 2566763518 500;
BA_ "GenMsgSendType" BO_ 2566758142 0;
BA_ "GenMsgCycleTime" BO_ 2566758142 500;
BA_ "GenMsgSendType" BO_ 2566745342 0;
BA_ "GenMsgCycleTime" BO_ 2566745342 500;
BA_ "GenMsgSendType" BO_ 2566758654 0;
BA_ "GenMsgCycleTime" BO_ 2566758654 500;
BA_ "GenMsgSendType" BO_ 2566753278 0;
BA_ "GenMsgCycleTime" BO_ 2566753278 500;
BA_ "SigType" SG_ 2566711806 Armrest2Switch2 5;
BA_ "SPN" SG_ 2566711806 Armrest2Switch2 5494;
BA_ "SigType" SG_ 2566711806 Armrest2Switch1 5;
BA_ "SPN" SG_ 2566711806 Armrest2Switch1 5493;
BA_ "SigType" SG_ 2566711806 Armrest1Switch2 5;
BA_ "SPN" SG_ 2566711806 Armrest1Switch2 5492;
BA_ "SigType" SG_ 2566711806 Armrest1Switch1 5;
BA_ "SPN" SG_ 2566711806 Armrest1Switch1 1503;
BA_ "SigType" SG_ 2364549886 AngularRateMeasurementLatency 1;
BA_ "SPN" SG_ 2364549886 AngularRateMeasurementLatency 4989;
BA_ "SigType" SG_ 2364549886 YawRateExRangeFigureOfMerit 5;
BA_ "SPN" SG_ 2364549886 YawRateExRangeFigureOfMerit 4988;
BA_ "SigType" SG_ 2364549886 RollRateExRangeFigureOfMerit 5;
BA_ "SPN" SG_ 2364549886 RollRateExRangeFigureOfMerit 4987;
BA_ "SigType" SG_ 2364549886 PitchRateExRangeFigureOfMerit 5;
BA_ "SPN" SG_ 2364549886 PitchRateExRangeFigureOfMerit 4986;
BA_ "SigType" SG_ 2364549886 YawRateExRange 1;
BA_ "SPN" SG_ 2364549886 YawRateExRange 4985;
BA_ "SigType" SG_ 2364549886 RollRateExRange 1;
BA_ "SPN" SG_ 2364549886 RollRateExRange 4984;
BA_ "SigType" SG_ 2364549886 PitchRateExRange 1;
BA_ "SPN" SG_ 2364549886 PitchRateExRange 4983;
BA_ "SigType" SG_ 2566712318 Aftrtrtmnt2NOxAdsrbrDSOxRgnrtnSt 5;
BA_ "SPN" SG_ 2566712318 Aftrtrtmnt2NOxAdsrbrDSOxRgnrtnSt 5462;
BA_ "SigType" SG_ 2566712318 Aftrtrtmnt2NOxAdsrbrDNOxRgnrtnSt 5;
BA_ "SPN" SG_ 2566712318 Aftrtrtmnt2NOxAdsrbrDNOxRgnrtnSt 5460;
BA_ "SigType" SG_ 2566712574 Aftrtrtmnt1NOxAdsrbrDSOxRgnrtnSt 5;
BA_ "SPN" SG_ 2566712574 Aftrtrtmnt1NOxAdsrbrDSOxRgnrtnSt 5461;
BA_ "SigType" SG_ 2566712574 Aftrtrtmnt1NOxAdsrbrDNOxRgnrtnSt 5;
BA_ "SPN" SG_ 2566712574 Aftrtrtmnt1NOxAdsrbrDNOxRgnrtnSt 5459;
BA_ "SigType" SG_ 2164078590 Aftrtrtmnt2SCRCnvrsionEfficiency 1;
BA_ "SPN" SG_ 2164078590 Aftrtrtmnt2SCRCnvrsionEfficiency 4419;
BA_ "SPN" SG_ 2164078590 Aftrtrtmnt2SCRCmmnddCtlystDslExh 4418;
BA_ "SigType" SG_ 2164078590 Aftrtrtmnt2DslExhstFldAvrgCnsmpt 1;
BA_ "SPN" SG_ 2164078590 Aftrtrtmnt2DslExhstFldAvrgCnsmpt 4417;
BA_ "SPN" SG_ 2566731006 Aftrtrtmnt2DslExhstFldTnk2HtrPrl 4439;
BA_ "SPN" SG_ 2566731006 Aftrtrtmnt2DslExhstFldTnk2Heater 4438;
BA_ "SPN" SG_ 2566731006 Aftrtrtmnt2DslExhstFldTnk2TmpPrl 4437;
BA_ "SPN" SG_ 2566731006 Aftrtrtmnt2DslExhstFldTnk2LvlPrl 4436;
BA_ "SPN" SG_ 2566731006 Aftrtrtmnt2DslExhstFldTnk2Level2 4435;
BA_ "SigType" SG_ 2566731006 Aftrtrtmnt2DslExhstFlidTank2Temp 1;
BA_ "SPN" SG_ 2566731006 Aftrtrtmnt2DslExhstFlidTank2Temp 4434;
BA_ "SigType" SG_ 2566731006 Aftrtrtmnt2DslExhstFldTank2Level 1;
BA_ "SPN" SG_ 2566731006 Aftrtrtmnt2DslExhstFldTank2Level 4433;
BA_ "SPN" SG_ 2566731262 Aftrtrtmnt2DslExhstFldTnk1HtrPrl 4432;
BA_ "SigType" SG_ 2566731262 Aftrtrtmnt2DslExhstFldTankHeater 1;
BA_ "SPN" SG_ 2566731262 Aftrtrtmnt2DslExhstFldTankHeater 4431;
BA_ "SPN" SG_ 2566731262 Aftrtrtmnt2DslExhstFldTnk1TmpPrl 4430;
BA_ "SPN" SG_ 2566731262 Aftrtrtmnt2DslExhstFldTnkLvlPrlm 4429;
BA_ "SigType" SG_ 2566731262 Aftrtrtmnt2DslExhstFldTankLevel2 1;
BA_ "SPN" SG_ 2566731262 Aftrtrtmnt2DslExhstFldTankLevel2 4428;
BA_ "SigType" SG_ 2566731262 Aftrtrtmnt2DslExhstFluidTankTemp 1;
BA_ "SPN" SG_ 2566731262 Aftrtrtmnt2DslExhstFluidTankTemp 4427;
BA_ "SigType" SG_ 2566731262 Aftrtrtmnt2DslExhstFlidTankLevel 1;
BA_ "SPN" SG_ 2566731262 Aftrtrtmnt2DslExhstFlidTankLevel 4426;
BA_ "SPN" SG_ 2566730750 Aftrtrtmnt2DslExhstFldTnkDrnVlvC 5439;
BA_ "SigType" SG_ 2566730750 Aftrtrtmnt2DslExhstFlidPumpState 5;
BA_ "SPN" SG_ 2566730750 Aftrtrtmnt2DslExhstFlidPumpState 5438;
BA_ "SPN" SG_ 2566730750 Aftrtrtmnt2DslExhstFldTnkFllVlvC 5437;
BA_ "SPN" SG_ 2566730750 Aftrtrtmnt2DslExhstFldRturnValve 4442;
BA_ "SPN" SG_ 2566730750 Aftrtrtmnt2DslExhstFldPmpDrvPrcn 4441;
BA_ "SigType" SG_ 2566730750 Aftrtrtmnt2DslExhstFldPmpMtrSped 1;
BA_ "SPN" SG_ 2566730750 Aftrtrtmnt2DslExhstFldPmpMtrSped 4440;
BA_ "SPN" SG_ 2566731518 Aftrtrtmnt2DeselExhaustFluidType 4425;
BA_ "SPN" SG_ 2566731518 Aftrtrtmnt2DslExhstFldPrprtsPrlm 4424;
BA_ "SPN" SG_ 2566731518 Aftrtrtmnt2DslExhstFldTmp2Prlmnr 4423;
BA_ "SigType" SG_ 2566731518 Aftrtrtmnt2DslExhstFldCndctivity 1;
BA_ "SPN" SG_ 2566731518 Aftrtrtmnt2DslExhstFldCndctivity 4422;
BA_ "SigType" SG_ 2566731518 Aftrtrtmnt2DslExhstFldCncntrtion 1;
BA_ "SPN" SG_ 2566731518 Aftrtrtmnt2DslExhstFldCncntrtion 4421;
BA_ "SigType" SG_ 2566731518 Aftrtrtmnt2DselExhaustFluidTemp2 1;
BA_ "SPN" SG_ 2566731518 Aftrtrtmnt2DselExhaustFluidTemp2 4420;
BA_ "SPN" SG_ 2566732030 Aftrtrtmnt2SCRCtlystOtltGsTmpPrl 4416;
BA_ "SigType" SG_ 2566732030 Aftrtrtmnt2SCRCtlystOtletGasTemp 1;
BA_ "SPN" SG_ 2566732030 Aftrtrtmnt2SCRCtlystOtletGasTemp 4415;
BA_ "SPN" SG_ 2566732030 Aftrtrtmnt2SCRCtlystIntkGsTmpPrl 4414;
BA_ "SigType" SG_ 2566732030 Aftrtrtmnt2SCRCtlystIntkeGasTemp 1;
BA_ "SPN" SG_ 2566732030 Aftrtrtmnt2SCRCtlystIntkeGasTemp 4413;
BA_ "SPN" SG_ 2566732286 Aftrtrtmnt2SCRExhstGsDffPrssPrlm 4412;
BA_ "SigType" SG_ 2566732286 Aftrtrtmnt2SCRExhustGasDiffPress 1;
BA_ "SPN" SG_ 2566732286 Aftrtrtmnt2SCRExhustGasDiffPress 4411;
BA_ "SPN" SG_ 2164079358 Aftrtrtmnt2DslExhstFldTnk2HtrCmd 5415;
BA_ "SPN" SG_ 2164079358 Aftrtrtmnt2DslExhstFldTnkHterCmd 5138;
BA_ "SigType" SG_ 2164079358 Aftrtrtmnt2DslExhstFldLneHeater4 5;
BA_ "SPN" SG_ 2164079358 Aftrtrtmnt2DslExhstFldLneHeater4 4410;
BA_ "SigType" SG_ 2164079358 Aftrtrtmnt2DslExhstFldLneHeater3 5;
BA_ "SPN" SG_ 2164079358 Aftrtrtmnt2DslExhstFldLneHeater3 4409;
BA_ "SigType" SG_ 2164079358 Aftrtrtmnt2DslExhstFldLneHeater2 5;
BA_ "SPN" SG_ 2164079358 Aftrtrtmnt2DslExhstFldLneHeater2 4408;
BA_ "SigType" SG_ 2164079358 Aftrtrtmnt2DslExhstFldLneHeater1 5;
BA_ "SPN" SG_ 2164079358 Aftrtrtmnt2DslExhstFldLneHeater1 4407;
BA_ "SPN" SG_ 2164079358 Aftrtrtmnt2DslExhstFldDsrHtngMdR 4406;
BA_ "SigType" SG_ 2164079358 Aftrtrtmnt2DslExhstFldDsrFltSppr 5;
BA_ "SPN" SG_ 2164079358 Aftrtrtmnt2DslExhstFldDsrFltSppr 4405;
BA_ "SigType" SG_ 2364549118 Aftrtrtmnt2DslExhstFldRqstdQntty 1;
BA_ "SPN" SG_ 2364549118 Aftrtrtmnt2DslExhstFldRqstdQntty 4403;
BA_ "SPN" SG_ 2364549118 Aftrtrtmnt2SCRSystmRquestedState 4402;
BA_ "SigType" SG_ 2364549118 Aftrtrtmnt2DslExhstFldDsngRqstdQ 1;
BA_ "SPN" SG_ 2364549118 Aftrtrtmnt2DslExhstFldDsngRqstdQ 4401;
BA_ "SPN" SG_ 2566732798 Aftrtrtmnt2DslExhstFldLnHtr4Prlm 4400;
BA_ "SigType" SG_ 2566732798 Aftrtrtmnt2DslExhstFldLnHtr4Stte 5;
BA_ "SPN" SG_ 2566732798 Aftrtrtmnt2DslExhstFldLnHtr4Stte 4399;
BA_ "SPN" SG_ 2566732798 Aftrtrtmnt2DslExhstFldLnHtr3Prlm 4398;
BA_ "SigType" SG_ 2566732798 Aftrtrtmnt2DslExhstFldLnHtr3Stte 5;
BA_ "SPN" SG_ 2566732798 Aftrtrtmnt2DslExhstFldLnHtr3Stte 4397;
BA_ "SPN" SG_ 2566732798 Aftrtrtmnt2DslExhstFldLnHtr2Prlm 4396;
BA_ "SigType" SG_ 2566732798 Aftrtrtmnt2DslExhstFldLnHtr2Stte 5;
BA_ "SPN" SG_ 2566732798 Aftrtrtmnt2DslExhstFldLnHtr2Stte 4395;
BA_ "SPN" SG_ 2566732798 Aftrtrtmnt2DslExhstFldLnHtr1Prlm 4394;
BA_ "SigType" SG_ 2566732798 Aftrtrtmnt2DslExhstFldLnHtr1Stte 5;
BA_ "SPN" SG_ 2566732798 Aftrtrtmnt2DslExhstFldLnHtr1Stte 4393;
BA_ "SPN" SG_ 2566732798 Aftrtrtmnt2SCRFeedbackCtrlStatus 4392;
BA_ "SPN" SG_ 2566732798 Aftrtrtmnt2SCRDsngVlvExhstTmpRdc 4391;
BA_ "SigType" SG_ 2566732798 Aftrtrtmnt2DslExhstFldDosingTemp 1;
BA_ "SPN" SG_ 2566732798 Aftrtrtmnt2DslExhstFldDosingTemp 4390;
BA_ "SPN" SG_ 2566732798 Aftrtrtmnt2SCRDsngAirAssistValve 4389;
BA_ "SigType" SG_ 2566732798 Aftrtrtmnt2SCRDsngArAssstAbsPrss 1;
BA_ "SPN" SG_ 2566732798 Aftrtrtmnt2SCRDsngArAssstAbsPrss 4388;
BA_ "SigType" SG_ 2364548862 Aftrtrtmnt2DslExhstFldDsngAbsPrs 1;
BA_ "SPN" SG_ 2364548862 Aftrtrtmnt2DslExhstFldDsngAbsPrs 4387;
BA_ "SigType" SG_ 2364548862 Aftrtrtmnt2DslExhstFldActlQnttyO 1;
BA_ "SPN" SG_ 2364548862 Aftrtrtmnt2DslExhstFldActlQnttyO 4386;
BA_ "SPN" SG_ 2364548862 Aftertreatment2SCRSystemState 4385;
BA_ "SigType" SG_ 2364548862 Aftrtrtmnt2DslExhstFldActlDsngQn 1;
BA_ "SPN" SG_ 2364548862 Aftrtrtmnt2DslExhstFldActlDsngQn 4384;
BA_ "SigType" SG_ 2364549374 Aftrtrtmnt2OtltNH3GsSnsrHterCtrl 5;
BA_ "SPN" SG_ 2364549374 Aftrtrtmnt2OtltNH3GsSnsrHterCtrl 4449;
BA_ "SPN" SG_ 2364549374 Aftrtrtmnt2OtltNH3GsSnsrHtrPrlmn 4448;
BA_ "SigType" SG_ 2364549374 Aftrtrtmnt2OtltNH3GsSensorAtTemp 5;
BA_ "SPN" SG_ 2364549374 Aftrtrtmnt2OtltNH3GsSensorAtTemp 4447;
BA_ "SigType" SG_ 2364549374 Aftrtrtmnt2OtltNH3GsSnsrPwrInRng 5;
BA_ "SPN" SG_ 2364549374 Aftrtrtmnt2OtltNH3GsSnsrPwrInRng 4446;
BA_ "SigType" SG_ 2364549374 Aftrtrtmnt2OtletNH3ReadingStable 5;
BA_ "SPN" SG_ 2364549374 Aftrtrtmnt2OtletNH3ReadingStable 4445;
BA_ "SPN" SG_ 2364549374 Aftrtrtmnt2OtltNH3SnsrPrlmnryFMI 4444;
BA_ "SigType" SG_ 2364549374 Aftertreatment2OutletNH3 1;
BA_ "SPN" SG_ 2364549374 Aftertreatment2OutletNH3 4443;
BA_ "SPN" SG_ 2566726142 Aftrtrtmnt2GsOxdtnCtlystDffPrssP 4764;
BA_ "SPN" SG_ 2566726142 Aftrtrtmnt2GsOxdtnCtlystOtlt4763 4763;
BA_ "SPN" SG_ 2566726142 Aftrtrtmnt2GsOxdtnCtlystIntk4762 4762;
BA_ "SigType" SG_ 2566726142 Aftrtrtmnt2GsOxdtnCtlystDffPress 1;
BA_ "SPN" SG_ 2566726142 Aftrtrtmnt2GsOxdtnCtlystDffPress 4761;
BA_ "SigType" SG_ 2566726142 Aftrtrtmnt2GsOxdtnCtlystOtltGsTm 1;
BA_ "SPN" SG_ 2566726142 Aftrtrtmnt2GsOxdtnCtlystOtltGsTm 4760;
BA_ "SigType" SG_ 2566726142 Aftrtrtmnt2GsOxdtnCtlystIntkGsTm 1;
BA_ "SPN" SG_ 2566726142 Aftrtrtmnt2GsOxdtnCtlystIntkGsTm 4759;
BA_ "SPN" SG_ 2566725630 Aftrtrtmnt2DslOxdtnCtlystDff4776 4776;
BA_ "SPN" SG_ 2566725630 Aftrtrtmnt2DslOxdtnCtlystOtl4775 4775;
BA_ "SPN" SG_ 2566725630 Aftrtrtmnt2DslOxdtnCtlystInt4774 4774;
BA_ "SigType" SG_ 2566725630 Aftrtrtmnt2DslOxdtnCtlystDffPrss 1;
BA_ "SPN" SG_ 2566725630 Aftrtrtmnt2DslOxdtnCtlystDffPrss 4773;
BA_ "SigType" SG_ 2566725630 Aftrtrtmnt2DslOxdtnCtlystOtltGsT 1;
BA_ "SPN" SG_ 2566725630 Aftrtrtmnt2DslOxdtnCtlystOtltGsT 4772;
BA_ "SigType" SG_ 2566725630 Aftrtrtmnt2DslOxdtnCtlystIntkGsT 1;
BA_ "SPN" SG_ 2566725630 Aftrtrtmnt2DslOxdtnCtlystIntkGsT 4771;
BA_ "SPN" SG_ 2566733310 Aftrtrtmnt1DslExhstFldTnk2HtrPrl 4373;
BA_ "SigType" SG_ 2566733310 Aftrtrtmnt1DslExhstFldTnk2Heater 1;
BA_ "SPN" SG_ 2566733310 Aftrtrtmnt1DslExhstFldTnk2Heater 4372;
BA_ "SPN" SG_ 2566733310 Aftrtrtmnt1DslExhstFldTnk2TmpPrl 4371;
BA_ "SPN" SG_ 2566733310 Aftrtrtmnt1DslExhstFldTnk2LvlPrl 4370;
BA_ "SPN" SG_ 2566733310 Aftrtrtmnt1DslExhstFldTnk2Level2 4369;
BA_ "SigType" SG_ 2566733310 Aftrtrtmnt1DslExhstFlidTank2Temp 1;
BA_ "SPN" SG_ 2566733310 Aftrtrtmnt1DslExhstFlidTank2Temp 4368;
BA_ "SigType" SG_ 2566733310 Aftrtrtmnt1DslExhstFldTank2Level 1;
BA_ "SPN" SG_ 2566733310 Aftrtrtmnt1DslExhstFldTank2Level 4367;
BA_ "SPN" SG_ 2566733054 Aftrtrtmnt1DslExhstFldTnkDrnVlvC 5436;
BA_ "SigType" SG_ 2566733054 Aftrtrtmnt1DslExhstFlidPumpState 5;
BA_ "SPN" SG_ 2566733054 Aftrtrtmnt1DslExhstFlidPumpState 5435;
BA_ "SPN" SG_ 2566733054 Aftrtrtmnt1DslExhstFldTnkFllVlvC 5434;
BA_ "SPN" SG_ 2566733054 Aftrtrtmnt1DslExhstFldRturnValve 4376;
BA_ "SPN" SG_ 2566733054 Aftrtrtmnt1DslExhstFldPmpDrvPrcn 4375;
BA_ "SigType" SG_ 2566733054 Aftrtrtmnt1DslExhstFldPmpMtrSped 1;
BA_ "SPN" SG_ 2566733054 Aftrtrtmnt1DslExhstFldPmpMtrSped 4374;
BA_ "SPN" SG_ 2499624702 Aftrtrtmnt1SCRCtlystOtltGsTmpPrl 4362;
BA_ "SigType" SG_ 2499624702 Aftrtrtmnt1SCRCtlystOtletGasTemp 1;
BA_ "SPN" SG_ 2499624702 Aftrtrtmnt1SCRCtlystOtletGasTemp 4363;
BA_ "SPN" SG_ 2499624702 Aftrtrtmnt1SCRCtlystIntkGsTmpPrl 4361;
BA_ "SigType" SG_ 2499624702 Aftrtrtmnt1SCRCtlystIntkeGasTemp 1;
BA_ "SPN" SG_ 2499624702 Aftrtrtmnt1SCRCtlystIntkeGasTemp 4360;
BA_ "SPN" SG_ 2566733822 Aftrtrtmnt1SCRExhstGsDffPrssPrlm 4359;
BA_ "SigType" SG_ 2566733822 Aftrtrtmnt1SCRExhustGasDiffPress 1;
BA_ "SPN" SG_ 2566733822 Aftrtrtmnt1SCRExhustGasDiffPress 4358;
BA_ "SPN" SG_ 2566734078 Aftrtrtmnt1DslExhstFldPmpHterCmd 5707;
BA_ "SPN" SG_ 2566734078 Aftrtrtmnt1DslExhstFldTnk2HtrCmd 5414;
BA_ "SPN" SG_ 2566734078 Aftrtrtmnt1DslExhstFldTnkHterCmd 5137;
BA_ "SigType" SG_ 2566734078 Aftrtrtmnt1DslExhstFldLneHeater4 5;
BA_ "SPN" SG_ 2566734078 Aftrtrtmnt1DslExhstFldLneHeater4 4357;
BA_ "SigType" SG_ 2566734078 Aftrtrtmnt1DslExhstFldLneHeater3 5;
BA_ "SPN" SG_ 2566734078 Aftrtrtmnt1DslExhstFldLneHeater3 4356;
BA_ "SigType" SG_ 2566734078 Aftrtrtmnt1DslExhstFldLneHeater2 5;
BA_ "SPN" SG_ 2566734078 Aftrtrtmnt1DslExhstFldLneHeater2 4355;
BA_ "SigType" SG_ 2566734078 Aftrtrtmnt1DslExhstFldLneHeater1 5;
BA_ "SPN" SG_ 2566734078 Aftrtrtmnt1DslExhstFldLneHeater1 4354;
BA_ "SPN" SG_ 2566734078 Aftrtrtmnt1DslExhstFldDsrHtngMdR 4353;
BA_ "SigType" SG_ 2566734078 Aftrtrtmnt1DslExhstFldDsrFltSppr 5;
BA_ "SPN" SG_ 2566734078 Aftrtrtmnt1DslExhstFldDsrFltSppr 4352;
BA_ "SigType" SG_ 2364548350 Aftrtrtmnt1DslExhstFldRqstdQntty 1;
BA_ "SPN" SG_ 2364548350 Aftrtrtmnt1DslExhstFldRqstdQntty 4350;
BA_ "SPN" SG_ 2364548350 Aftrtrtmnt1SCRSystmRquestedState 4349;
BA_ "SigType" SG_ 2364548350 Aftrtrtmnt1DslExhstFldDsngRqstdQ 1;
BA_ "SPN" SG_ 2364548350 Aftrtrtmnt1DslExhstFldDsngRqstdQ 4348;
BA_ "SPN" SG_ 2566734334 Aftrtrtmnt1DslExhstFldLnHtr4Prlm 4347;
BA_ "SigType" SG_ 2566734334 Aftrtrtmnt1DslExhstFldLnHtr4Stte 5;
BA_ "SPN" SG_ 2566734334 Aftrtrtmnt1DslExhstFldLnHtr4Stte 4346;
BA_ "SPN" SG_ 2566734334 Aftrtrtmnt1DslExhstFldLnHtr3Prlm 4345;
BA_ "SigType" SG_ 2566734334 Aftrtrtmnt1DslExhstFldLnHtr3Stte 5;
BA_ "SPN" SG_ 2566734334 Aftrtrtmnt1DslExhstFldLnHtr3Stte 4344;
BA_ "SPN" SG_ 2566734334 Aftrtrtmnt1DslExhstFldLnHtr2Prlm 4343;
BA_ "SigType" SG_ 2566734334 Aftrtrtmnt1DslExhstFldLnHtr2Stte 5;
BA_ "SPN" SG_ 2566734334 Aftrtrtmnt1DslExhstFldLnHtr2Stte 4342;
BA_ "SPN" SG_ 2566734334 Aftrtrtmnt1DslExhstFldLnHtr1Prlm 4341;
BA_ "SigType" SG_ 2566734334 Aftrtrtmnt1DslExhstFldLnHtr1Stte 5;
BA_ "SPN" SG_ 2566734334 Aftrtrtmnt1DslExhstFldLnHtr1Stte 4340;
BA_ "SPN" SG_ 2566734334 Aftrtrtmnt1SCRFeedbackCtrlStatus 4339;
BA_ "SPN" SG_ 2566734334 Aftrtrtmnt1SCRDsngVlvExhstTmpRdc 4338;
BA_ "SigType" SG_ 2566734334 Aftrtrtmnt1DslExhstFldDosingTemp 1;
BA_ "SPN" SG_ 2566734334 Aftrtrtmnt1DslExhstFldDosingTemp 4337;
BA_ "SPN" SG_ 2566734334 Aftrtrtmnt1SCRDsngAirAssistValve 4336;
BA_ "SigType" SG_ 2566734334 Aftrtrtmnt1SCRDsngArAssstAbsPrss 1;
BA_ "SPN" SG_ 2566734334 Aftrtrtmnt1SCRDsngArAssstAbsPrss 4335;
BA_ "SigType" SG_ 2364548094 Aftrtrtmnt1DslExhstFldDsrAbsPrss 1;
BA_ "SPN" SG_ 2364548094 Aftrtrtmnt1DslExhstFldDsrAbsPrss 4334;
BA_ "SigType" SG_ 2364548094 Aftrtrtmnt1DslExhstFldActlQnttyO 1;
BA_ "SPN" SG_ 2364548094 Aftrtrtmnt1DslExhstFldActlQnttyO 4333;
BA_ "SPN" SG_ 2364548094 Aftertreatment1SCRSystemState 4332;
BA_ "SigType" SG_ 2364548094 Aftrtrtmnt1DslExhstFldActlDsngQn 1;
BA_ "SPN" SG_ 2364548094 Aftrtrtmnt1DslExhstFldActlDsngQn 4331;
BA_ "SigType" SG_ 2364548606 Aftrtrtmnt1OtltNH3GsSnsrHterCtrl 5;
BA_ "SPN" SG_ 2364548606 Aftrtrtmnt1OtltNH3GsSnsrHterCtrl 4383;
BA_ "SPN" SG_ 2364548606 Aftrtrtmnt1OtltNH3GsSnsrHtrPrlmn 4382;
BA_ "SigType" SG_ 2364548606 Aftrtrtmnt1OtltNH3GsSensorAtTemp 5;
BA_ "SPN" SG_ 2364548606 Aftrtrtmnt1OtltNH3GsSensorAtTemp 4381;
BA_ "SigType" SG_ 2364548606 Aftrtrtmnt1OtltNH3GsSnsrPwrInRng 5;
BA_ "SPN" SG_ 2364548606 Aftrtrtmnt1OtltNH3GsSnsrPwrInRng 4380;
BA_ "SigType" SG_ 2364548606 Aftrtrtmnt1OtletNH3ReadingStable 5;
BA_ "SPN" SG_ 2364548606 Aftrtrtmnt1OtletNH3ReadingStable 4379;
BA_ "SPN" SG_ 2364548606 Aftrtrtmnt1OtltNH3SnsrPrlmnryFMI 4378;
BA_ "SigType" SG_ 2364548606 Aftertreatment1OutletNH3 1;
BA_ "SPN" SG_ 2364548606 Aftertreatment1OutletNH3 4377;
BA_ "SPN" SG_ 2566726398 Aftrtrtmnt1GsOxdtnCtlystDffPrssP 4758;
BA_ "SPN" SG_ 2566726398 Aftrtrtmnt1GsOxdtnCtlystOtlt4757 4757;
BA_ "SPN" SG_ 2566726398 Aftrtrtmnt1GsOxdtnCtlystIntk4756 4756;
BA_ "SigType" SG_ 2566726398 Aftrtrtmnt1GsOxdtnCtlystDffPress 1;
BA_ "SPN" SG_ 2566726398 Aftrtrtmnt1GsOxdtnCtlystDffPress 4755;
BA_ "SigType" SG_ 2566726398 Aftrtrtmnt1GsOxdtnCtlystOtltGsTm 1;
BA_ "SPN" SG_ 2566726398 Aftrtrtmnt1GsOxdtnCtlystOtltGsTm 4754;
BA_ "SigType" SG_ 2566726398 Aftrtrtmnt1GsOxdtnCtlystIntkGsTm 1;
BA_ "SPN" SG_ 2566726398 Aftrtrtmnt1GsOxdtnCtlystIntkGsTm 4753;
BA_ "SigType" SG_ 2566742270 FailureSpecificB1Counter 1;
BA_ "SPN" SG_ 2566742270 FailureSpecificB1Counter 4147;
BA_ "SPN" SG_ 2566742270 FailureModeIdentifier1 1215;
BA_ "SPN" SG_ 2566742270 SPN1 1214;
BA_ "SigType" SG_ 2566742526 SysGreatestB1Counter 1;
BA_ "SPN" SG_ 2566742526 SysGreatestB1Counter 4146;
BA_ "SigType" SG_ 2566742526 SysCumulativeContinuousMITime 1;
BA_ "SPN" SG_ 2566742526 SysCumulativeContinuousMITime 4145;
BA_ "SigType" SG_ 2566742782 RegulationDescription 8;
BA_ "SPN" SG_ 2566742782 RegulationDescription 4144;
BA_ "SigType" SG_ 2566743038 SysIncompleteMonitorCount 1;
BA_ "SPN" SG_ 2566743038 SysIncompleteMonitorCount 4143;
BA_ "SPN" SG_ 2566743038 SysMalIndActivationMode 4142;
BA_ "SigType" SG_ 2566743038 SysMalIndDisplayStrategy 4;
BA_ "SPN" SG_ 2566743038 SysMalIndDisplayStrategy 4141;
BA_ "SigType" SG_ 2566743038 SysContinuousMalfunctionInd 4;
BA_ "SPN" SG_ 2566743038 SysContinuousMalfunctionInd 4140;
BA_ "SigType" SG_ 2566743038 SysNonRoadworthyCompCount 1;
BA_ "SPN" SG_ 2566743038 SysNonRoadworthyCompCount 4139;
BA_ "SigType" SG_ 2566743294 VehicleCurrentMIAccumTime 1;
BA_ "SPN" SG_ 2566743294 VehicleCurrentMIAccumTime 4138;
BA_ "SigType" SG_ 2566743294 VehicleIncompleteMonitorCount 1;
BA_ "SPN" SG_ 2566743294 VehicleIncompleteMonitorCount 4137;
BA_ "SigType" SG_ 2566743294 VehicleMalfunctionIndActMode 4;
BA_ "SPN" SG_ 2566743294 VehicleMalfunctionIndActMode 4136;
BA_ "SigType" SG_ 2566743294 VehicleMalfunctionIndStrategy 4;
BA_ "SPN" SG_ 2566743294 VehicleMalfunctionIndStrategy 4135;
BA_ "SigType" SG_ 2566743294 VehicleContinuousMalfunctionInd 4;
BA_ "SPN" SG_ 2566743294 VehicleContinuousMalfunctionInd 4134;
BA_ "SigType" SG_ 2566743294 VehicleNonRoadworthyCompCount 1;
BA_ "SPN" SG_ 2566743294 VehicleNonRoadworthyCompCount 4133;
BA_ "SigType" SG_ 2560687870 PMNTEDeficiencyAreaStatus 4;
BA_ "SPN" SG_ 2560687870 PMNTEDeficiencyAreaStatus 4132;
BA_ "SigType" SG_ 2560687870 MnfcPMNTECarveOutAreaStatus 4;
BA_ "SPN" SG_ 2560687870 MnfcPMNTECarveOutAreaStatus 4131;
BA_ "SigType" SG_ 2560687870 PMNTEControlAreaStatus 4;
BA_ "SPN" SG_ 2560687870 PMNTEControlAreaStatus 4130;
BA_ "SigType" SG_ 2560687870 NOxNTEDeficiencyAreaStatus 4;
BA_ "SPN" SG_ 2560687870 NOxNTEDeficiencyAreaStatus 4129;
BA_ "SigType" SG_ 2560687870 MnfcNOxNTECarveOutAreaStatus 4;
BA_ "SPN" SG_ 2560687870 MnfcNOxNTECarveOutAreaStatus 4128;
BA_ "SigType" SG_ 2560687870 NOxNTEControlAreaStatus 4;
BA_ "SPN" SG_ 2560687870 NOxNTEControlAreaStatus 4127;
BA_ "SigType" SG_ 2292317950 AECDEngineHours1Timer2 1;
BA_ "SPN" SG_ 2292317950 AECDEngineHours1Timer2 4126;
BA_ "SigType" SG_ 2292317950 AECDEngineHours1Timer1 1;
BA_ "SPN" SG_ 2292317950 AECDEngineHours1Timer1 4125;
BA_ "SigType" SG_ 2292317950 AECDNumber1 1;
BA_ "SPN" SG_ 2292317950 AECDNumber1 4124;
BA_ "SigType" SG_ 2566809342 BatteryMainSwitchHoldState 4;
BA_ "SPN" SG_ 2566809342 BatteryMainSwitchHoldState 1681;
BA_ "SigType" SG_ 2365446910 Joystick3XAxisDetentPosStatus 4;
BA_ "SPN" SG_ 2365446910 Joystick3XAxisDetentPosStatus 2754;
BA_ "SigType" SG_ 2365446910 Joystick3Button9PressedStatus 4;
BA_ "SPN" SG_ 2365446910 Joystick3Button9PressedStatus 2767;
BA_ "SigType" SG_ 2365446910 Joystick3Button10PressedStatus 4;
BA_ "SPN" SG_ 2365446910 Joystick3Button10PressedStatus 2768;
BA_ "SigType" SG_ 2365446910 Joystick3Button11PressedStatus 4;
BA_ "SPN" SG_ 2365446910 Joystick3Button11PressedStatus 2769;
BA_ "SigType" SG_ 2365446910 Joystick3Button12PressedStatus 4;
BA_ "SPN" SG_ 2365446910 Joystick3Button12PressedStatus 2770;
BA_ "SigType" SG_ 2365446910 Joystick3YAxisDetentPosStatus 4;
BA_ "SPN" SG_ 2365446910 Joystick3YAxisDetentPosStatus 2755;
BA_ "SPN" SG_ 2365446910 Joystick3YAxisPos 2735;
BA_ "SigType" SG_ 2365446910 Jystck3YAxsLvrFrwrdPstvPosStatus 4;
BA_ "SPN" SG_ 2365446910 Jystck3YAxsLvrFrwrdPstvPosStatus 2740;
BA_ "SigType" SG_ 2365446910 Jystck3YAxsLvrBckNgtivePosStatus 4;
BA_ "SPN" SG_ 2365446910 Jystck3YAxsLvrBckNgtivePosStatus 2745;
BA_ "SigType" SG_ 2365446910 Joystick3YAxisNeutralPosStatus 4;
BA_ "SPN" SG_ 2365446910 Joystick3YAxisNeutralPosStatus 2750;
BA_ "SPN" SG_ 2365446910 Joystick3XAxisPos 2734;
BA_ "SigType" SG_ 2365446910 Jystck3XAxsLvrRghtPstvePosStatus 4;
BA_ "SPN" SG_ 2365446910 Jystck3XAxsLvrRghtPstvePosStatus 2739;
BA_ "SigType" SG_ 2365446910 Jystck3XAxsLvrLftNgtivePosStatus 4;
BA_ "SPN" SG_ 2365446910 Jystck3XAxsLvrLftNgtivePosStatus 2744;
BA_ "SigType" SG_ 2365446910 Joystick3XAxisNeutralPosStatus 4;
BA_ "SPN" SG_ 2365446910 Joystick3XAxisNeutralPosStatus 2749;
BA_ "SigType" SG_ 2365446910 Joystick3Button5PressedStatus 4;
BA_ "SPN" SG_ 2365446910 Joystick3Button5PressedStatus 2763;
BA_ "SigType" SG_ 2365446910 Joystick3Button6PressedStatus 4;
BA_ "SPN" SG_ 2365446910 Joystick3Button6PressedStatus 2764;
BA_ "SigType" SG_ 2365446910 Joystick3Button7PressedStatus 4;
BA_ "SPN" SG_ 2365446910 Joystick3Button7PressedStatus 2765;
BA_ "SigType" SG_ 2365446910 Joystick3Button8PressedStatus 4;
BA_ "SPN" SG_ 2365446910 Joystick3Button8PressedStatus 2766;
BA_ "SigType" SG_ 2365446910 Joystick3Button1PressedStatus 4;
BA_ "SPN" SG_ 2365446910 Joystick3Button1PressedStatus 2759;
BA_ "SigType" SG_ 2365446910 Joystick3Button2PressedStatus 4;
BA_ "SPN" SG_ 2365446910 Joystick3Button2PressedStatus 2760;
BA_ "SigType" SG_ 2365446910 Joystick3Button3PressedStatus 4;
BA_ "SPN" SG_ 2365446910 Joystick3Button3PressedStatus 2761;
BA_ "SigType" SG_ 2365446910 Joystick3Button4PressedStatus 4;
BA_ "SPN" SG_ 2365446910 Joystick3Button4PressedStatus 2762;
BA_ "SigType" SG_ 2365446398 Joystick2XAxisDetentPosStatus 4;
BA_ "SPN" SG_ 2365446398 Joystick2XAxisDetentPosStatus 2717;
BA_ "SigType" SG_ 2365446398 Joystick2YAxisDetentPosStatus 4;
BA_ "SPN" SG_ 2365446398 Joystick2YAxisDetentPosStatus 2718;
BA_ "SPN" SG_ 2365446398 Joystick2YAxisPos 2698;
BA_ "SigType" SG_ 2365446398 Jystck2YAxsLvrFrwrdPstvPosStatus 4;
BA_ "SPN" SG_ 2365446398 Jystck2YAxsLvrFrwrdPstvPosStatus 2703;
BA_ "SigType" SG_ 2365446398 Jystck2YAxsLvrBckNgtivePosStatus 4;
BA_ "SPN" SG_ 2365446398 Jystck2YAxsLvrBckNgtivePosStatus 2708;
BA_ "SigType" SG_ 2365446398 Joystick2YAxisNeutralPosStatus 4;
BA_ "SPN" SG_ 2365446398 Joystick2YAxisNeutralPosStatus 2713;
BA_ "SPN" SG_ 2365446398 Joystick2XAxisPos 2697;
BA_ "SigType" SG_ 2365446398 Jystck2XAxsLvrRghtPstvePosStatus 4;
BA_ "SPN" SG_ 2365446398 Jystck2XAxsLvrRghtPstvePosStatus 2702;
BA_ "SigType" SG_ 2365446398 Jystck2XAxsLvrLftNgtivePosStatus 4;
BA_ "SPN" SG_ 2365446398 Jystck2XAxsLvrLftNgtivePosStatus 2707;
BA_ "SigType" SG_ 2365446398 Joystick2XAxisNeutralPosStatus 4;
BA_ "SPN" SG_ 2365446398 Joystick2XAxisNeutralPosStatus 2712;
BA_ "SigType" SG_ 2365446398 Joystick2Button9PressedStatus 4;
BA_ "SPN" SG_ 2365446398 Joystick2Button9PressedStatus 2730;
BA_ "SigType" SG_ 2365446398 Joystick2Button10PressedStatus 4;
BA_ "SPN" SG_ 2365446398 Joystick2Button10PressedStatus 2731;
BA_ "SigType" SG_ 2365446398 Joystick2Button11PressedStatus 4;
BA_ "SPN" SG_ 2365446398 Joystick2Button11PressedStatus 2732;
BA_ "SigType" SG_ 2365446398 Joystick2Button12PressedStatus 4;
BA_ "SPN" SG_ 2365446398 Joystick2Button12PressedStatus 2733;
BA_ "SigType" SG_ 2365446398 Joystick2Button5PressedStatus 4;
BA_ "SPN" SG_ 2365446398 Joystick2Button5PressedStatus 2726;
BA_ "SigType" SG_ 2365446398 Joystick2Button6PressedStatus 4;
BA_ "SPN" SG_ 2365446398 Joystick2Button6PressedStatus 2727;
BA_ "SigType" SG_ 2365446398 Joystick2Button7PressedStatus 4;
BA_ "SPN" SG_ 2365446398 Joystick2Button7PressedStatus 2728;
BA_ "SigType" SG_ 2365446398 Joystick2Button8PressedStatus 4;
BA_ "SPN" SG_ 2365446398 Joystick2Button8PressedStatus 2729;
BA_ "SigType" SG_ 2365446398 Joystick2Button1PressedStatus 4;
BA_ "SPN" SG_ 2365446398 Joystick2Button1PressedStatus 2722;
BA_ "SigType" SG_ 2365446398 Joystick2Button2PressedStatus 4;
BA_ "SPN" SG_ 2365446398 Joystick2Button2PressedStatus 2723;
BA_ "SigType" SG_ 2365446398 Joystick2Button3PressedStatus 4;
BA_ "SPN" SG_ 2365446398 Joystick2Button3PressedStatus 2724;
BA_ "SigType" SG_ 2365446398 Joystick2Button4PressedStatus 4;
BA_ "SPN" SG_ 2365446398 Joystick2Button4PressedStatus 2725;
BA_ "SigType" SG_ 2365445886 Joystick1XAxisDetentPosStatus 4;
BA_ "SPN" SG_ 2365445886 Joystick1XAxisDetentPosStatus 2680;
BA_ "SigType" SG_ 2365445886 Joystick1YAxisDetentPosStatus 4;
BA_ "SPN" SG_ 2365445886 Joystick1YAxisDetentPosStatus 2681;
BA_ "SPN" SG_ 2365445886 Joystick1YAxisPos 2661;
BA_ "SigType" SG_ 2365445886 Jystck1YAxsLvrFrwrdPstvPosStatus 4;
BA_ "SPN" SG_ 2365445886 Jystck1YAxsLvrFrwrdPstvPosStatus 2666;
BA_ "SigType" SG_ 2365445886 Jystck1YAxsLvrBckNgtivePosStatus 4;
BA_ "SPN" SG_ 2365445886 Jystck1YAxsLvrBckNgtivePosStatus 2671;
BA_ "SigType" SG_ 2365445886 Joystick1YAxisNeutralPosStatus 4;
BA_ "SPN" SG_ 2365445886 Joystick1YAxisNeutralPosStatus 2676;
BA_ "SPN" SG_ 2365445886 Joystick1XAxisPos 2660;
BA_ "SigType" SG_ 2365445886 Joystick1Button9PressedStatus 4;
BA_ "SPN" SG_ 2365445886 Joystick1Button9PressedStatus 2693;
BA_ "SigType" SG_ 2365445886 Joystick1Button10PressedStatus 4;
BA_ "SPN" SG_ 2365445886 Joystick1Button10PressedStatus 2694;
BA_ "SigType" SG_ 2365445886 Joystick1Button11PressedStatus 4;
BA_ "SPN" SG_ 2365445886 Joystick1Button11PressedStatus 2695;
BA_ "SigType" SG_ 2365445886 Joystick1Button12PressedStatus 4;
BA_ "SPN" SG_ 2365445886 Joystick1Button12PressedStatus 2696;
BA_ "SigType" SG_ 2365445886 Joystick1Button5PressedStatus 4;
BA_ "SPN" SG_ 2365445886 Joystick1Button5PressedStatus 2689;
BA_ "SigType" SG_ 2365445886 Joystick1Button6PressedStatus 4;
BA_ "SPN" SG_ 2365445886 Joystick1Button6PressedStatus 2690;
BA_ "SigType" SG_ 2365445886 Joystick1Button7PressedStatus 4;
BA_ "SPN" SG_ 2365445886 Joystick1Button7PressedStatus 2691;
BA_ "SigType" SG_ 2365445886 Joystick1Button8PressedStatus 4;
BA_ "SPN" SG_ 2365445886 Joystick1Button8PressedStatus 2692;
BA_ "SigType" SG_ 2365445886 Joystick1Button1PressedStatus 4;
BA_ "SPN" SG_ 2365445886 Joystick1Button1PressedStatus 2685;
BA_ "SigType" SG_ 2365445886 Joystick1Button2PressedStatus 4;
BA_ "SPN" SG_ 2365445886 Joystick1Button2PressedStatus 2686;
BA_ "SigType" SG_ 2365445886 Joystick1Button3PressedStatus 4;
BA_ "SPN" SG_ 2365445886 Joystick1Button3PressedStatus 2687;
BA_ "SigType" SG_ 2365445886 Joystick1Button4PressedStatus 4;
BA_ "SPN" SG_ 2365445886 Joystick1Button4PressedStatus 2688;
BA_ "SigType" SG_ 2365445886 Jystck1XAxsLvrRghtPstvePosStatus 4;
BA_ "SPN" SG_ 2365445886 Jystck1XAxsLvrRghtPstvePosStatus 2665;
BA_ "SigType" SG_ 2365445886 Jystck1XAxsLvrLftNgtivePosStatus 4;
BA_ "SPN" SG_ 2365445886 Jystck1XAxsLvrLftNgtivePosStatus 2670;
BA_ "SigType" SG_ 2365445886 Joystick1XAxisNeutralPosStatus 4;
BA_ "SPN" SG_ 2365445886 Joystick1XAxisNeutralPosStatus 2675;
BA_ "SigType" SG_ 2566847230 ParkingBrakeRedWarningSignal 5;
BA_ "SPN" SG_ 2566847230 ParkingBrakeRedWarningSignal 3557;
BA_ "SigType" SG_ 2566847230 ParkBrakeReleaseInhibitStatus 4;
BA_ "SPN" SG_ 2566847230 ParkBrakeReleaseInhibitStatus 3808;
BA_ "SigType" SG_ 2566847230 ParkingBrakeActuator 4;
BA_ "SPN" SG_ 2566847230 ParkingBrakeActuator 619;
BA_ "SigType" SG_ 2566847230 BrakeSecondPress 1;
BA_ "SPN" SG_ 2566847230 BrakeSecondPress 118;
BA_ "SigType" SG_ 2566847230 BrakePrimaryPress 1;
BA_ "SPN" SG_ 2566847230 BrakePrimaryPress 117;
BA_ "SigType" SG_ 2566847230 BrakeAppPress 1;
BA_ "SPN" SG_ 2566847230 BrakeAppPress 116;
BA_ "SigType" SG_ 2566848254 AuxPumpPress 1;
BA_ "SPN" SG_ 2566848254 AuxPumpPress 73;
BA_ "SPN" SG_ 2566725886 Aftrtrtmnt1DslOxdtnCtlystDff4770 4770;
BA_ "SPN" SG_ 2566725886 Aftrtrtmnt1DslOxdtnCtlystOtl4769 4769;
BA_ "SPN" SG_ 2566725886 Aftrtrtmnt1DslOxdtnCtlystInt4768 4768;
BA_ "SigType" SG_ 2566725886 Aftrtrtmnt1DslOxdtnCtlystDffPrss 1;
BA_ "SPN" SG_ 2566725886 Aftrtrtmnt1DslOxdtnCtlystDffPrss 4767;
BA_ "SigType" SG_ 2566725886 Aftrtrtmnt1DslOxdtnCtlystOtltGsT 1;
BA_ "SPN" SG_ 2566725886 Aftrtrtmnt1DslOxdtnCtlystOtltGsT 4766;
BA_ "SigType" SG_ 2566725886 Aftrtrtmnt1DslOxdtnCtlystIntkGsT 1;
BA_ "SPN" SG_ 2566725886 Aftrtrtmnt1DslOxdtnCtlystIntkGsT 4765;
BA_ "SigType" SG_ 2560884478 DTCWarnLampSupportStatus 4;
BA_ "SPN" SG_ 2560884478 DTCWarnLampSupportStatus 4115;
BA_ "SigType" SG_ 2560884478 DTCWarnLampSupportFlash 4;
BA_ "SPN" SG_ 2560884478 DTCWarnLampSupportFlash 4119;
BA_ "SigType" SG_ 2560884478 DTCStopLampSupportStatus 4;
BA_ "SPN" SG_ 2560884478 DTCStopLampSupportStatus 4114;
BA_ "SigType" SG_ 2560884478 DTCStopLampSupportFlash 4;
BA_ "SPN" SG_ 2560884478 DTCStopLampSupportFlash 4118;
BA_ "SigType" SG_ 2560884478 DTCProtectLampSupportStatus 4;
BA_ "SPN" SG_ 2560884478 DTCProtectLampSupportStatus 4116;
BA_ "SigType" SG_ 2560884478 DTCProtectLampSupportFlash 4;
BA_ "SPN" SG_ 2560884478 DTCProtectLampSupportFlash 4120;
BA_ "SPN" SG_ 2560884478 DTCMilSupportStatus 4113;
BA_ "SPN" SG_ 2560884478 DTCMilSupportFlash 4117;
BA_ "SigType" SG_ 2560884478 DTC1 7;
BA_ "SPN" SG_ 2560360190 DataDictionaryMethod 4181;
BA_ "SPN" SG_ 2560360190 DataDictionaryManufacturerCode 4180;
BA_ "SPN" SG_ 2566736126 EngExhstGsOxygnSnsrClsdLpOprtnBn 4241;
BA_ "SPN" SG_ 2566736126 ShorttermFuelTrimBank2 4238;
BA_ "SPN" SG_ 2566736126 LongtermFuelTrimBank2 4239;
BA_ "SPN" SG_ 2566736382 EngExhstGsOxygnSnsrClsdLpOprtnBn 4240;
BA_ "SPN" SG_ 2566736382 ShorttermFuelTrimBank1 4236;
BA_ "SPN" SG_ 2566736382 LongtermFuelTrimBank1 4237;
BA_ "SigType" SG_ 2565874174 EngSpdSensor1TimingPatternStatus 5;
BA_ "SPN" SG_ 2565874174 EngSpdSensor1TimingPatternStatus 4203;
BA_ "SigType" SG_ 2565874174 EngSpdSensor2TimingPatternStatus 5;
BA_ "SPN" SG_ 2565874174 EngSpdSensor2TimingPatternStatus 4204;
BA_ "SigType" SG_ 2565874174 EngSpdSensor3TimingPatternStatus 5;
BA_ "SPN" SG_ 2565874174 EngSpdSensor3TimingPatternStatus 4205;
BA_ "SigType" SG_ 2565874174 EngSpeed3 1;
BA_ "SPN" SG_ 2565874174 EngSpeed3 4202;
BA_ "SigType" SG_ 2565874174 EngSpeed2 1;
BA_ "SPN" SG_ 2565874174 EngSpeed2 723;
BA_ "SigType" SG_ 2565874174 EngSpeed1 1;
BA_ "SPN" SG_ 2565874174 EngSpeed1 4201;
BA_ "SPN" SG_ 2432520958 EngAxClerSupplyValve2ActuatorCmd 5547;
BA_ "SPN" SG_ 2432520958 EngAxClerSupplyValve1ActuatorCmd 5546;
BA_ "SPN" SG_ 2432520958 DsredEngCoolantThermostatOpening 4197;
BA_ "SigType" SG_ 2432520958 DesiredEngCoolantPumpOutletTemp 1;
BA_ "SPN" SG_ 2432520958 DesiredEngCoolantPumpOutletTemp 4196;
BA_ "SigType" SG_ 2432520958 EngCoolantThermostatMode 5;
BA_ "SPN" SG_ 2432520958 EngCoolantThermostatMode 4195;
BA_ "SPN" SG_ 2560425726 AuxI_OChannel19 4174;
BA_ "SPN" SG_ 2560425726 AuxI_OChannel20 4173;
BA_ "SPN" SG_ 2560425726 AuxI_OChannel21 4172;
BA_ "SPN" SG_ 2560425726 AuxI_OChannel22 4171;
BA_ "SPN" SG_ 2560425726 AuxI_OChannel15 4170;
BA_ "SPN" SG_ 2560425726 AuxI_OChannel16 4169;
BA_ "SPN" SG_ 2560425726 AuxI_OChannel17 4168;
BA_ "SPN" SG_ 2560425726 AuxI_OChannel18 4167;
BA_ "SPN" SG_ 2560491262 AuxI_OChannel11 4166;
BA_ "SPN" SG_ 2560491262 AuxI_OChannel12 4165;
BA_ "SPN" SG_ 2560491262 AuxI_OChannel13 4164;
BA_ "SPN" SG_ 2560491262 AuxI_OChannel14 4163;
BA_ "SPN" SG_ 2560491262 AuxI_OChannel7 4162;
BA_ "SPN" SG_ 2560491262 AuxI_OChannel8 4161;
BA_ "SPN" SG_ 2560491262 AuxI_OChannel9 4160;
BA_ "SPN" SG_ 2560491262 AuxI_OChannel10 4159;
BA_ "SPN" SG_ 2349399806 AuxI_OChannel3 4158;
BA_ "SPN" SG_ 2349399806 AuxI_OChannel4 4157;
BA_ "SPN" SG_ 2349399806 AuxI_OChannel5 4156;
BA_ "SPN" SG_ 2349399806 AuxI_OChannel6 4155;
BA_ "SigType" SG_ 2566758398 Aftertreatment1AirEnableActuator 5;
BA_ "SPN" SG_ 2566758398 Aftertreatment1AirEnableActuator 3489;
BA_ "SigType" SG_ 2566758398 Aftertreatment1PurgeAirActuator 5;
BA_ "SPN" SG_ 2566758398 Aftertreatment1PurgeAirActuator 3490;
BA_ "SigType" SG_ 2566758398 Aftrtrtmnt1AtmizationAirActuator 5;
BA_ "SPN" SG_ 2566758398 Aftrtrtmnt1AtmizationAirActuator 3491;
BA_ "SigType" SG_ 2566758398 Aftertreatment1AirSystemRelay 5;
BA_ "SPN" SG_ 2566758398 Aftertreatment1AirSystemRelay 3492;
BA_ "SigType" SG_ 2566758398 Aftrtratment1AirPressActuatorPos 1;
BA_ "SPN" SG_ 2566758398 Aftrtratment1AirPressActuatorPos 3488;
BA_ "SigType" SG_ 2566758398 Aftertreatment1AirPressCtrl 1;
BA_ "SPN" SG_ 2566758398 Aftertreatment1AirPressCtrl 3487;
BA_ "SigType" SG_ 2566758398 Aftertreatment1PurgeAirPress 1;
BA_ "SPN" SG_ 2566758398 Aftertreatment1PurgeAirPress 3486;
BA_ "SigType" SG_ 2566758398 Aftertreatment1SupplyAirPress 1;
BA_ "SPN" SG_ 2566758398 Aftertreatment1SupplyAirPress 3485;
BA_ "SigType" SG_ 2566745598 Aftertreatment1SecondAirPress 1;
BA_ "SPN" SG_ 2566745598 Aftertreatment1SecondAirPress 3837;
BA_ "SigType" SG_ 2566745598 Aftertreatment1SecondAirMassFlow 1;
BA_ "SPN" SG_ 2566745598 Aftertreatment1SecondAirMassFlow 3832;
BA_ "SigType" SG_ 2566745598 Aftertreatment1SecondAirTemp 1;
BA_ "SPN" SG_ 2566745598 Aftertreatment1SecondAirTemp 3831;
BA_ "SigType" SG_ 2566745598 Aftrtreatment1SecondAirDiffPress 1;
BA_ "SPN" SG_ 2566745598 Aftrtreatment1SecondAirDiffPress 3830;
BA_ "SPN" SG_ 2566758910 Aftrtrtmnt1FlInjector1HeaterCtrl 4301;
BA_ "SigType" SG_ 2566758910 Aftrtreatment1FuelEnableActuator 5;
BA_ "SPN" SG_ 2566758910 Aftrtreatment1FuelEnableActuator 3482;
BA_ "SigType" SG_ 2566758910 Aftrtreatment1RegenerationStatus 5;
BA_ "SPN" SG_ 2566758910 Aftrtreatment1RegenerationStatus 3483;
BA_ "SigType" SG_ 2566758910 Aftertreatment1Ignt 5;
BA_ "SPN" SG_ 2566758910 Aftertreatment1Ignt 3484;
BA_ "SigType" SG_ 2566758910 Aftertreatment1FuelDrainActuator 5;
BA_ "SPN" SG_ 2566758910 Aftertreatment1FuelDrainActuator 4097;
BA_ "SPN" SG_ 2566758910 Aftertreatment1FuelPress1Ctrl 3479;
BA_ "SigType" SG_ 2566758910 Aftertreatment1FuelRate 1;
BA_ "SPN" SG_ 2566758910 Aftertreatment1FuelRate 3481;
BA_ "SigType" SG_ 2566758910 Aftertreatment1FuelPress1 1;
BA_ "SPN" SG_ 2566758910 Aftertreatment1FuelPress1 3480;
BA_ "SigType" SG_ 2566743550 Aftrtrtmnt1HydrcrbnDsrIntkFlTemp 1;
BA_ "SPN" SG_ 2566743550 Aftrtrtmnt1HydrcrbnDsrIntkFlTemp 5456;
BA_ "SPN" SG_ 2566743550 Aftrtrtmnt1FelPress2ActuatorCtrl 5425;
BA_ "SigType" SG_ 2566743550 Aftrtrtmnt1FlFlwDverterValveCtrl 5;
BA_ "SPN" SG_ 2566743550 Aftrtrtmnt1FlFlwDverterValveCtrl 5424;
BA_ "SigType" SG_ 2566743550 Aftertreatment1FuelPumpRelayCtrl 5;
BA_ "SPN" SG_ 2566743550 Aftertreatment1FuelPumpRelayCtrl 5423;
BA_ "SigType" SG_ 2566743550 Aftertreatment1FuelPress2 1;
BA_ "SPN" SG_ 2566743550 Aftertreatment1FuelPress2 4077;
BA_ "SigType" SG_ 2566753534 DslParticulateFilterOutletPress1 1;
BA_ "SPN" SG_ 2566753534 DslParticulateFilterOutletPress1 3610;
BA_ "SigType" SG_ 2566753534 DslParticulateFilterIntakePress1 1;
BA_ "SPN" SG_ 2566753534 DslParticulateFilterIntakePress1 3609;
BA_ "SPN" SG_ 2566756606 Aftrtrtmnt1AvrgDstncBtwnActvDPFR 5827;
BA_ "SPN" SG_ 2566756606 Aftrtrtmnt1AvrgTmBtwnActvRgnrtns 5454;
BA_ "SigType" SG_ 2566756606 Aftrtrtmnt1DslPrtcltFltrTtlN3728 1;
BA_ "SPN" SG_ 2566756606 Aftrtrtmnt1DslPrtcltFltrTtlN3728 3728;
BA_ "SigType" SG_ 2566756606 Aftrtrtmnt1DslPrtcltFltrTtlN3727 1;
BA_ "SPN" SG_ 2566756606 Aftrtrtmnt1DslPrtcltFltrTtlN3727 3727;
BA_ "SigType" SG_ 2566756606 Aftrtrtmnt1DslPrtcltFltrTtlNmbrO 1;
BA_ "SPN" SG_ 2566756606 Aftrtrtmnt1DslPrtcltFltrTtlNmbrO 3726;
BA_ "SigType" SG_ 2566756606 Aftrtrtmnt1DslPrtcltFltrTtlPssvR 1;
BA_ "SPN" SG_ 2566756606 Aftrtrtmnt1DslPrtcltFltrTtlPssvR 3725;
BA_ "SPN" SG_ 2566756606 Aftrtrtmnt1TtlNmbrOfActvRgnrtons 3525;
BA_ "SigType" SG_ 2566756606 Aftertreatment1TotalDisabledTime 1;
BA_ "SPN" SG_ 2566756606 Aftertreatment1TotalDisabledTime 3524;
BA_ "SigType" SG_ 2566756606 Aftrtrtmnt1TotalRegenerationTime 1;
BA_ "SPN" SG_ 2566756606 Aftrtrtmnt1TotalRegenerationTime 3523;
BA_ "SigType" SG_ 2566756606 Aftertreatment1TotalFuelUsed 1;
BA_ "SPN" SG_ 2566756606 Aftertreatment1TotalFuelUsed 3522;
BA_ "SPN" SG_ 2565869310 Aftrtrtmnt1IntkOxygnSnsrPrlmnryF 3225;
BA_ "SPN" SG_ 2565869310 NOxSensorATO1SelfdiagnosisStatus 5713;
BA_ "SPN" SG_ 2565869310 Aftrtrtmnt1IntkNOxSnsrPrlmnryFMI 3224;
BA_ "SPN" SG_ 2565869310 Aftrtrtmnt1IntkGsSnsorHeaterCtrl 3223;
BA_ "SPN" SG_ 2565869310 Aftrtrtmnt1IntkGsSnsrHtrPrlmnryF 3222;
BA_ "SigType" SG_ 2565869310 Aftrtrtmnt1IntkWdRngO2RdngStable 5;
BA_ "SPN" SG_ 2565869310 Aftrtrtmnt1IntkWdRngO2RdngStable 3221;
BA_ "SigType" SG_ 2565869310 Aftrtrtmnt1IntkeNOxReadingStable 5;
BA_ "SPN" SG_ 2565869310 Aftrtrtmnt1IntkeNOxReadingStable 3220;
BA_ "SPN" SG_ 2565869310 Aftrtrtmnt1IntakeGasSensorAtTemp 3219;
BA_ "SigType" SG_ 2565869310 Aftrtrtmnt1IntkGsSnsrPowerStatus 5;
BA_ "SPN" SG_ 2565869310 Aftrtrtmnt1IntkGsSnsrPowerStatus 3218;
BA_ "SigType" SG_ 2565869310 Aftertreatment1IntakeO2 1;
BA_ "SPN" SG_ 2565869310 Aftertreatment1IntakeO2 3217;
BA_ "SigType" SG_ 2565869310 Aftertreatment1IntakeNOx 1;
BA_ "SPN" SG_ 2565869310 Aftertreatment1IntakeNOx 3216;
BA_ "SPN" SG_ 2566763774 Aftrtrtmnt1DslPrtcltFltrIntk3244 3244;
BA_ "SPN" SG_ 2566763774 Aftrtrtmnt1ExhstGsTmp1PrlmnryFMI 3243;
BA_ "SigType" SG_ 2566763774 Aftrtrtmnt1DslPrtcltFltrIntkGsTm 1;
BA_ "SPN" SG_ 2566763774 Aftrtrtmnt1DslPrtcltFltrIntkGsTm 3242;
BA_ "SigType" SG_ 2566763774 Aftertreatment1ExhaustGasTemp1 1;
BA_ "SPN" SG_ 2566763774 Aftertreatment1ExhaustGasTemp1 3241;
BA_ "SPN" SG_ 2631728894 AntitheftRandomNumber 1198;
BA_ "SigType" SG_ 2631728894 AntitheftModifyPwdStates 5;
BA_ "SPN" SG_ 2631728894 AntitheftModifyPwdStates 1197;
BA_ "SigType" SG_ 2631728894 AntitheftComponentStatusStates 5;
BA_ "SPN" SG_ 2631728894 AntitheftComponentStatusStates 1196;
BA_ "SigType" SG_ 2631728894 AntitheftPwdValidIndicator 5;
BA_ "SPN" SG_ 2631728894 AntitheftPwdValidIndicator 1195;
BA_ "SigType" SG_ 2631728894 AntthftEncryptnSdPrsentIndicator 5;
BA_ "SPN" SG_ 2631728894 AntthftEncryptnSdPrsentIndicator 1194;
BA_ "SPN" SG_ 2631794430 AntitheftPwdRepresentation 1202;
BA_ "SPN" SG_ 2631794430 AntitheftCmdStates 1201;
BA_ "SigType" SG_ 2631794430 AntitheftDesiredExitModeStates 5;
BA_ "SPN" SG_ 2631794430 AntitheftDesiredExitModeStates 1200;
BA_ "SigType" SG_ 2631794430 AntthftEncryptionIndicatorStates 5;
BA_ "SPN" SG_ 2631794430 AntthftEncryptionIndicatorStates 1199;
BA_ "SigType" SG_ 2633934846 EngAltWinding3Temp 1;
BA_ "SPN" SG_ 2633934846 EngAltWinding3Temp 1126;
BA_ "SigType" SG_ 2633934846 EngAltWinding2Temp 1;
BA_ "SPN" SG_ 2633934846 EngAltWinding2Temp 1125;
BA_ "SigType" SG_ 2633934846 EngAltWinding1Temp 1;
BA_ "SPN" SG_ 2633934846 EngAltWinding1Temp 1124;
BA_ "SigType" SG_ 2633934846 EngAltBearing2Temp 1;
BA_ "SPN" SG_ 2633934846 EngAltBearing2Temp 1123;
BA_ "SigType" SG_ 2633934846 EngAltBearing1Temp 1;
BA_ "SPN" SG_ 2633934846 EngAltBearing1Temp 1122;
BA_ "SPN" SG_ 2362572542 LevelPresetRearAxleRight 1735;
BA_ "SPN" SG_ 2362572542 LevelPresetRearAxleLeft 1758;
BA_ "SPN" SG_ 2362572542 LevelPresetFrontAxleRight 1757;
BA_ "SPN" SG_ 2362572542 LevelPresetFrontAxleLeft 1732;
BA_ "SigType" SG_ 2365478910 ElctrncShckAbsrbrCtrlMdLft_TgAxl 4;
BA_ "SPN" SG_ 2365478910 ElctrncShckAbsrbrCtrlMdLft_TgAxl 1831;
BA_ "SigType" SG_ 2365478910 ElctrncShckAbsrbrCtrlMdeRearAxle 4;
BA_ "SPN" SG_ 2365478910 ElctrncShckAbsrbrCtrlMdeRearAxle 1832;
BA_ "SigType" SG_ 2365478910 ElctrncShckAbsrbrCtrlMdFrontAxle 4;
BA_ "SPN" SG_ 2365478910 ElctrncShckAbsrbrCtrlMdFrontAxle 1833;
BA_ "SPN" SG_ 2365478910 DamperStiffnessLift_TagAxle 1731;
BA_ "SPN" SG_ 2365478910 DamperStiffnessRearAxle 1730;
BA_ "SPN" SG_ 2365478910 DamperStiffnessFrontAxle 1729;
BA_ "SigType" SG_ 2560950014 TestLimitMinimum 1;
BA_ "SPN" SG_ 2560950014 TestLimitMinimum 4112;
BA_ "SigType" SG_ 2560950014 TestLimitMaximum 1;
BA_ "SPN" SG_ 2560950014 TestLimitMaximum 4111;
BA_ "SigType" SG_ 2560950014 TestValue 1;
BA_ "SPN" SG_ 2560950014 TestValue 4110;
BA_ "SigType" SG_ 2560950014 SlotId 1;
BA_ "SPN" SG_ 2560950014 SlotId 4109;
BA_ "SPN" SG_ 2560950014 FailureModeIdentifier1 1215;
BA_ "SPN" SG_ 2560950014 SPN1 1214;
BA_ "SPN" SG_ 2566763262 Aftrtrtmnt1DslPrtcltFltrIntr3254 3254;
BA_ "SPN" SG_ 2566763262 Aftrtrtmnt1DslPrtcltFltrDltPrssP 3253;
BA_ "SPN" SG_ 2566763262 Aftrtrtmnt1ExhstGsTmp2PrlmnryFMI 3252;
BA_ "SigType" SG_ 2566763262 Aftrtrtmnt1DslPrtcltFltrDffPress 1;
BA_ "SPN" SG_ 2566763262 Aftrtrtmnt1DslPrtcltFltrDffPress 3251;
BA_ "SigType" SG_ 2566763262 Aftrtrtmnt1DslPrtcltFltrIntrmdtG 1;
BA_ "SPN" SG_ 2566763262 Aftrtrtmnt1DslPrtcltFltrIntrmdtG 3250;
BA_ "SigType" SG_ 2566763262 Aftertreatment1ExhaustGasTemp2 1;
BA_ "SPN" SG_ 2566763262 Aftertreatment1ExhaustGasTemp2 3249;
BA_ "SPN" SG_ 2565869566 Aftrtrtmnt1OtltOxygnSnsrPrlmnryF 3235;
BA_ "SPN" SG_ 2565869566 NOxSensorATI1SelfdiagnosisStatus 5714;
BA_ "SPN" SG_ 2565869566 Aftrtrtmnt1OtltNOxSnsrPrlmnryFMI 3234;
BA_ "SPN" SG_ 2565869566 Aftrtrtmnt1OtltGsSnsorHeaterCtrl 3233;
BA_ "SPN" SG_ 2565869566 Aftrtrtmnt1OtltGsSnsrHtrPrlmnryF 3232;
BA_ "SigType" SG_ 2565869566 Aftrtrtmnt1OtltWdRngO2RdngStable 5;
BA_ "SPN" SG_ 2565869566 Aftrtrtmnt1OtltWdRngO2RdngStable 3231;
BA_ "SigType" SG_ 2565869566 Aftrtrtmnt1OtletNOxReadingStable 5;
BA_ "SPN" SG_ 2565869566 Aftrtrtmnt1OtletNOxReadingStable 3230;
BA_ "SigType" SG_ 2565869566 Aftrtrtmnt1OutletGasSensorAtTemp 5;
BA_ "SPN" SG_ 2565869566 Aftrtrtmnt1OutletGasSensorAtTemp 3229;
BA_ "SigType" SG_ 2565869566 Aftrtrtmnt1OtltGsSnsrPowerStatus 5;
BA_ "SPN" SG_ 2565869566 Aftrtrtmnt1OtltGsSnsrPowerStatus 3228;
BA_ "SigType" SG_ 2565869566 Aftertreatment1OutletO2 1;
BA_ "SPN" SG_ 2565869566 Aftertreatment1OutletO2 3227;
BA_ "SigType" SG_ 2565869566 Aftertreatment1OutletNOx 1;
BA_ "SPN" SG_ 2565869566 Aftertreatment1OutletNOx 3226;
BA_ "SPN" SG_ 2566763518 Aftrtrtmnt1DslPrtcltFltrOtltExhs 3248;
BA_ "SPN" SG_ 2566763518 Aftrtrtmnt1ExhstGsTmp3PrlmnryFMI 3247;
BA_ "SigType" SG_ 2566763518 Aftrtrtmnt1DslPrtcltFltrOtltGsTm 1;
BA_ "SPN" SG_ 2566763518 Aftrtrtmnt1DslPrtcltFltrOtltGsTm 3246;
BA_ "SigType" SG_ 2566763518 Aftertreatment1ExhaustGasTemp3 1;
BA_ "SPN" SG_ 2566763518 Aftertreatment1ExhaustGasTemp3 3245;
BA_ "SPN" SG_ 2566749182 Aftrtrtmnt1DslPrtcltFltrStLdRgnr 5466;
BA_ "SigType" SG_ 2566749182 DslPrtcltFltr1TmSncLstActvRgnrtn 1;
BA_ "SPN" SG_ 2566749182 DslPrtcltFltr1TmSncLstActvRgnrtn 3721;
BA_ "SigType" SG_ 2566749182 DslPrtclateFilter1AshLoadPercent 1;
BA_ "SPN" SG_ 2566749182 DslPrtclateFilter1AshLoadPercent 3720;
BA_ "SigType" SG_ 2566749182 DslPrtclteFilter1SootLoadPercent 1;
BA_ "SPN" SG_ 2566749182 DslPrtclteFilter1SootLoadPercent 3719;
BA_ "SigType" SG_ 2566748670 Aftrtrtmnt1DslPrtcltFltrTrpN3740 1;
BA_ "SPN" SG_ 2566748670 Aftrtrtmnt1DslPrtcltFltrTrpN3740 3740;
BA_ "SigType" SG_ 2566748670 Aftrtrtmnt1DslPrtcltFltrTrpN3739 1;
BA_ "SPN" SG_ 2566748670 Aftrtrtmnt1DslPrtcltFltrTrpN3739 3739;
BA_ "SigType" SG_ 2566748670 Aftrtrtmnt1DslPrtcltFltrTrpN3738 1;
BA_ "SPN" SG_ 2566748670 Aftrtrtmnt1DslPrtcltFltrTrpN3738 3738;
BA_ "SigType" SG_ 2566748670 Aftrtrtmnt1DslPrtcltFltrTrpPssvR 1;
BA_ "SPN" SG_ 2566748670 Aftrtrtmnt1DslPrtcltFltrTrpPssvR 3737;
BA_ "SigType" SG_ 2566748670 Aftrtrtmnt1DslPrtcltFltrTrpNmbrO 1;
BA_ "SPN" SG_ 2566748670 Aftrtrtmnt1DslPrtcltFltrTrpNmbrO 3736;
BA_ "SigType" SG_ 2566748670 Aftrtrtmnt1DslPrtcltFltrTrpDsbld 1;
BA_ "SPN" SG_ 2566748670 Aftrtrtmnt1DslPrtcltFltrTrpDsbld 3735;
BA_ "SigType" SG_ 2566748670 Aftrtrtmnt1DslPrtcltFltrTrpActvR 1;
BA_ "SPN" SG_ 2566748670 Aftrtrtmnt1DslPrtcltFltrTrpActvR 3734;
BA_ "SigType" SG_ 2566748670 Aftrtrtmnt1DslPrtcltFltrTrpFlUsd 1;
BA_ "SPN" SG_ 2566748670 Aftrtrtmnt1DslPrtcltFltrTrpFlUsd 3733;
BA_ "SigType" SG_ 2566758142 Aftertreatment2AirEnableActuator 5;
BA_ "SPN" SG_ 2566758142 Aftertreatment2AirEnableActuator 3503;
BA_ "SigType" SG_ 2566758142 Aftertreatment2PurgeAirActuator 5;
BA_ "SPN" SG_ 2566758142 Aftertreatment2PurgeAirActuator 3504;
BA_ "SigType" SG_ 2566758142 Aftrtrtmnt2AtmizationAirActuator 5;
BA_ "SPN" SG_ 2566758142 Aftrtrtmnt2AtmizationAirActuator 3505;
BA_ "SigType" SG_ 2566758142 Aftertreatment2AirSystemRelay 5;
BA_ "SPN" SG_ 2566758142 Aftertreatment2AirSystemRelay 3506;
BA_ "SigType" SG_ 2566758142 Aftrtratment2AirPressActuatorPos 1;
BA_ "SPN" SG_ 2566758142 Aftrtratment2AirPressActuatorPos 3502;
BA_ "SigType" SG_ 2566758142 Aftertreatment2AirPressCtrl 1;
BA_ "SPN" SG_ 2566758142 Aftertreatment2AirPressCtrl 3501;
BA_ "SigType" SG_ 2566758142 Aftertreatment2PurgeAirPress 1;
BA_ "SPN" SG_ 2566758142 Aftertreatment2PurgeAirPress 3500;
BA_ "SigType" SG_ 2566758142 Aftertreatment2SupplyAirPress 1;
BA_ "SPN" SG_ 2566758142 Aftertreatment2SupplyAirPress 3499;
BA_ "SigType" SG_ 2566745342 Aftertreatment2SecondAirPress 1;
BA_ "SPN" SG_ 2566745342 Aftertreatment2SecondAirPress 3838;
BA_ "SigType" SG_ 2566745342 Aftertreatment2SecondAirMassFlow 1;
BA_ "SPN" SG_ 2566745342 Aftertreatment2SecondAirMassFlow 3835;
BA_ "SigType" SG_ 2566745342 Aftertreatment2SecondAirTemp 1;
BA_ "SPN" SG_ 2566745342 Aftertreatment2SecondAirTemp 3834;
BA_ "SigType" SG_ 2566745342 Aftrtreatment2SecondAirDiffPress 1;
BA_ "SPN" SG_ 2566745342 Aftrtreatment2SecondAirDiffPress 3833;
BA_ "SPN" SG_ 2566758654 Aftrtrtmnt2FlInjector1HeaterCtrl 4302;
BA_ "SigType" SG_ 2566758654 Aftrtreatment2FuelEnableActuator 5;
BA_ "SPN" SG_ 2566758654 Aftrtreatment2FuelEnableActuator 3496;
BA_ "SigType" SG_ 2566758654 Aftrtreatment2RegenerationStatus 5;
BA_ "SPN" SG_ 2566758654 Aftrtreatment2RegenerationStatus 3497;
BA_ "SigType" SG_ 2566758654 Aftertreatment2Ignt 5;
BA_ "SPN" SG_ 2566758654 Aftertreatment2Ignt 3498;
BA_ "SigType" SG_ 2566758654 Aftertreatment2FuelDrainActuator 5;
BA_ "SPN" SG_ 2566758654 Aftertreatment2FuelDrainActuator 4098;
BA_ "SPN" SG_ 2566758654 Aftertreatment2FuelPress1Ctrl 3493;
BA_ "SigType" SG_ 2566758654 Aftertreatment2FuelRate 1;
BA_ "SPN" SG_ 2566758654 Aftertreatment2FuelRate 3495;
BA_ "SigType" SG_ 2566758654 Aftertreatment2FuelPress1 1;
BA_ "SPN" SG_ 2566758654 Aftertreatment2FuelPress1 3494;
BA_ "SigType" SG_ 2566753278 DslParticulateFilterOutletPress2 1;
BA_ "SPN" SG_ 2566753278 DslParticulateFilterOutletPress2 3612;
BA_ "SigType" SG_ 2566753278 DslParticulateFilterIntakePress2 1;
BA_ "SPN" SG_ 2566753278 DslParticulateFilterIntakePress2 3611;
BA_ "SPN" SG_ 2566756862 Aftrtrtmnt2AvrgDstncBtwnActvDPFR 5828;
BA_ "SPN" SG_ 2566756862 Aftrtrtmnt2AvrgTmBtwnActvRgnrtns 5455;
BA_ "SigType" SG_ 2566756862 Aftrtrtmnt2DslPrtcltFltrTtlN3732 1;
BA_ "SPN" SG_ 2566756862 Aftrtrtmnt2DslPrtcltFltrTtlN3732 3732;
BA_ "SigType" SG_ 2566756862 Aftrtrtmnt2DslPrtcltFltrTtlN3731 1;
BA_ "SPN" SG_ 2566756862 Aftrtrtmnt2DslPrtcltFltrTtlN3731 3731;
BA_ "SigType" SG_ 2566756862 Aftrtrtmnt2DslPrtcltFltrTtlNmbrO 1;
BA_ "SPN" SG_ 2566756862 Aftrtrtmnt2DslPrtcltFltrTtlNmbrO 3730;
BA_ "SigType" SG_ 2566756862 Aftrtrtmnt2DslPrtcltFltrTtlPssvR 1;
BA_ "SPN" SG_ 2566756862 Aftrtrtmnt2DslPrtcltFltrTtlPssvR 3729;
BA_ "SigType" SG_ 2566756862 Aftrtrtmnt2TtlNmbrOfActvRgnrtons 1;
BA_ "SPN" SG_ 2566756862 Aftrtrtmnt2TtlNmbrOfActvRgnrtons 3529;
BA_ "SPN" SG_ 2566756862 Aftertreatment2TotalDisabledTime 3528;
BA_ "SPN" SG_ 2566756862 Aftrtrtmnt2TotalRegenerationTime 3527;
BA_ "SPN" SG_ 2566756862 Aftertreatment2TotalFuelUsed 3526;
VAL_ 2566711806 Armrest2Switch2 3 "Dont care/take no action" 2 "Reserved" 1 "On" 0 "Off" ;
VAL_ 2566711806 Armrest2Switch1 3 "Dont care/take no action" 2 "Reserved" 1 "On" 0 "Off" ;
VAL_ 2566711806 Armrest1Switch2 3 "Dont care/take no action" 2 "Reserved" 1 "On" 0 "Off" ;
VAL_ 2566711806 Armrest1Switch1 3 "Dont care/take no action" 2 "Reserved" 1 "On" 0 "Off" ;
VAL_ 2364549886 YawRateExRangeFigureOfMerit 3 "Not available" 2 "Error" 1 "Yaw rate degraded Data is suspect due to environmental conditions" 0 "Yaw rate fully functional Data is within sensor specification" ;
VAL_ 2364549886 RollRateExRangeFigureOfMerit 3 "Not available" 2 "Error" 1 "Roll rate degraded Data is suspect due to environmental conditions" 0 "Roll rate fully functional Data is within sensor specification" ;
VAL_ 2364549886 PitchRateExRangeFigureOfMerit 3 "Not available" 2 "Error" 1 "Pitch rate degraded Data is suspect due to environmental conditions" 0 "Pitch rate fully functional Data is within sensor specification" ;
VAL_ 2566712318 Aftrtrtmnt2NOxAdsrbrDSOxRgnrtnSt 3 "Not available" 2 "Error indicator" 1 "Active" 0 "Inactive" ;
VAL_ 2566712318 Aftrtrtmnt2NOxAdsrbrDNOxRgnrtnSt 3 "Not available" 2 "Error indicator" 1 "Active" 0 "Inactive" ;
VAL_ 2566712574 Aftrtrtmnt1NOxAdsrbrDSOxRgnrtnSt 3 "Not available" 2 "Error indicator" 1 "Active" 0 "Inactive" ;
VAL_ 2566712574 Aftrtrtmnt1NOxAdsrbrDNOxRgnrtnSt 3 "Not available" 2 "Error indicator" 1 "Active" 0 "Inactive" ;
VAL_ 2566730750 Aftrtrtmnt2DslExhstFlidPumpState 3 "not available" 2 "reserved for SAE assignment" 1 "pump error" 0 "pump operational" ;
VAL_ 2566731518 Aftrtrtmnt2DeselExhaustFluidType 15 "Not available" 14 "Error detected with urea reagent type detection" 13 "Not able to determine catalyst reagent type type unknown" 5 "to 1100  Reserved for SAE assignment" 3 "Catalyst reagent is proper mixture" 2 "Catalyst reagent is diesel" 1 "Catalyst reagent is urea concentration too low" 0 "Catalyst reagent is urea concentration too high" ;
VAL_ 2164079358 Aftrtrtmnt2DslExhstFldLneHeater4 3 "not available" 2 "reserved for future assignment by SAE" 1 "request for heater to be active" 0 "request for heater to be inactive" ;
VAL_ 2164079358 Aftrtrtmnt2DslExhstFldLneHeater3 3 "not available" 2 "reserved for future assignment by SAE" 1 "request for heater to be active" 0 "request for heater to be inactive" ;
VAL_ 2164079358 Aftrtrtmnt2DslExhstFldLneHeater2 3 "not available" 2 "reserved for future assignment by SAE" 1 "request for heater to be active" 0 "request for heater to be inactive" ;
VAL_ 2164079358 Aftrtrtmnt2DslExhstFldLneHeater1 3 "not available" 2 "reserved for future assignment by SAE" 1 "request for heater to be active" 0 "request for heater to be inactive" ;
VAL_ 2164079358 Aftrtrtmnt2DslExhstFldDsrHtngMdR 7 "Not available" 4 "110 Reserved" 3 "Heater on" 2 "Heater automatic mode" 1 "Heater economy mode" 0 "Heater off" ;
VAL_ 2164079358 Aftrtrtmnt2DslExhstFldDsrFltSppr 3 "Not available" 2 "Reserved" 1 "Error suppression on" 0 "Error suppression off" ;
VAL_ 2364549118 Aftrtrtmnt2SCRSystmRquestedState 15 "Not available" 14 "Error" 10 "Service test mode dosing not allowed" 9 "Service test mode dosing allowed" 8 "Diagnosis afterrun" 7 "Shutoff wait for afterrun" 6 "Protect mode against cold defreeze" 5 "Protect mode against heat pressure buildup" 4 "Reserved for future assignment by SAE" 3 "System error pending" 2 "Normal dosing operation" 1 "Preparing dosing readiness wake up prepare to operate wait for start" 0 "Dormant sleep mode" ;
VAL_ 2566732798 Aftrtrtmnt2DslExhstFldLnHtr4Stte 3 "not available" 2 "error" 1 "heater active" 0 "heater inactive" ;
VAL_ 2566732798 Aftrtrtmnt2DslExhstFldLnHtr3Stte 3 "not available" 2 "error" 1 "heater active" 0 "heater inactive" ;
VAL_ 2566732798 Aftrtrtmnt2DslExhstFldLnHtr2Stte 3 "not available" 2 "error" 1 "heater active" 0 "heater inactive" ;
VAL_ 2566732798 Aftrtrtmnt2DslExhstFldLnHtr1Stte 3 "not available" 2 "error" 1 "heater active" 0 "heater inactive" ;
VAL_ 2566732798 Aftrtrtmnt2SCRFeedbackCtrlStatus 4 "reserved for future assignment by SAE" 3 "reserved for future assignment by SAE" 2 "reserved for future assignment by SAE" 7 "not available" 6 "error" 5 "reserved for future assignment by SAE" 1 "closed loop control active" 0 "open loop control active" ;
VAL_ 2566732798 Aftrtrtmnt2SCRDsngVlvExhstTmpRdc 7 "11    not available" 6 "10    error" 5 "01    reserved for future assignment by SAE" 4 "00    reserved for future assignment by SAE" 3 "11    reserved for future assignment by SAE" 2 "10    reduction request stage 2" 1 "01    reduction request stage 1" 0 "00    no request" ;
VAL_ 2364548862 Aftertreatment2SCRSystemState 15 "Not available" 14 "Error" 10 "Service test mode dosing not allowed" 9 "Service test mode dosing allowed" 8 "Diagnosis afterrun" 7 "Shutoff wait for afterrun" 6 "Protect mode against cold defreeze" 5 "Protect mode against heat pressure buildup" 4 "Reserved for future assignment by SAE" 3 "System error pending" 2 "Normal dosing operation" 1 "Preparing dosing readiness wake up prepare to operate wait for start" 0 "Dormant sleep mode" ;
VAL_ 2364549374 Aftrtrtmnt2OtltNH3GsSnsrHterCtrl 3 "Heater off or Not available" 2 "Preheat 1" 1 "Preheat 2" 0 "Automatic" ;
VAL_ 2364549374 Aftrtrtmnt2OtltNH3GsSensorAtTemp 3 "Not available" 2 "Error" 1 "Heater element is in range" 0 "Heater element is not in range" ;
VAL_ 2364549374 Aftrtrtmnt2OtltNH3GsSnsrPwrInRng 3 "Not available" 2 "Error" 1 "Heater element is in range" 0 "Heater element is not in range" ;
VAL_ 2364549374 Aftrtrtmnt2OtletNH3ReadingStable 3 "Not available" 2 "Error" 1 "Reading is stable" 0 "Reading is not stable" ;
VAL_ 2566733054 Aftrtrtmnt1DslExhstFlidPumpState 3 "not available" 2 "reserved for SAE assignment" 1 "pump error" 0 "pump operational" ;
VAL_ 2566734078 Aftrtrtmnt1DslExhstFldLneHeater4 3 "not available" 2 "reserved for future assignment by SAE" 1 "request for heater to be active" 0 "request for heater to be inactive" ;
VAL_ 2566734078 Aftrtrtmnt1DslExhstFldLneHeater3 3 "not available" 2 "reserved for future assignment by SAE" 1 "request for heater to be active" 0 "request for heater to be inactive" ;
VAL_ 2566734078 Aftrtrtmnt1DslExhstFldLneHeater2 3 "not available" 2 "reserved for future assignment by SAE" 1 "request for heater to be active" 0 "request for heater to be inactive" ;
VAL_ 2566734078 Aftrtrtmnt1DslExhstFldLneHeater1 3 "not available" 2 "reserved for future assignment by SAE" 1 "request for heater to be active" 0 "request for heater to be inactive" ;
VAL_ 2566734078 Aftrtrtmnt1DslExhstFldDsrHtngMdR 7 "Not available" 4 "110 Reserved" 3 "Heater on" 2 "Heater automatic mode" 1 "Heater economy mode" 0 "Heater off" ;
VAL_ 2566734078 Aftrtrtmnt1DslExhstFldDsrFltSppr 3 "Not available" 2 "Reserved" 1 "Error suppression on" 0 "Error suppression off" ;
VAL_ 2364548350 Aftrtrtmnt1SCRSystmRquestedState 15 "Not available" 14 "Error" 10 "Service test mode dosing not allowed" 9 "Service test mode dosing allowed" 8 "Diagnosis afterrun" 7 "Shutoff wait for afterrun" 6 "Protect mode against cold defreeze" 5 "Protect mode against heat pressure buildup" 4 "Reserved for future assignment by SAE" 3 "System error pending" 2 "Normal dosing operation" 1 "Preparing dosing readiness wake up prepare to operate wait for start" 0 "Dormant sleep mode" ;
VAL_ 2566734334 Aftrtrtmnt1DslExhstFldLnHtr4Stte 3 "not available" 2 "error" 1 "heater active" 0 "heater inactive" ;
VAL_ 2566734334 Aftrtrtmnt1DslExhstFldLnHtr3Stte 3 "not available" 2 "error" 1 "heater active" 0 "heater inactive" ;
VAL_ 2566734334 Aftrtrtmnt1DslExhstFldLnHtr2Stte 3 "not available" 2 "error" 1 "heater active" 0 "heater inactive" ;
VAL_ 2566734334 Aftrtrtmnt1DslExhstFldLnHtr1Stte 3 "not available" 2 "error" 1 "heater active" 0 "heater inactive" ;
VAL_ 2566734334 Aftrtrtmnt1SCRFeedbackCtrlStatus 7 "not available" 4 "reserved for future assignment by SAE" 3 "reserved for future assignment by SAE" 2 "reserved for future assignment by SAE" 6 "error" 5 "reserved for future assignment by SAE" 1 "closed loop control active" 0 "open loop control active" ;
VAL_ 2566734334 Aftrtrtmnt1SCRDsngVlvExhstTmpRdc 7 "11    not available" 6 "10    error" 5 "01    reserved for future assignment by SAE" 4 "00    reserved for future assignment by SAE" 3 "11    reserved for future assignment by SAE" 2 "10    reduction request stage 2" 1 "01    reduction request stage 1" 0 "00    no request" ;
VAL_ 2364548094 Aftertreatment1SCRSystemState 15 "Not available" 14 "Error" 10 "Service test mode dosing not allowed" 9 "Service test mode dosing allowed" 8 "Diagnosis afterrun" 7 "Shutoff wait for afterrun" 6 "Protect mode against cold defreeze" 5 "Protect mode against heat pressure buildup" 4 "Reserved for future assignment by SAE" 3 "System error pending" 2 "Normal dosing operation" 1 "Preparing dosing readiness wake up prepare to operate wait for start" 0 "Dormant sleep mode" ;
VAL_ 2364548606 Aftrtrtmnt1OtltNH3GsSnsrHterCtrl 3 "Heater off or not available" 2 "Preheat 1" 1 "Preheat 2" 0 "Automatic" ;
VAL_ 2364548606 Aftrtrtmnt1OtltNH3GsSensorAtTemp 3 "Not available" 2 "Error" 1 "Heater element is in range" 0 "Heater element is not in range" ;
VAL_ 2364548606 Aftrtrtmnt1OtltNH3GsSnsrPwrInRng 3 "Not available" 2 "Error" 1 "Power is in range" 0 "Power is not in range" ;
VAL_ 2364548606 Aftrtrtmnt1OtletNH3ReadingStable 3 "Not available" 2 "Error" 1 "Reading is stable" 0 "Reading is not stable" ;
VAL_ 2566742270 FailureModeIdentifier1 31 "Not available" 19 "Received network data in error" 18 "Below normal (moderately severe)" 17 "Below normal (least severe)" 16 "Above normal (moderately severe)" 15 "Above normal (least severe)" 14 "Special intstructions" 13 "Out of calibration" 12 "Bad intelligent device" 11 "Root cause not known" 10 "Abnormal rate of change" 9 "Abnormal update rate" 8 "Abnormal frequency" 7 "Mechanical system not responding" 6 "Current above normal" 5 "Current below normal" 4 "Voltage below normal" 3 "Voltage above normal" 2 "Data erratic" 1 "Below normal (most severe)" 0 "Above normal (most severe)" ;
VAL_ 2560687870 PMNTEDeficiencyAreaStatus 3 "NotAvailable" 2 "Reserved" 1 "InsideControlArea" 0 "OutsideControlArea" ;
VAL_ 2560687870 MnfcPMNTECarveOutAreaStatus 3 "NotAvailable" 2 "Reserved" 1 "InsideControlArea" 0 "OutsideControlArea" ;
VAL_ 2560687870 PMNTEControlAreaStatus 3 "NotAvailable" 2 "Reserved" 1 "InsideControlArea" 0 "OutsideControlArea" ;
VAL_ 2560687870 NOxNTEDeficiencyAreaStatus 3 "NotAvailable" 2 "Reserved" 1 "InsideControlArea" 0 "OutsideControlArea" ;
VAL_ 2560687870 MnfcNOxNTECarveOutAreaStatus 3 "NotAvailable" 2 "Reserved" 1 "InsideControlArea" 0 "OutsideControlArea" ;
VAL_ 2560687870 NOxNTEControlAreaStatus 3 "NotAvailable" 2 "Reserved" 1 "InsideControlArea" 0 "OutsideControlArea" ;
VAL_ 2566809342 BatteryMainSwitchHoldState 3 "Dont care/take no action" 2 "Reserved" 1 "Battery main switch held" 0 "Battery main switch not held" ;
VAL_ 2365446910 Joystick3XAxisDetentPosStatus 3 "Not Available" 2 "Error Indicator" 1 "In the Detent Position" 0 "Not in the Detent Position" ;
VAL_ 2365446910 Joystick3Button9PressedStatus 3 "Not Available" 2 "Error Indicator" 1 "Button pressed" 0 "Button not pressed" ;
VAL_ 2365446910 Joystick3Button10PressedStatus 3 "Not Available" 2 "Error Indicator" 1 "Button pressed" 0 "Button not pressed" ;
VAL_ 2365446910 Joystick3Button11PressedStatus 3 "Not Available" 2 "Error Indicator" 1 "Button pressed" 0 "Button not pressed" ;
VAL_ 2365446910 Joystick3Button12PressedStatus 3 "Not Available" 2 "Error Indicator" 1 "Button pressed" 0 "Button not pressed" ;
VAL_ 2365446910 Joystick3YAxisDetentPosStatus 3 "Not Available" 2 "Error Indicator" 1 "In the Detent Position" 0 "Not in the Detent Position" ;
VAL_ 2365446910 Jystck3YAxsLvrFrwrdPstvPosStatus 3 "Not Available" 2 "Error Indicator" 1 "On positive side of Neutral" 0 "Not on Positive side of Neutral" ;
VAL_ 2365446910 Jystck3YAxsLvrBckNgtivePosStatus 3 "Not Available" 2 "Error Indicator" 1 "On negative side of Neutral" 0 "Not on negative side of Neutral" ;
VAL_ 2365446910 Joystick3YAxisNeutralPosStatus 3 "Not Available" 2 "Error Indicator" 1 "In Neutral Position" 0 "Not in Neutral Position" ;
VAL_ 2365446910 Jystck3XAxsLvrRghtPstvePosStatus 3 "Not Available" 2 "Error Indicator" 1 "On positive side of Neutral" 0 "Not on Positive side of Neutral" ;
VAL_ 2365446910 Jystck3XAxsLvrLftNgtivePosStatus 3 "Not Available" 2 "Error Indicator" 1 "On negative side of Neutral" 0 "Not on negative side of Neutral" ;
VAL_ 2365446910 Joystick3XAxisNeutralPosStatus 3 "Not Available" 2 "Error Indicator" 1 "In Neutral Position" 0 "Not in Neutral Position" ;
VAL_ 2365446910 Joystick3Button5PressedStatus 3 "Not Available" 2 "Error Indicator" 1 "Button pressed" 0 "Button not pressed" ;
VAL_ 2365446910 Joystick3Button6PressedStatus 3 "Not Available" 2 "Error Indicator" 1 "Button pressed" 0 "Button not pressed" ;
VAL_ 2365446910 Joystick3Button7PressedStatus 3 "Not Available" 2 "Error Indicator" 1 "Button pressed" 0 "Button not pressed" ;
VAL_ 2365446910 Joystick3Button8PressedStatus 3 "Not Available" 2 "Error Indicator" 1 "Button pressed" 0 "Button not pressed" ;
VAL_ 2365446910 Joystick3Button1PressedStatus 3 "Not Available" 2 "Error Indicator" 1 "Button pressed" 0 "Button not pressed" ;
VAL_ 2365446910 Joystick3Button2PressedStatus 3 "Not Available" 2 "Error Indicator" 1 "Button pressed" 0 "Button not pressed" ;
VAL_ 2365446910 Joystick3Button3PressedStatus 3 "Not Available" 2 "Error Indicator" 1 "Button pressed" 0 "Button not pressed" ;
VAL_ 2365446910 Joystick3Button4PressedStatus 3 "Not Available" 2 "Error Indicator" 1 "Button pressed" 0 "Button not pressed" ;
VAL_ 2365446398 Joystick2XAxisDetentPosStatus 3 "Not Available" 2 "Error Indicator" 1 "In the Detent Position" 0 "Not in the Detent Position" ;
VAL_ 2365446398 Joystick2YAxisDetentPosStatus 3 "Not Available" 2 "Error Indicator" 1 "In the Detent Position" 0 "Not in the Detent Position" ;
VAL_ 2365446398 Jystck2YAxsLvrFrwrdPstvPosStatus 3 "Not Available" 2 "Error Indicator" 1 "On positive side of Neutral" 0 "Not on Positive side of Neutral" ;
VAL_ 2365446398 Jystck2YAxsLvrBckNgtivePosStatus 3 "Not Available" 2 "Error Indicator" 1 "On negative side of Neutral" 0 "Not on negative side of Neutral" ;
VAL_ 2365446398 Joystick2YAxisNeutralPosStatus 3 "Not Available" 2 "Error Indicator" 1 "In Neutral Position" 0 "Not in Neutral Position" ;
VAL_ 2365446398 Jystck2XAxsLvrRghtPstvePosStatus 3 "Not Available" 2 "Error Indicator" 1 "On positive side of Neutral" 0 "Not on Positive side of Neutral" ;
VAL_ 2365446398 Jystck2XAxsLvrLftNgtivePosStatus 3 "Not Available" 2 "Error Indicator" 1 "On negative side of Neutral" 0 "Not on negative side of Neutral" ;
VAL_ 2365446398 Joystick2XAxisNeutralPosStatus 3 "Not Available" 2 "Error Indicator" 1 "In Neutral Position" 0 "Not in Neutral Position" ;
VAL_ 2365446398 Joystick2Button9PressedStatus 3 "Not Available" 2 "Error Indicator" 1 "Button pressed" 0 "Button not pressed" ;
VAL_ 2365446398 Joystick2Button10PressedStatus 3 "Not Available" 2 "Error Indicator" 1 "Button pressed" 0 "Button not pressed" ;
VAL_ 2365446398 Joystick2Button11PressedStatus 3 "Not Available" 2 "Error Indicator" 1 "Button pressed" 0 "Button not pressed" ;
VAL_ 2365446398 Joystick2Button12PressedStatus 3 "Not Available" 2 "Error Indicator" 1 "Button pressed" 0 "Button not pressed" ;
VAL_ 2365446398 Joystick2Button5PressedStatus 3 "Not Available" 2 "Error Indicator" 1 "Button pressed" 0 "Button not pressed" ;
VAL_ 2365446398 Joystick2Button6PressedStatus 3 "Not Available" 2 "Error Indicator" 1 "Button pressed" 0 "Button not pressed" ;
VAL_ 2365446398 Joystick2Button7PressedStatus 3 "Not Available" 2 "Error Indicator" 1 "Button pressed" 0 "Button not pressed" ;
VAL_ 2365446398 Joystick2Button8PressedStatus 3 "Not Available" 2 "Error Indicator" 1 "Button pressed" 0 "Button not pressed" ;
VAL_ 2365446398 Joystick2Button1PressedStatus 3 "Not Available" 2 "Error Indicator" 1 "Button pressed" 0 "Button not pressed" ;
VAL_ 2365446398 Joystick2Button2PressedStatus 3 "Not Available" 2 "Error Indicator" 1 "Button pressed" 0 "Button not pressed" ;
VAL_ 2365446398 Joystick2Button3PressedStatus 3 "Not Available" 2 "Error Indicator" 1 "Button pressed" 0 "Button not pressed" ;
VAL_ 2365446398 Joystick2Button4PressedStatus 3 "Not Available" 2 "Error Indicator" 1 "Button pressed" 0 "Button not pressed" ;
VAL_ 2365445886 Joystick1XAxisDetentPosStatus 3 "Not Available" 2 "Error Indicator" 1 "In the Detent Position" 0 "Not in the Detent Position" ;
VAL_ 2365445886 Joystick1YAxisDetentPosStatus 3 "Not Available" 2 "Error Indicator" 1 "In the Detent Position" 0 "Not in the Detent Position" ;
VAL_ 2365445886 Jystck1YAxsLvrFrwrdPstvPosStatus 3 "Not Available" 2 "Error Indicator" 1 "On positive side of Neutral" 0 "Not on Positive side of Neutral" ;
VAL_ 2365445886 Jystck1YAxsLvrBckNgtivePosStatus 3 "Not Available" 2 "Error Indicator" 1 "On negative side of Neutral" 0 "Not on negative side of Neutral" ;
VAL_ 2365445886 Joystick1YAxisNeutralPosStatus 3 "Not Available" 2 "Error Indicator" 1 "In Neutral Position" 0 "Not in Neutral Position" ;
VAL_ 2365445886 Joystick1Button9PressedStatus 3 "Not Available" 2 "Error Indicator" 1 "Button pressed" 0 "Button not pressed" ;
VAL_ 2365445886 Joystick1Button10PressedStatus 3 "Not Available" 2 "Error Indicator" 1 "Button pressed" 0 "Button not pressed" ;
VAL_ 2365445886 Joystick1Button11PressedStatus 3 "Not Available" 2 "Error Indicator" 1 "Button pressed" 0 "Button not pressed" ;
VAL_ 2365445886 Joystick1Button12PressedStatus 3 "Not Available" 2 "Error Indicator" 1 "Button pressed" 0 "Button not pressed" ;
VAL_ 2365445886 Joystick1Button5PressedStatus 3 "Not Available" 2 "Error Indicator" 1 "Button pressed" 0 "Button not pressed" ;
VAL_ 2365445886 Joystick1Button6PressedStatus 3 "Not Available" 2 "Error Indicator" 1 "Button pressed" 0 "Button not pressed" ;
VAL_ 2365445886 Joystick1Button7PressedStatus 3 "Not Available" 2 "Error Indicator" 1 "Button pressed" 0 "Button not pressed" ;
VAL_ 2365445886 Joystick1Button8PressedStatus 3 "Not Available" 2 "Error Indicator" 1 "Button pressed" 0 "Button not pressed" ;
VAL_ 2365445886 Joystick1Button1PressedStatus 3 "Not Available" 2 "Error Indicator" 1 "Button pressed" 0 "Button not pressed" ;
VAL_ 2365445886 Joystick1Button2PressedStatus 3 "Not Available" 2 "Error Indicator" 1 "Button pressed" 0 "Button not pressed" ;
VAL_ 2365445886 Joystick1Button3PressedStatus 3 "Not Available" 2 "Error Indicator" 1 "Button pressed" 0 "Button not pressed" ;
VAL_ 2365445886 Joystick1Button4PressedStatus 3 "Not Available" 2 "Error Indicator" 1 "Button pressed" 0 "Button not pressed" ;
VAL_ 2365445886 Jystck1XAxsLvrRghtPstvePosStatus 3 "Not Available" 2 "Error Indicator" 1 "On positive side of Neutral" 0 "Not on Positive side of Neutral" ;
VAL_ 2365445886 Jystck1XAxsLvrLftNgtivePosStatus 3 "Not Available" 2 "Error Indicator" 1 "On negative side of Neutral" 0 "Not on negative side of Neutral" ;
VAL_ 2365445886 Joystick1XAxisNeutralPosStatus 3 "Not Available" 2 "Error Indicator" 1 "In Neutral Position" 0 "Not in Neutral Position" ;
VAL_ 2566847230 ParkingBrakeRedWarningSignal 3 "Take no action" 2 "Reserved" 1 "on" 0 "off" ;
VAL_ 2566847230 ParkBrakeReleaseInhibitStatus 3 "Unavailable" 2 "Error" 1 "ParkBrakeReleaseIsInhibited" 0 "ParkBrakeReleaseIsNotInhibited" ;
VAL_ 2566847230 ParkingBrakeActuator 3 "Not available" 2 "Error" 1 "Parking brake actuator active" 0 "Parking brake actuator inactive" ;
VAL_ 2560884478 DTCWarnLampSupportStatus 3 "Unavailable" 2 "Reserved" 1 "LampOn" 0 "LampOff" ;
VAL_ 2560884478 DTCWarnLampSupportFlash 3 "Unavailable" 2 "Reserved" 1 "FastFlash" 0 "SlowFlash" ;
VAL_ 2560884478 DTCStopLampSupportStatus 3 "Unavailable" 2 "Reserved" 1 "LampOn" 0 "LampOff" ;
VAL_ 2560884478 DTCStopLampSupportFlash 3 "Unavailable" 2 "Reserved" 1 "FastFlash" 0 "SlowFlash" ;
VAL_ 2560884478 DTCProtectLampSupportStatus 3 "Unavailable" 2 "Reserved" 1 "LampOn" 0 "LampOff" ;
VAL_ 2560884478 DTCProtectLampSupportFlash 3 "Unavailable" 2 "Reserved" 1 "FastFlash" 0 "SlowFlash" ;
VAL_ 2560884478 DTCMilSupportStatus 3 "Unavailable" 2 "ShortMI" 1 "LampOn" 0 "LampOff" ;
VAL_ 2560884478 DTCMilSupportFlash 3 "Unavailable" 2 "Class_C_DTC" 1 "FastFlash" 0 "SlowFlash" ;
VAL_ 2566736126 EngExhstGsOxygnSnsrClsdLpOprtnBn 15 "not supported" 4 "Closed loop but fault with at least one oxygen sensor  may be using single oxygen sensor for fuel control" 3 "Open loop  due to detected system fault" 2 "Open loop due to driving conditions eg power enrichment deceleration enleanment" 1 "Closed loop  using oxygen sensors as feedback for fuel control" 0 "Open loop  has not yet satisfied conditions to go closed loop" ;
VAL_ 2566736382 EngExhstGsOxygnSnsrClsdLpOprtnBn 15 "not supported" 4 "Closed loop but fault with at least one oxygen sensor  may be using single oxygen sensor for fuel control" 3 "Open loop  due to detected system fault" 2 "Open loop due to driving conditions eg power enrichment deceleration enleanment" 1 "Closed loop  using oxygen sensors as feedback for fuel control" 0 "Open loop  has not yet satisfied conditions to go closed loop" ;
VAL_ 2565874174 EngSpdSensor1TimingPatternStatus 3 "Not available" 2 "Error" 1 "OK" 0 "Not OK" ;
VAL_ 2565874174 EngSpdSensor2TimingPatternStatus 3 "Not available" 2 "Error" 1 "OK" 0 "Not OK" ;
VAL_ 2565874174 EngSpdSensor3TimingPatternStatus 3 "Not available" 2 "Error" 1 "OK" 0 "Not OK" ;
VAL_ 2432520958 EngCoolantThermostatMode 3 "dont care/reserved" 2 "reserved" 1 "position control mode used for service only" 0 "temperature control mode" ;
VAL_ 2566758398 Aftertreatment1AirEnableActuator 3 "not available" 2 "reserved for SAE assignment" 1 "active" 0 "not active" ;
VAL_ 2566758398 Aftertreatment1PurgeAirActuator 3 "not available" 2 "reserved for SAE assignment" 1 "active" 0 "not active" ;
VAL_ 2566758398 Aftrtrtmnt1AtmizationAirActuator 3 "not available" 2 "reserved for SAE assignment" 1 "active" 0 "not active" ;
VAL_ 2566758398 Aftertreatment1AirSystemRelay 3 "not available" 2 "reserved for SAE assignment" 1 "active" 0 "not active" ;
VAL_ 2566758910 Aftrtreatment1FuelEnableActuator 3 "not available" 2 "reserved for SAE assignment" 1 "active" 0 "not active" ;
VAL_ 2566758910 Aftrtreatment1RegenerationStatus 3 "not available" 2 "reserved for SAE assignment" 1 "active" 0 "not active" ;
VAL_ 2566758910 Aftertreatment1Ignt 3 "not available" 2 "reserved for SAE assignment" 1 "active" 0 "not active" ;
VAL_ 2566758910 Aftertreatment1FuelDrainActuator 3 "not available" 2 "reserved for SAE assignment" 1 "active" 0 "not active" ;
VAL_ 2566743550 Aftrtrtmnt1FlFlwDverterValveCtrl 3 "not available" 2 "reserved for SAE assignment" 1 "on" 0 "off" ;
VAL_ 2566743550 Aftertreatment1FuelPumpRelayCtrl 3 "not available" 2 "reserved for SAE assignment" 1 "on" 0 "off" ;
VAL_ 2565869310 NOxSensorATO1SelfdiagnosisStatus 7 "Not Supported" 5 "110 Reserved" 4 "NOx Sensor ATO1 Self Diagnosis not possible" 3 "NOx Sensor ATO1 Self Diagnosis aborted" 2 "NOx Sensor ATO1 Self Diagnosis Result Complete" 1 "NOx Sensor ATO1 Self Diagnosis active flag" 0 "Diagnosis not active" ;
VAL_ 2565869310 Aftrtrtmnt1IntkGsSnsorHeaterCtrl 3 "Heater off" 2 "Preheat 1" 1 "Preheat 2" 0 "Automatic" ;
VAL_ 2565869310 Aftrtrtmnt1IntkWdRngO2RdngStable 3 "Not available" 2 "Error" 1 "Stable" 0 "Not stable" ;
VAL_ 2565869310 Aftrtrtmnt1IntkeNOxReadingStable 3 "Not available" 2 "Error" 1 "Stable" 0 "Not stable" ;
VAL_ 2565869310 Aftrtrtmnt1IntakeGasSensorAtTemp 3 "Not available" 2 "Error" 1 "In range" 0 "Not in range" ;
VAL_ 2565869310 Aftrtrtmnt1IntkGsSnsrPowerStatus 3 "Not available" 2 "Error" 1 "In range" 0 "Not in range" ;
VAL_ 2631728894 AntitheftModifyPwdStates 3 "Notvalid" 2 "EmptyOfPwdsThsSttIndctsThtCmpnn" 1 "FullofPwds" 0 "OkThsSttIndctsThtRqWsSccssfllyP" ;
VAL_ 2631728894 AntitheftComponentStatusStates 3 "Not defined" 2 "Blocked" 1 "Locked" 0 "Unlocked" ;
VAL_ 2631728894 AntitheftPwdValidIndicator 3 "Not available" 2 "Error" 1 "Password is a validated password" 0 "Password is not a validated password" ;
VAL_ 2631728894 AntthftEncryptnSdPrsentIndicator 3 "Not available" 2 "Error" 1 "Random number is present" 0 "Random number is not present" ;
VAL_ 2631794430 AntitheftCmdStates 5 "Login" 4 "CheckStatus" 3 "LockorUnlock" 2 "ChangePassword" 1 "DeletePassword" 0 "AddPassword" ;
VAL_ 2631794430 AntitheftDesiredExitModeStates 3 "NotAvailable" 2 "Not defined" 1 "LockWhenKeyOff" 0 "LockUponOperatorRequest" ;
VAL_ 2631794430 AntthftEncryptionIndicatorStates 3 "NotAvailable" 2 "Not defined" 1 "EncryptedCodePresent" 0 "EncryptionSeedRequest" ;
VAL_ 2365478910 ElctrncShckAbsrbrCtrlMdLft_TgAxl 3 "Not available" 2 "Error" 1 "Normal operation dampers active" 0 "Normal operation dampers passive" ;
VAL_ 2365478910 ElctrncShckAbsrbrCtrlMdeRearAxle 3 "Not available" 2 "Error" 1 "Normal operation dampers active" 0 "Normal operation dampers passive" ;
VAL_ 2365478910 ElctrncShckAbsrbrCtrlMdFrontAxle 3 "Not available" 2 "Error" 1 "Normal operation dampers active" 0 "Normal operation dampers passive" ;
VAL_ 2560950014 FailureModeIdentifier1 31 "Not available" 19 "Received network data in error" 18 "Below normal (moderately severe)" 17 "Below normal (least severe)" 16 "Above normal (moderately severe)" 15 "Above normal (least severe)" 14 "Special intstructions" 13 "Out of calibration" 12 "Bad intelligent device" 11 "Root cause not known" 10 "Abnormal rate of change" 9 "Abnormal update rate" 8 "Abnormal frequency" 7 "Mechanical system not responding" 6 "Current above normal" 5 "Current below normal" 4 "Voltage below normal" 3 "Voltage above normal" 2 "Data erratic" 1 "Below normal (most severe)" 0 "Above normal (most severe)" ;
VAL_ 2565869566 NOxSensorATI1SelfdiagnosisStatus 7 "Not Supported" 5 "110 Reserved" 4 "NOx Sensor ATI1 Self Diagnosis not possible" 3 "NOx Sensor ATI1 Self Diagnosis aborted" 2 "NOx Sensor ATI1 Self Diagnosis Result Complete" 1 "NOx Sensor ATI1 Self Diagnosis active flag" 0 "Diagnosis not active" ;
VAL_ 2565869566 Aftrtrtmnt1OtltGsSnsorHeaterCtrl 3 "Heater off" 2 "Preheat 1" 1 "Preheat 2" 0 "Automatic" ;
VAL_ 2565869566 Aftrtrtmnt1OtltWdRngO2RdngStable 3 "Not available" 2 "Error" 1 "Stable" 0 "Not stable" ;
VAL_ 2565869566 Aftrtrtmnt1OtletNOxReadingStable 3 "Not available" 2 "Error" 1 "Stable" 0 "Not stable" ;
VAL_ 2565869566 Aftrtrtmnt1OutletGasSensorAtTemp 3 "Not available" 2 "Error" 1 "In range" 0 "Not in range" ;
VAL_ 2565869566 Aftrtrtmnt1OtltGsSnsrPowerStatus 3 "Not available" 2 "Error" 1 "In range" 0 "Not in range" ;
VAL_ 2566758142 Aftertreatment2AirEnableActuator 3 "not available" 2 "reserved for SAE assignment" 1 "active" 0 "not active" ;
VAL_ 2566758142 Aftertreatment2PurgeAirActuator 3 "not available" 2 "reserved for SAE assignment" 1 "active" 0 "not active" ;
VAL_ 2566758142 Aftrtrtmnt2AtmizationAirActuator 3 "not available" 2 "reserved for SAE assignment" 1 "active" 0 "not active" ;
VAL_ 2566758142 Aftertreatment2AirSystemRelay 3 "not available" 2 "reserved for SAE assignment" 1 "active" 0 "not active" ;
VAL_ 2566758654 Aftrtreatment2FuelEnableActuator 3 "not available" 2 "reserved for SAE assignment" 1 "active" 0 "not active" ;
VAL_ 2566758654 Aftrtreatment2RegenerationStatus 3 "not available" 2 "reserved for SAE assignment" 1 "active" 0 "not active" ;
VAL_ 2566758654 Aftertreatment2Ignt 3 "not available" 2 "reserved for SAE assignment" 1 "active" 0 "not active" ;
VAL_ 2566758654 Aftertreatment2FuelDrainActuator 3 "not available" 2 "reserved for SAE assignment" 1 "active" 0 "not active" ;
